VERSION ""

NS_ :

BS_:

BU_: BMS ECC EVBUS_Virtual_ECU GW OBC VCU

BO_ 870 MCU_R_0x366: 8 GW
 SG_ MCU_R_SecuStsChkFlt : 1|1@0+ (1,0) [0|1] ""  EVBUS_Virtual_ECU
 SG_ MCU_R_HVActvDchaFlt : 2|1@0+ (1,0) [0|1] ""  EVBUS_Virtual_ECU
 SG_ MCU_R_CtrlPanTChkCircFlt : 6|1@0+ (1,0) [0|1] ""  EVBUS_Virtual_ECU
 SG_ MCU_R_ComLostFlt_VCU : 7|1@0+ (1,0) [0|1] ""  EVBUS_Virtual_ECU
 SG_ MCU_R_E2EFlt : 8|1@0+ (1,0) [0|1] ""  EVBUS_Virtual_ECU
 SG_ MCU_R_I2TFlt : 9|1@0+ (1,0) [0|1] ""  EVBUS_Virtual_ECU
 SG_ MCU_R_OperModFlt : 10|1@0+ (1,0) [0|1] ""  EVBUS_Virtual_ECU
 SG_ MCU_R_CooltOverTFlt : 11|1@0+ (1,0) [0|1] ""  EVBUS_Virtual_ECU
 SG_ MCU_R_PhaCrtSampleCircFltU : 17|1@0+ (1,0) [0|1] ""  EVBUS_Virtual_ECU
 SG_ MCU_R_PhaCrtSampleCircFltV : 19|1@0+ (1,0) [0|1] ""  EVBUS_Virtual_ECU
 SG_ MCU_R_PhaCrtSampleCircFltW : 20|1@0+ (1,0) [0|1] ""  EVBUS_Virtual_ECU
 SG_ MCU_R_ThreePhaCrtChkFlt : 21|1@0+ (1,0) [0|1] ""  EVBUS_Virtual_ECU
 SG_ MCU_R_DCBusUnderVoltFlt : 22|1@0+ (1,0) [0|1] ""  EVBUS_Virtual_ECU
 SG_ MCU_R_DCBusOverVoltFlt : 23|1@0+ (1,0) [0|1] ""  EVBUS_Virtual_ECU
 SG_ MCU_R_PosnSnsrChkCircFlt : 25|1@0+ (1,0) [0|1] ""  EVBUS_Virtual_ECU
 SG_ MCU_R_DCBusVoltSampleCircFlt : 26|1@0+ (1,0) [0|1] ""  EVBUS_Virtual_ECU
 SG_ MCU_R_OverSpdFlt : 27|1@0+ (1,0) [0|1] ""  EVBUS_Virtual_ECU
 SG_ MCU_R_IGBTOverTFltU : 28|1@0+ (1,0) [0|1] ""  ECC
 SG_ MCU_R_IGBTTChkCircFltU : 29|1@0+ (1,0) [0|1] ""  ECC
 SG_ MCU_R_IGBTTChkCircFltV : 32|1@0+ (1,0) [0|1] ""  ECC
 SG_ MCU_R_IGBTTChkCircFltW : 33|1@0+ (1,0) [0|1] ""  ECC
 SG_ MCU_R_OverTFlt : 34|1@0+ (1,0) [0|1] ""  ECC
 SG_ MCU_R_TChkCircFlt : 35|1@0+ (1,0) [0|1] ""  ECC
 SG_ MCU_R_CtrlPanOverTFlt : 36|1@0+ (1,0) [0|1] ""  ECC
 SG_ MCU_R_LVPwrSplyUnderVoltFlt : 38|1@0+ (1,0) [0|1] ""  EVBUS_Virtual_ECU
 SG_ MCU_R_LVPwrSplyOverVoltFlt : 39|1@0+ (1,0) [0|1] ""  EVBUS_Virtual_ECU
 SG_ MCU_R_FbTqStsChkFlt : 40|1@0+ (1,0) [0|1] ""  EVBUS_Virtual_ECU
 SG_ MCU_R_PhaCrtSwOverCrtFltU : 42|1@0+ (1,0) [0|1] ""  EVBUS_Virtual_ECU
 SG_ MCU_R_TqCmdOverLimFlt : 43|1@0+ (1,0) [0|1] ""  ECC
 SG_ MCU_R_PwrSplyModFlt : 44|1@0+ (1,0) [0|1] ""  EVBUS_Virtual_ECU
 SG_ MCU_R_IGBTThreePhaTChkFlt : 45|1@0+ (1,0) [0|1] ""  EVBUS_Virtual_ECU
 SG_ MCU_R_RotCalFlt : 46|1@0+ (1,0) [0|1] ""  EVBUS_Virtual_ECU
 SG_ MCU_R_IntComFlt : 47|1@0+ (1,0) [0|1] ""  EVBUS_Virtual_ECU
 SG_ MCU_R_IntTqChkFlt : 48|1@0+ (1,0) [0|1] ""  EVBUS_Virtual_ECU
 SG_ MCU_R_IGBTDesatFltTop : 49|1@0+ (1,0) [0|1] ""  EVBUS_Virtual_ECU
 SG_ MCU_R_IGBTDesatFltBot : 50|1@0+ (1,0) [0|1] ""  EVBUS_Virtual_ECU
 SG_ MCU_R_PhaCrtSwOverCrtFltV : 52|1@0+ (1,0) [0|1] ""  EVBUS_Virtual_ECU
 SG_ MCU_R_PhaCrtSwOverCrtFltW : 53|1@0+ (1,0) [0|1] ""  EVBUS_Virtual_ECU
 SG_ MCU_R_IGBTOverTFltV : 54|1@0+ (1,0) [0|1] ""  EVBUS_Virtual_ECU
 SG_ MCU_R_IGBTOverTFltW : 55|1@0+ (1,0) [0|1] ""  EVBUS_Virtual_ECU

BO_ 880 BMS_HVBatt_Status_Errors_3_TBOX: 8 BMS
 SG_ BMS_PwrBattOverChrgAlrm : 0|1@0+ (1,0) [0|1] ""  GW,VCU
 SG_ BMS_PwrBattUderVoltFlt : 1|1@0+ (1,0) [0|1] ""  GW,VCU
 SG_ BMS_CellUnderVoltFailFlt : 2|1@0+ (1,0) [0|1] ""  GW,VCU
 SG_ BMS_CellUnderVoltFlt : 3|1@0+ (1,0) [0|1] ""  GW,VCU
 SG_ BMS_BattBalActv : 4|1@0+ (1,0) [0|1] ""  GW,VCU
 SG_ BMS_BattPack1OverVoltFlt : 5|1@0+ (1,0) [0|1] ""  GW,VCU
 SG_ BMS_BattPack1UnderVoltFlt : 6|1@0+ (1,0) [0|1] ""  GW,VCU
 SG_ BMS_DCChrgSoktOverTFlt : 7|1@0+ (1,0) [0|1] ""  GW,VCU
 SG_ BMS_ComLostFlt_BOBC : 8|1@0+ (1,0) [0|1] ""  GW,VCU
 SG_ BMS_ComLostFlt_CCU : 9|1@0+ (1,0) [0|1] ""  GW,VCU
 SG_ BMS_ACChrgSoktOverTFlt : 10|1@0+ (1,0) [0|1] ""  GW,VCU
 SG_ BMS_ACCrtFlt : 11|1@0+ (1,0) [0|1] ""  GW,VCU
 SG_ BMS_InsulChkFltLvl2ProtFlg : 12|1@0+ (1,0) [0|1] ""  GW,VCU
 SG_ BMS_PwrBattOverTAlrm : 13|1@0+ (1,0) [0|1] ""  GW,VCU
 SG_ BMS_PwrBattHLVIntlkFlt : 15|1@0+ (1,0) [0|1] ""  GW,VCU
 SG_ BMS_PwrBattExtShoCirc : 16|1@0+ (1,0) [0|1] ""  GW,VCU
 SG_ BMS_PwrBattIntShoCirc : 17|1@0+ (1,0) [0|1] ""  GW,VCU
 SG_ BMS_PwrBattTUnbal : 18|1@0+ (1,0) [0|1] ""  GW,VCU
 SG_ BMS_PwrBattTRiseFast : 19|1@0+ (1,0) [0|1] ""  GW,VCU
 SG_ BMS_PwrBattIntTotVoltChkFlt : 20|1@0+ (1,0) [0|1] ""  GW,VCU
 SG_ BMS_PwrBattExtTotVoltChkFlt : 21|1@0+ (1,0) [0|1] ""  GW,VCU
 SG_ BMS_PwrBattNegRlyAdh : 22|1@0+ (1,0) [0|1] ""  GW,VCU
 SG_ BMS_PwrBattPrecRlyAdh : 23|1@0+ (1,0) [0|1] ""  GW,VCU
 SG_ BMS_PwrBattPosRlyAdh : 24|1@0+ (1,0) [0|1] ""  GW,VCU
 SG_ BMS_PwrBattNegRlyBreak : 25|1@0+ (1,0) [0|1] ""  GW,VCU
 SG_ BMS_PwrBattPrecRlyBreak : 26|1@0+ (1,0) [0|1] ""  GW,VCU
 SG_ BMS_PwrBattPosRlyBreak : 27|1@0+ (1,0) [0|1] ""  GW,VCU
 SG_ BMS_PwrBattPrecRBreak : 28|1@0+ (1,0) [0|1] ""  GW,VCU
 SG_ BMS_PwrBattMSDBreak : 29|1@0+ (1,0) [0|1] ""  GW,VCU
 SG_ BMS_PwrBattExtTotVoltChkFltV2 : 30|1@0+ (1,0) [0|1] ""  GW,VCU
 SG_ BMS_BCUEEPROMReadWrFlt : 31|1@0+ (1,0) [0|1] ""  GW,VCU
 SG_ BMS_PwrBattPosRlyDrvChFlt : 32|1@0+ (1,0) [0|1] ""  GW,VCU
 SG_ BMS_PwrBattPrecRlyDrvChFlt : 33|1@0+ (1,0) [0|1] ""  GW,VCU
 SG_ BMS_PwrBattInsulChkFlt : 34|1@0+ (1,0) [0|1] ""  GW,VCU
 SG_ BMS_PwrBattNegRlyDrvChFlt : 35|1@0+ (1,0) [0|1] ""  GW,VCU
 SG_ BMS_PwrBattCellVoltUnbal : 36|1@0+ (1,0) [0|1] ""  GW,VCU
 SG_ BMS_EEPROMReadWrFlt : 37|1@0+ (1,0) [0|1] ""  GW,VCU
 SG_ BMS_PwrBattSysIntComFlt : 39|2@0+ (1,0) [0|3] ""  GW,VCU
 SG_ BMS_InsulRLo : 40|1@0+ (1,0) [0|1] ""  GW,VCU
 SG_ BMS_CopRowLooseFlt : 41|1@0+ (1,0) [0|1] ""  GW,VCU
 SG_ BMS_SubEEPROMReadWrFlt : 42|1@0+ (1,0) [0|1] ""  GW,VCU
 SG_ BMS_SubCellVoltCollctnCircFlt : 44|2@0+ (1,0) [0|3] ""  GW,VCU
 SG_ BMS_SubModleVoltCollctnCircFlt : 45|1@0+ (1,0) [0|1] ""  GW,VCU
 SG_ BMS_SubTCollctnCircFlt : 47|2@0+ (1,0) [0|3] ""  GW,VCU
 SG_ BMS_SubActvBalChFlt : 48|1@0+ (1,0) [0|1] ""  GW,VCU
 SG_ BMS_SubPasBalChFlt : 49|1@0+ (1,0) [0|1] ""  GW,VCU
 SG_ BMS_SubOperModRespFlt : 50|1@0+ (1,0) [0|1] ""  GW,VCU
 SG_ BMS_BattCellVoltUnbalAlrm : 51|1@0+ (1,0) [0|1] ""  GW,VCU
 SG_ BMS_ComLostFlt_ECC : 52|1@0+ (1,0) [0|1] ""  GW,VCU
 SG_ BMS_SubComLostFlt_VBUBMS : 53|1@0+ (1,0) [0|1] ""  GW,VCU
 SG_ BMS_PrecFailFlt : 54|1@0+ (1,0) [0|1] ""  GW,VCU
 SG_ BMS_PwrBattCellOverVolt : 55|1@0+ (1,0) [0|1] ""  GW,VCU
 SG_ BMS_TotVoltOver : 56|1@0+ (1,0) [0|1] ""  GW,VCU
 SG_ BMS_PwrBattIntTotVoltChkFltV1 : 57|1@0+ (1,0) [0|1] ""  GW,VCU
 SG_ BMS_TotCrtChkFlt : 58|1@0+ (1,0) [0|1] ""  GW,VCU
 SG_ BMS_ComLostFlt_VCU : 59|1@0+ (1,0) [0|1] ""  GW,VCU
 SG_ BMS_BattReDrvHLVIntlkFlt : 60|1@0+ (1,0) [0|1] ""  GW,VCU
 SG_ BMS_ComOverTiFlt_ECC : 61|1@0+ (1,0) [0|1] ""  GW,VCU
 SG_ BMS_LVPwrSplyFlt : 62|1@0+ (1,0) [0|1] ""  GW,VCU
 SG_ BMS_ComOverTiFlt_BOBC : 63|1@0+ (1,0) [0|1] ""  GW,VCU

BO_ 881 WTC_B_0x371: 8 ECC
 SG_ WTC_B_PCBT : 23|8@0+ (1,-48) [-48|207] ""  GW
 SG_ WTC_B_Crt : 31|16@0+ (0.001,0) [0|65.534] "A"  GW,VCU
 SG_ WTC_B_CrtSts : 41|2@0+ (1,0) [0|3] ""  GW,VCU
 SG_ WTC_B_HVIntlkFlt : 42|1@0+ (1,0) [0|1] ""  GW,VCU
 SG_ WTC_B_ComLost_ECC : 43|1@0+ (1,0) [0|1] ""  GW
 SG_ WTC_B_OverCrtFlt : 44|1@0+ (1,0) [0|1] ""  GW
 SG_ WTC_B_HVUnderVoltFlt : 45|1@0+ (1,0) [0|1] ""  GW
 SG_ WTC_B_HVOverVoltFlt : 46|1@0+ (1,0) [0|1] ""  GW
 SG_ WTC_B_ChkBattOverVoltFlt : 47|1@0+ (1,0) [0|1] ""  GW
 SG_ WTC_B_ChkBattUnderVoltFlt : 48|1@0+ (1,0) [0|1] ""  GW
 SG_ WTC_B_InlTSnsrFlt : 49|1@0+ (1,0) [0|1] ""  GW
 SG_ WTC_B_OutlTSnsrFlt : 50|1@0+ (1,0) [0|1] ""  GW
 SG_ WTC_B_InlOverTFlt : 51|1@0+ (1,0) [0|1] ""  GW
 SG_ WTC_B_OutlOverTFlt : 52|1@0+ (1,0) [0|1] ""  GW
 SG_ WTC_B_PCBOverTFlt : 53|1@0+ (1,0) [0|1] ""  GW
 SG_ WTC_B_PCBTSnsrFlt : 54|1@0+ (1,0) [0|1] ""  GW
 SG_ WTC_B_PwrOutpFlt : 55|1@0+ (1,0) [0|1] ""  GW

BO_ 882 BMS_CellTemp_CoolingHeating: 16 BMS
 SG_ BMS_372_382_CheckSum : 7|8@0+ (1,0) [0|255] ""  ECC,GW,VCU
 SG_ BMS_372_382_AliveCounter : 11|4@0+ (1,0) [0|14] ""  ECC,GW,VCU
 SG_ BMS_OTARdy_Fb : 13|2@0+ (1,0) [0|3] ""  GW
 SG_ BMS_CellMinT : 23|8@0+ (1,-48) [-48|207] "Degree Celsius"  ECC,GW,VCU
 SG_ BMS_CellDiffT : 31|8@0+ (1,0) [0|255] "Degree Celsius"  ECC,GW,VCU
 SG_ BMS_CellMaxT : 39|8@0+ (1,-48) [-48|207] "Degree Celsius"  ECC,GW,VCU
 SG_ BMS_BattAvrgT : 47|8@0+ (1,-48) [-48|207] "Degree Celsius"  ECC,GW,VCU
 SG_ BMS_PwrBattHeatgMngDmd : 49|2@0+ (1,0) [0|3] ""  ECC,GW,VCU
 SG_ BMS_ECCSysAllwDwnPwrCmd : 50|1@0+ (1,0) [0|1] ""  ECC,GW
 SG_ BMS_BattInlTDmd : 63|8@0+ (1,-48) [-48|207] ""  ECC,GW
 SG_ BMS_372_SSecOC_Fresh_Byte0 : 71|8@0+ (1,0) [0|255] ""  GW,VCU
 SG_ BMS_372_SSecOC_MAC_Byte0 : 79|8@0+ (1,0) [0|255] ""  GW,VCU
 SG_ BMS_372_SSecOC_MAC_Byte1 : 87|8@0+ (1,0) [0|255] ""  GW,VCU
 SG_ BMS_372_SSecOC_MAC_Byte2 : 95|8@0+ (1,0) [0|255] ""  GW,VCU

BO_ 883 ECC_0x373: 8 ECC
 SG_ ECC_CrtSts : 3|4@0+ (1,0) [0|15] ""  GW,VCU
 SG_ ECC_IninSts : 4|1@0+ (1,0) [0|1] ""  GW,VCU
 SG_ ECC_PwrSysHeatMngtSts : 6|2@0+ (1,0) [0|3] ""  GW,VCU
 SG_ ECC_ACSts : 7|1@0+ (1,0) [0|1] ""  GW,VCU
 SG_ ECC_AirClnSts : 8|1@0+ (1,0) [0|1] ""  GW,VCU
 SG_ ECC_WindSpdSts : 12|4@0+ (1,0) [0|15] ""  BMS,GW,VCU
 SG_ ECC_BackRowAirOutlModSts : 15|3@0+ (1,0) [0|7] ""  GW,VCU
 SG_ ECC_DrvrTSetSts : 23|8@0+ (0.5,0) [0|127.5] ""  GW,VCU
 SG_ ECC_PassTSetSts : 31|8@0+ (0.5,0) [0|127.5] ""  GW,VCU
 SG_ ECC_HeatSts : 32|1@0+ (1,0) [0|1] ""  BMS,GW,VCU
 SG_ ECC_AUTOSts : 33|1@0+ (1,0) [0|1] ""  GW,VCU
 SG_ ECC_SYNCSts : 34|1@0+ (1,0) [0|1] ""  GW,VCU
 SG_ ECC_InfoSysWrmColdDisp : 36|2@0+ (1,0) [0|3] ""  GW,VCU
 SG_ ECC_CircSts : 37|1@0+ (1,0) [0|1] ""  GW,VCU
 SG_ ECC_ParticleConcVld : 39|2@0+ (1,0) [0|3] ""  GW,VCU
 SG_ ECC_OutdT : 47|8@0+ (0.5,-48) [-48|79.5] "Degree Celsius"  BMS,GW,VCU
 SG_ ECC_OutdTVld : 49|2@0+ (1,0) [0|3] ""  BMS,GW,VCU
 SG_ ECC_MaxFrntDefrst : 50|1@0+ (1,0) [0|1] ""  GW,VCU
 SG_ ECC_HeatMngtSysFlt : 51|1@0+ (1,0) [0|1] ""  GW,VCU
 SG_ ECC_HeatMngtFctLim : 52|1@0+ (1,0) [0|1] ""  GW,VCU
 SG_ ECC_DrvrAirOutlMod : 55|3@0+ (1,0) [0|7] ""  GW,VCU
 SG_ ECC_PassAirOutlMod : 58|3@0+ (1,0) [0|7] ""  GW,VCU
 SG_ ECC_RemSts : 60|2@0+ (1,0) [0|3] ""  GW,VCU
 SG_ ECC_OTAInhbRdy : 62|2@0+ (1,0) [0|3] ""  GW,VCU

BO_ 884 WTC_H_0x374: 8 ECC
 SG_ WTC_H_PCBT : 23|8@0+ (1,-48) [-48|207] ""  GW
 SG_ WTC_H_Crt : 31|16@0+ (0.001,0) [0|65.534] "A"  GW,VCU
 SG_ WTC_H_CrtSts : 41|2@0+ (1,0) [0|3] ""  GW,VCU
 SG_ WTC_H_HVIntlkFlt : 42|1@0+ (1,0) [0|1] ""  GW,VCU
 SG_ WTC_H_ComLost_ECC : 43|1@0+ (1,0) [0|1] ""  GW
 SG_ WTC_H_OverCrtFlt : 44|1@0+ (1,0) [0|1] ""  GW
 SG_ WTC_H_HVUnderVoltFlt : 45|1@0+ (1,0) [0|1] ""  GW
 SG_ WTC_H_HVOverVoltFlt : 46|1@0+ (1,0) [0|1] ""  GW
 SG_ WTC_H_ChkBattOverVoltFlt : 47|1@0+ (1,0) [0|1] ""  GW
 SG_ WTC_H_ChkBattUnderVoltFlt : 48|1@0+ (1,0) [0|1] ""  GW
 SG_ WTC_H_InlTSnsrFlt : 49|1@0+ (1,0) [0|1] ""  GW
 SG_ WTC_H_OutlTSnsrFlt : 50|1@0+ (1,0) [0|1] ""  GW
 SG_ WTC_H_InlOverTFlt : 51|1@0+ (1,0) [0|1] ""  GW
 SG_ WTC_H_OutlOverTFlt : 52|1@0+ (1,0) [0|1] ""  GW
 SG_ WTC_H_PCBOverTFlt : 53|1@0+ (1,0) [0|1] ""  GW
 SG_ WTC_H_PCBTSnsrFlt : 54|1@0+ (1,0) [0|1] ""  GW
 SG_ WTC_H_PwrOutpFlt : 55|1@0+ (1,0) [0|1] ""  GW

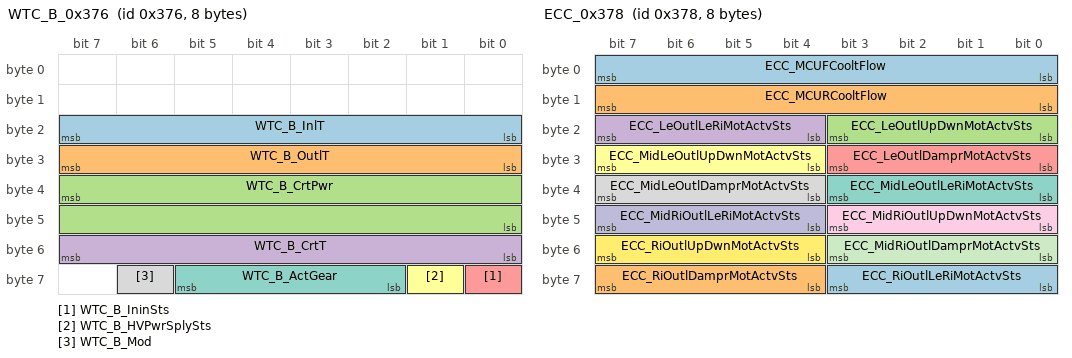
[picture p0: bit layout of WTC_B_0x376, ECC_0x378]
BO_ 886 WTC_B_0x376: 8 ECC
 SG_ WTC_B_InlT : 23|8@0+ (1,-48) [-48|207] "Degree Celsius"  GW
 SG_ WTC_B_OutlT : 31|8@0+ (1,-48) [-48|207] "Degree Celsius"  GW
 SG_ WTC_B_CrtPwr : 39|16@0+ (1,0) [0|10000] ""  GW,VCU
 SG_ WTC_B_CrtT : 55|8@0+ (1,-48) [-48|207] "Degree Celsius"  GW
 SG_ WTC_B_IninSts : 56|1@0+ (1,0) [0|1] ""  GW
 SG_ WTC_B_HVPwrSplySts : 57|1@0+ (1,0) [0|1] ""  GW
 SG_ WTC_B_ActGear : 61|4@0+ (1,0) [0|15] ""  GW
 SG_ WTC_B_Mod : 62|1@0+ (1,0) [0|1] ""  BMS,GW,VCU

BO_ 888 ECC_0x378: 8 ECC
 SG_ ECC_MCUFCooltFlow : 7|8@0+ (0.1,0) [0|25.5] "L/min"  GW
 SG_ ECC_MCURCooltFlow : 15|8@0+ (0.1,0) [0|25.5] "L/min"  GW
 SG_ ECC_LeOutlUpDwnMotActvSts : 19|4@0+ (1,0) [0|15] ""  GW
 SG_ ECC_LeOutlLeRiMotActvSts : 23|4@0+ (1,0) [0|15] ""  GW
 SG_ ECC_LeOutlDamprMotActvSts : 27|4@0+ (1,0) [0|15] ""  GW
 SG_ ECC_MidLeOutlUpDwnMotActvSts : 31|4@0+ (1,0) [0|15] ""  GW
 SG_ ECC_MidLeOutlLeRiMotActvSts : 35|4@0+ (1,0) [0|15] ""  GW
 SG_ ECC_MidLeOutlDamprMotActvSts : 39|4@0+ (1,0) [0|15] ""  GW
 SG_ ECC_MidRiOutlUpDwnMotActvSts : 43|4@0+ (1,0) [0|15] ""  GW
 SG_ ECC_MidRiOutlLeRiMotActvSts : 47|4@0+ (1,0) [0|15] ""  GW
 SG_ ECC_MidRiOutlDamprMotActvSts : 51|4@0+ (1,0) [0|15] ""  GW
 SG_ ECC_RiOutlUpDwnMotActvSts : 55|4@0+ (1,0) [0|15] ""  GW
 SG_ ECC_RiOutlLeRiMotActvSts : 59|4@0+ (1,0) [0|15] ""  GW
 SG_ ECC_RiOutlDamprMotActvSts : 63|4@0+ (1,0) [0|15] ""  GW

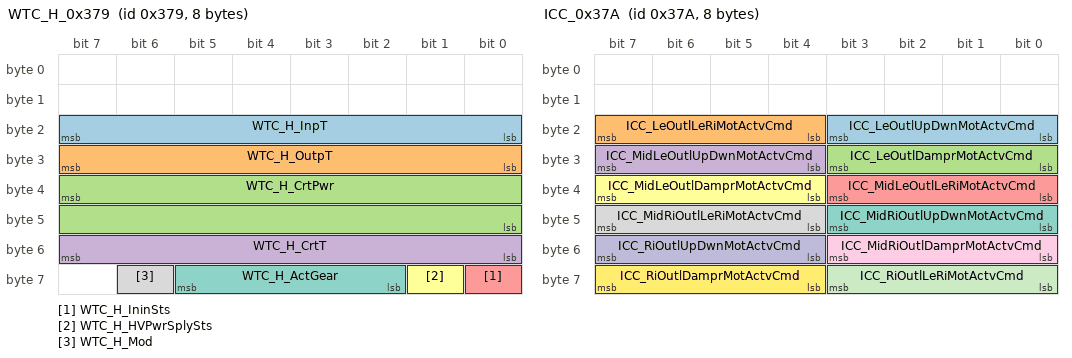
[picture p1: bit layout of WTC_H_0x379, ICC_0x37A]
BO_ 889 WTC_H_0x379: 8 ECC
 SG_ WTC_H_InpT : 23|8@0+ (1,-48) [-48|207] "Degree Celsius"  GW
 SG_ WTC_H_OutpT : 31|8@0+ (1,-48) [-48|207] "Degree Celsius"  GW
 SG_ WTC_H_CrtPwr : 39|16@0+ (1,0) [0|10000] ""  GW,VCU
 SG_ WTC_H_CrtT : 55|8@0+ (1,-48) [-48|207] "Degree Celsius"  GW
 SG_ WTC_H_IninSts : 56|1@0+ (1,0) [0|1] ""  GW
 SG_ WTC_H_HVPwrSplySts : 57|1@0+ (1,0) [0|1] ""  GW
 SG_ WTC_H_ActGear : 61|4@0+ (1,0) [0|15] ""  GW
 SG_ WTC_H_Mod : 62|1@0+ (1,0) [0|1] ""  BMS,GW,VCU

BO_ 890 ICC_0x37A: 8 GW
 SG_ ICC_LeOutlUpDwnMotActvCmd : 19|4@0+ (1,0) [0|15] ""  ECC
 SG_ ICC_LeOutlLeRiMotActvCmd : 23|4@0+ (1,0) [0|15] ""  ECC
 SG_ ICC_LeOutlDamprMotActvCmd : 27|4@0+ (1,0) [0|15] ""  ECC
 SG_ ICC_MidLeOutlUpDwnMotActvCmd : 31|4@0+ (1,0) [0|15] ""  ECC
 SG_ ICC_MidLeOutlLeRiMotActvCmd : 35|4@0+ (1,0) [0|15] ""  ECC
 SG_ ICC_MidLeOutlDamprMotActvCmd : 39|4@0+ (1,0) [0|15] ""  ECC
 SG_ ICC_MidRiOutlUpDwnMotActvCmd : 43|4@0+ (1,0) [0|15] ""  ECC
 SG_ ICC_MidRiOutlLeRiMotActvCmd : 47|4@0+ (1,0) [0|15] ""  ECC
 SG_ ICC_MidRiOutlDamprMotActvCmd : 51|4@0+ (1,0) [0|15] ""  ECC
 SG_ ICC_RiOutlUpDwnMotActvCmd : 55|4@0+ (1,0) [0|15] ""  ECC
 SG_ ICC_RiOutlLeRiMotActvCmd : 59|4@0+ (1,0) [0|15] ""  ECC
 SG_ ICC_RiOutlDamprMotActvCmd : 63|4@0+ (1,0) [0|15] ""  ECC

BO_ 891 PKC_0x37B: 16 GW
 SG_ PKC_SysAlrmVld : 16|1@0+ (1,0) [0|1] ""  EVBUS_Virtual_ECU
 SG_ PKC_RemCtrlCmdFb : 18|2@0+ (1,0) [0|3] ""  EVBUS_Virtual_ECU
 SG_ PKC_RemLockCmd_Key : 22|4@0+ (1,0) [0|15] ""  ECC,VCU
 SG_ PKC_KeyStsMod : 23|1@0+ (1,0) [0|1] ""  EVBUS_Virtual_ECU
 SG_ PKC_KeyID : 31|8@0+ (1,0) [0|255] ""  EVBUS_Virtual_ECU
 SG_ PKC_KeyInCarRmn : 35|1@0+ (1,0) [0|1] ""  EVBUS_Virtual_ECU
 SG_ PKC_RemLockCmd : 39|4@0+ (1,0) [0|15] ""  VCU
 SG_ PKC_BatterySts : 45|2@0+ (1,0) [0|3] ""  EVBUS_Virtual_ECU
 SG_ PKC_KeyOutdCarPromt : 46|1@0+ (1,0) [0|1] ""  EVBUS_Virtual_ECU
 SG_ PKC_DoorOpenRmd : 49|2@0+ (1,0) [0|3] ""  EVBUS_Virtual_ECU
 SG_ PKC_StrtFailTyp : 53|4@0+ (1,0) [0|15] ""  EVBUS_Virtual_ECU
 SG_ PKC_LockKeyInCarInd : 55|2@0+ (1,0) [0|3] ""  EVBUS_Virtual_ECU
 SG_ PKC_KeySts : 63|8@0+ (1,0) [0|255] ""  EVBUS_Virtual_ECU
 SG_ PKC_37B_SSecOC_Fresh_Byte0 : 71|8@0+ (1,0) [0|255] ""  VCU
 SG_ PKC_37B_SSecOC_MAC_Byte0 : 79|8@0+ (1,0) [0|255] ""  VCU
 SG_ PKC_37B_SSecOC_MAC_Byte1 : 87|8@0+ (1,0) [0|255] ""  VCU
 SG_ PKC_37B_SSecOC_MAC_Byte2 : 95|8@0+ (1,0) [0|255] ""  VCU

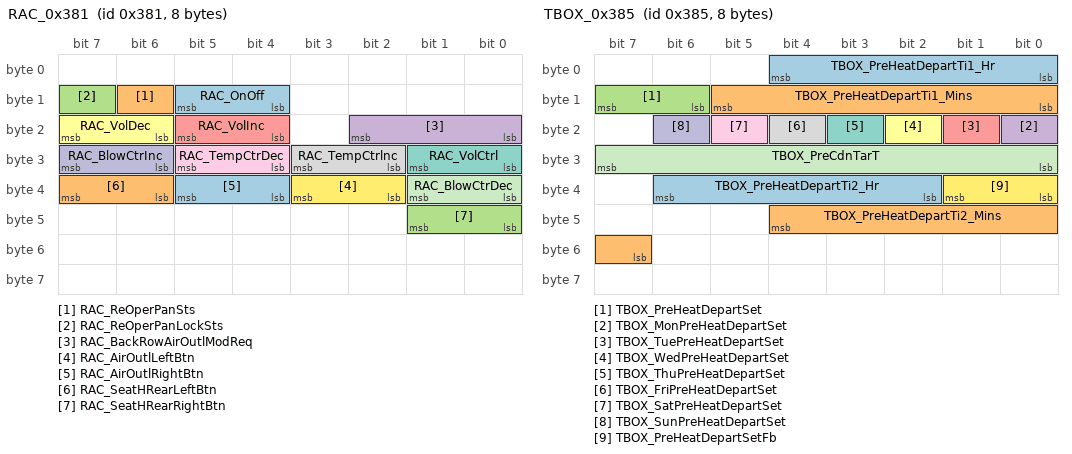
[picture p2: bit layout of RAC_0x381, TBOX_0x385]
BO_ 897 RAC_0x381: 8 GW
 SG_ RAC_OnOff : 13|2@0+ (1,0) [0|3] ""  EVBUS_Virtual_ECU
 SG_ RAC_ReOperPanSts : 14|1@0+ (1,0) [0|1] ""  ECC
 SG_ RAC_ReOperPanLockSts : 15|1@0+ (1,0) [0|1] ""  ECC
 SG_ RAC_BackRowAirOutlModReq : 18|3@0+ (1,0) [0|7] ""  ECC
 SG_ RAC_VolInc : 21|2@0+ (1,0) [0|3] ""  EVBUS_Virtual_ECU
 SG_ RAC_VolDec : 23|2@0+ (1,0) [0|3] ""  EVBUS_Virtual_ECU
 SG_ RAC_VolCtrl : 25|2@0+ (1,0) [0|3] ""  EVBUS_Virtual_ECU
 SG_ RAC_TempCtrlnc : 27|2@0+ (1,0) [0|3] ""  EVBUS_Virtual_ECU
 SG_ RAC_TempCtrDec : 29|2@0+ (1,0) [0|3] ""  EVBUS_Virtual_ECU
 SG_ RAC_BlowCtrInc : 31|2@0+ (1,0) [0|3] ""  EVBUS_Virtual_ECU
 SG_ RAC_BlowCtrDec : 33|2@0+ (1,0) [0|3] ""  EVBUS_Virtual_ECU
 SG_ RAC_AirOutlLeftBtn : 35|2@0+ (1,0) [0|3] ""  EVBUS_Virtual_ECU
 SG_ RAC_AirOutlRightBtn : 37|2@0+ (1,0) [0|3] ""  EVBUS_Virtual_ECU
 SG_ RAC_SeatHRearLeftBtn : 39|2@0+ (1,0) [0|3] ""  EVBUS_Virtual_ECU
 SG_ RAC_SeatHRearRightBtn : 41|2@0+ (1,0) [0|3] ""  EVBUS_Virtual_ECU

BO_ 901 TBOX_0x385: 8 GW
 SG_ TBOX_PreHeatDepartTi1_Hr : 4|5@0+ (1,0) [0|23] ""  EVBUS_Virtual_ECU
 SG_ TBOX_PreHeatDepartTi1_Mins : 13|6@0+ (1,0) [0|59] ""  EVBUS_Virtual_ECU
 SG_ TBOX_PreHeatDepartSet : 15|2@0+ (1,0) [0|3] ""  EVBUS_Virtual_ECU
 SG_ TBOX_MonPreHeatDepartSet : 16|1@0+ (1,0) [0|1] ""  EVBUS_Virtual_ECU
 SG_ TBOX_TuePreHeatDepartSet : 17|1@0+ (1,0) [0|1] ""  EVBUS_Virtual_ECU
 SG_ TBOX_WedPreHeatDepartSet : 18|1@0+ (1,0) [0|1] ""  EVBUS_Virtual_ECU
 SG_ TBOX_ThuPreHeatDepartSet : 19|1@0+ (1,0) [0|1] ""  EVBUS_Virtual_ECU
 SG_ TBOX_FriPreHeatDepartSet : 20|1@0+ (1,0) [0|1] ""  EVBUS_Virtual_ECU
 SG_ TBOX_SatPreHeatDepartSet : 21|1@0+ (1,0) [0|1] ""  EVBUS_Virtual_ECU
 SG_ TBOX_SunPreHeatDepartSet : 22|1@0+ (1,0) [0|1] ""  EVBUS_Virtual_ECU
 SG_ TBOX_PreCdnTarT : 31|8@0+ (0.5,0) [-48|255] "Degree Celsius"  VCU
 SG_ TBOX_PreHeatDepartSetFb : 33|2@0+ (1,0) [0|3] ""  EVBUS_Virtual_ECU
 SG_ TBOX_PreHeatDepartTi2_Hr : 38|5@0+ (1,0) [0|23] ""  EVBUS_Virtual_ECU
 SG_ TBOX_PreHeatDepartTi2_Mins : 44|6@0+ (1,0) [0|59] ""  EVBUS_Virtual_ECU

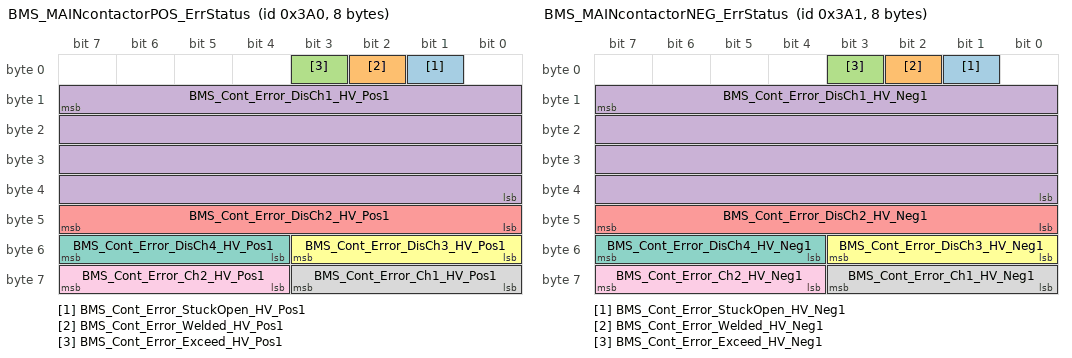
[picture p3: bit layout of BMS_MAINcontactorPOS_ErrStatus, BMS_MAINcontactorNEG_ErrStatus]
BO_ 928 BMS_MAINcontactorPOS_ErrStatus: 8 BMS
 SG_ BMS_Cont_Error_StuckOpen_HV_Pos1 : 1|1@0+ (1,0) [0|1] ""  GW,VCU
 SG_ BMS_Cont_Error_Welded_HV_Pos1 : 2|1@0+ (1,0) [0|1] ""  GW,VCU
 SG_ BMS_Cont_Error_Exceed_HV_Pos1 : 3|1@0+ (1,0) [0|1] ""  GW,VCU
 SG_ BMS_Cont_Error_DisCh1_HV_Pos1 : 15|32@0+ (1,0) [0|4294967295] ""  GW,VCU
 SG_ BMS_Cont_Error_DisCh2_HV_Pos1 : 47|8@0+ (1,0) [0|255] ""  GW,VCU
 SG_ BMS_Cont_Error_DisCh3_HV_Pos1 : 51|4@0+ (1,0) [0|15] ""  GW,VCU
 SG_ BMS_Cont_Error_DisCh4_HV_Pos1 : 55|4@0+ (1,0) [0|15] ""  GW,VCU
 SG_ BMS_Cont_Error_Ch1_HV_Pos1 : 59|4@0+ (1,0) [0|15] ""  GW,VCU
 SG_ BMS_Cont_Error_Ch2_HV_Pos1 : 63|4@0+ (1,0) [0|15] ""  GW,VCU

BO_ 929 BMS_MAINcontactorNEG_ErrStatus: 8 BMS
 SG_ BMS_Cont_Error_StuckOpen_HV_Neg1 : 1|1@0+ (1,0) [0|1] ""  GW,VCU
 SG_ BMS_Cont_Error_Welded_HV_Neg1 : 2|1@0+ (1,0) [0|1] ""  GW,VCU
 SG_ BMS_Cont_Error_Exceed_HV_Neg1 : 3|1@0+ (1,0) [0|1] ""  GW,VCU
 SG_ BMS_Cont_Error_DisCh1_HV_Neg1 : 15|32@0+ (1,0) [0|4294967295] ""  GW,VCU
 SG_ BMS_Cont_Error_DisCh2_HV_Neg1 : 47|8@0+ (1,0) [0|255] ""  GW,VCU
 SG_ BMS_Cont_Error_DisCh3_HV_Neg1 : 51|4@0+ (1,0) [0|15] ""  GW,VCU
 SG_ BMS_Cont_Error_DisCh4_HV_Neg1 : 55|4@0+ (1,0) [0|15] ""  GW,VCU
 SG_ BMS_Cont_Error_Ch1_HV_Neg1 : 59|4@0+ (1,0) [0|15] ""  GW,VCU
 SG_ BMS_Cont_Error_Ch2_HV_Neg1 : 63|4@0+ (1,0) [0|15] ""  GW,VCU

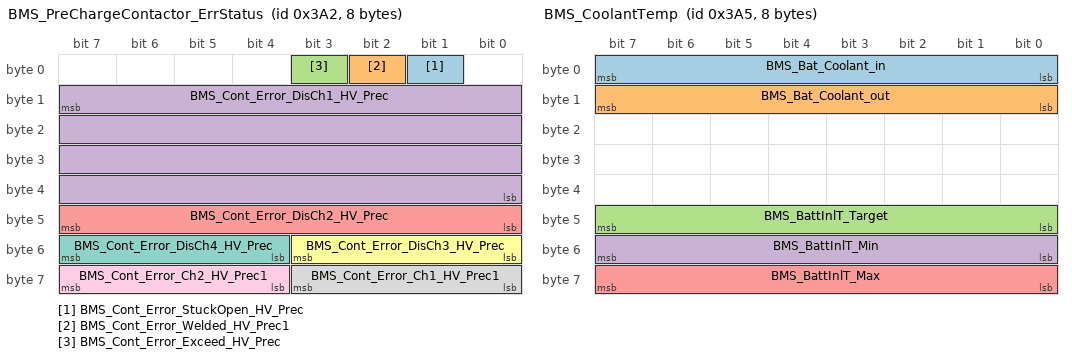
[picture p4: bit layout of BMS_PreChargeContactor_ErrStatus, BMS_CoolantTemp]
BO_ 930 BMS_PreChargeContactor_ErrStatus: 8 BMS
 SG_ BMS_Cont_Error_StuckOpen_HV_Prec : 1|1@0+ (1,0) [0|1] ""  GW,VCU
 SG_ BMS_Cont_Error_Welded_HV_Prec1 : 2|1@0+ (1,0) [0|1] ""  GW,VCU
 SG_ BMS_Cont_Error_Exceed_HV_Prec : 3|1@0+ (1,0) [0|1] ""  GW,VCU
 SG_ BMS_Cont_Error_DisCh1_HV_Prec : 15|32@0+ (1,0) [0|4294967295] ""  GW,VCU
 SG_ BMS_Cont_Error_DisCh2_HV_Prec : 47|8@0+ (1,0) [0|255] ""  GW,VCU
 SG_ BMS_Cont_Error_DisCh3_HV_Prec : 51|4@0+ (1,0) [0|15] ""  GW,VCU
 SG_ BMS_Cont_Error_DisCh4_HV_Prec : 55|4@0+ (1,0) [0|15] ""  GW,VCU
 SG_ BMS_Cont_Error_Ch1_HV_Prec1 : 59|4@0+ (1,0) [0|15] ""  GW,VCU
 SG_ BMS_Cont_Error_Ch2_HV_Prec1 : 63|4@0+ (1,0) [0|15] ""  GW,VCU

BO_ 933 BMS_CoolantTemp: 8 BMS
 SG_ BMS_Bat_Coolant_in : 7|8@0+ (0.5,-40) [-40|87.5] "Degree Celsius"  ECC,GW,VCU
 SG_ BMS_Bat_Coolant_out : 15|8@0+ (0.5,-40) [-40|87.5] "Degree Celsius"  ECC,GW,VCU
 SG_ BMS_BattInlT_Target : 47|8@0+ (1,-48) [-48|207] "Degree Celsius"  ECC,GW,VCU
 SG_ BMS_BattInlT_Min : 55|8@0+ (1,-48) [-48|207] "Degree Celsius"  ECC,GW,VCU
 SG_ BMS_BattInlT_Max : 63|8@0+ (1,-48) [-48|207] "Degree Celsius"  ECC,GW,VCU

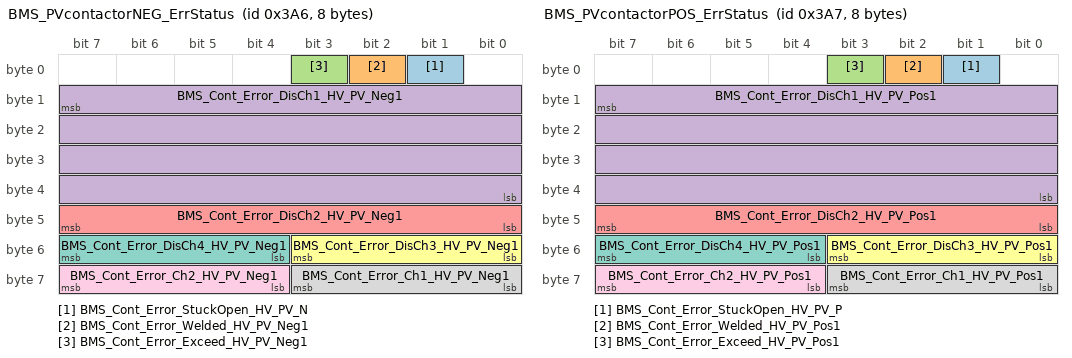
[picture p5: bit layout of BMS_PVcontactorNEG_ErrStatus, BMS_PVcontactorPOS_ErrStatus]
BO_ 934 BMS_PVcontactorNEG_ErrStatus: 8 BMS
 SG_ BMS_Cont_Error_StuckOpen_HV_PV_N : 1|1@0+ (1,0) [0|1] ""  GW,VCU
 SG_ BMS_Cont_Error_Welded_HV_PV_Neg1 : 2|1@0+ (1,0) [0|1] ""  GW,VCU
 SG_ BMS_Cont_Error_Exceed_HV_PV_Neg1 : 3|1@0+ (1,0) [0|1] ""  GW,VCU
 SG_ BMS_Cont_Error_DisCh1_HV_PV_Neg1 : 15|32@0+ (1,0) [0|4294967295] ""  GW,VCU
 SG_ BMS_Cont_Error_DisCh2_HV_PV_Neg1 : 47|8@0+ (1,0) [0|255] ""  GW,VCU
 SG_ BMS_Cont_Error_DisCh3_HV_PV_Neg1 : 51|4@0+ (1,0) [0|15] ""  GW,VCU
 SG_ BMS_Cont_Error_DisCh4_HV_PV_Neg1 : 55|4@0+ (1,0) [0|15] ""  GW,VCU
 SG_ BMS_Cont_Error_Ch1_HV_PV_Neg1 : 59|4@0+ (1,0) [0|15] ""  GW,VCU
 SG_ BMS_Cont_Error_Ch2_HV_PV_Neg1 : 63|4@0+ (1,0) [0|15] ""  GW,VCU

BO_ 935 BMS_PVcontactorPOS_ErrStatus: 8 BMS
 SG_ BMS_Cont_Error_StuckOpen_HV_PV_P : 1|1@0+ (1,0) [0|1] ""  GW,VCU
 SG_ BMS_Cont_Error_Welded_HV_PV_Pos1 : 2|1@0+ (1,0) [0|1] ""  GW,VCU
 SG_ BMS_Cont_Error_Exceed_HV_PV_Pos1 : 3|1@0+ (1,0) [0|1] ""  GW,VCU
 SG_ BMS_Cont_Error_DisCh1_HV_PV_Pos1 : 15|32@0+ (1,0) [0|4294967295] ""  GW,VCU
 SG_ BMS_Cont_Error_DisCh2_HV_PV_Pos1 : 47|8@0+ (1,0) [0|255] ""  GW,VCU
 SG_ BMS_Cont_Error_DisCh3_HV_PV_Pos1 : 51|4@0+ (1,0) [0|15] ""  GW,VCU
 SG_ BMS_Cont_Error_DisCh4_HV_PV_Pos1 : 55|4@0+ (1,0) [0|15] ""  GW,VCU
 SG_ BMS_Cont_Error_Ch1_HV_PV_Pos1 : 59|4@0+ (1,0) [0|15] ""  GW,VCU
 SG_ BMS_Cont_Error_Ch2_HV_PV_Pos1 : 63|4@0+ (1,0) [0|15] ""  GW,VCU

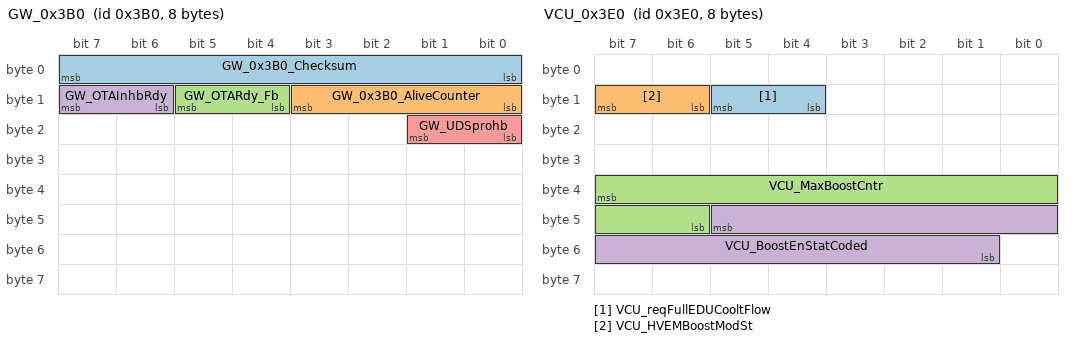
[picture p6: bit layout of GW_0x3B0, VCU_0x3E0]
BO_ 944 GW_0x3B0: 8 GW
 SG_ GW_0x3B0_Checksum : 7|8@0+ (1,0) [0|255] ""  VCU
 SG_ GW_0x3B0_AliveCounter : 11|4@0+ (1,0) [0|14] ""  VCU
 SG_ GW_OTARdy_Fb : 13|2@0+ (1,0) [0|3] ""  EVBUS_Virtual_ECU
 SG_ GW_OTAInhbRdy : 15|2@0+ (1,0) [0|3] ""  VCU
 SG_ GW_UDSprohb : 17|2@0+ (1,0) [0|3] ""  EVBUS_Virtual_ECU

BO_ 965 AMP_0x3C5: 8 GW
 SG_ AMP_OTAInhbRdy : 15|2@0+ (1,0) [0|3] ""  VCU

BO_ 992 VCU_0x3E0: 8 VCU
 SG_ VCU_reqFullEDUCooltFlow : 13|2@0+ (1,0) [0|3] ""  ECC,GW
 SG_ VCU_HVEMBoostModSt : 15|2@0+ (1,0) [0|3] ""  GW
 SG_ VCU_MaxBoostCntr : 39|10@0+ (1,0) [0|1000] ""  GW
 SG_ VCU_BoostEnStatCoded : 45|13@0+ (1,0) [0|5040] ""  GW

BO_ 1025 VCU_NM_0x401: 8 VCU
 SG_ VCU_SrcNodeID : 7|8@0+ (1,0) [0|127] ""  ECC,GW
 SG_ VCU_CtrlBitVector_Bit0_RMR : 8|1@0+ (1,0) [0|1] ""  ECC,GW
 SG_ VCU_CtrlBitVector_Bit1_Res : 9|1@0+ (1,0) [0|1] ""  ECC,GW
 SG_ VCU_CtrlBitVector_Bit2_Res : 10|1@0+ (1,0) [0|1] ""  ECC,GW
 SG_ VCU_CtrlBitVector_Bit3_NMCoord : 11|1@0+ (1,0) [0|1] ""  ECC,GW
 SG_ VCU_CtrlBitVector_Bit4_ActWake : 12|1@0+ (1,0) [0|1] ""  ECC,GW
 SG_ VCU_CtrlBitVector_Bit5_Res : 13|1@0+ (1,0) [0|1] ""  ECC,GW
 SG_ VCU_CtrlBitVector_Bit6_PNI : 14|1@0+ (1,0) [0|1] ""  ECC,GW
 SG_ VCU_CtrlBitVector_Bit7_Res : 15|1@0+ (1,0) [0|1] ""  ECC,GW
 SG_ VCU_UsrData0 : 23|8@0+ (1,0) [0|255] ""  ECC,GW
 SG_ VCU_UsrData1_Bit0_IGN_WAKEUP : 24|1@0+ (1,0) [0|1] ""  ECC,GW
 SG_ VCU_UsrData1_Bit1_RESET_WAKEUP : 25|1@0+ (1,0) [0|1] ""  ECC,GW
 SG_ VCU_UsrData1_Bit2_NETWORK_WAKEUP : 26|1@0+ (1,0) [0|1] ""  ECC,GW
 SG_ VCU_UsrData1_Bit3_ECUSPEC_WAKEUP : 27|1@0+ (1,0) [0|1] ""  ECC,GW
 SG_ VCU_UsrData1_Bit4_NETWORK_AWAKE : 28|1@0+ (1,0) [0|1] ""  ECC,GW
 SG_ VCU_UsrData1_Bit5_IGNITION_AWAKE : 29|1@0+ (1,0) [0|1] ""  ECC,GW
 SG_ VCU_UsrData1_Bit6_DIAGN_AWAKE : 30|1@0+ (1,0) [0|1] ""  ECC,GW
 SG_ VCU_UsrData1_Bit7_ECUSPEC_AWAKE : 31|1@0+ (1,0) [0|1] ""  ECC,GW
 SG_ VCU_UsrData2 : 39|8@0+ (1,0) [0|255] ""  ECC,GW
 SG_ VCU_UsrData3 : 47|8@0+ (1,0) [0|255] ""  ECC,GW
 SG_ VCU_UsrData4_PN_Info1 : 55|8@0+ (1,0) [0|255] ""  ECC,GW
 SG_ VCU_UsrData5_PN_Info2 : 63|8@0+ (1,0) [0|255] ""  ECC,GW

BO_ 1043 ECC_NM_0x413: 8 ECC
 SG_ ECC_SrcNodeID : 7|8@0+ (1,0) [0|127] ""  GW,VCU
 SG_ ECC_CtrlBitVector_Bit0_RMR : 8|1@0+ (1,0) [0|1] ""  GW,VCU
 SG_ ECC_CtrlBitVector_Bit1_Res : 9|1@0+ (1,0) [0|1] ""  GW,VCU
 SG_ ECC_CtrlBitVector_Bit2_Res : 10|1@0+ (1,0) [0|1] ""  GW,VCU
 SG_ ECC_CtrlBitVector_Bit3_NMCoord : 11|1@0+ (1,0) [0|1] ""  GW,VCU
 SG_ ECC_CtrlBitVector_Bit4_ActWake : 12|1@0+ (1,0) [0|1] ""  GW,VCU
 SG_ ECC_CtrlBitVector_Bit5_Res : 13|1@0+ (1,0) [0|1] ""  GW,VCU
 SG_ ECC_CtrlBitVector_Bit6_PNI : 14|1@0+ (1,0) [0|1] ""  GW,VCU
 SG_ ECC_CtrlBitVector_Bit7_Res : 15|1@0+ (1,0) [0|1] ""  GW,VCU
 SG_ ECC_UsrData0 : 23|8@0+ (1,0) [0|255] ""  GW,VCU
 SG_ ECC_UsrData1_Bit0_IGN_WAKEUP : 24|1@0+ (1,0) [0|1] ""  GW,VCU
 SG_ ECC_UsrData1_Bit1_RESET_WAKEUP : 25|1@0+ (1,0) [0|1] ""  GW,VCU
 SG_ ECC_UsrData1_Bit2_NETWORK_WAKEUP : 26|1@0+ (1,0) [0|1] ""  GW,VCU
 SG_ ECC_UsrData1_Bit3_ECUSPEC_WAKEUP : 27|1@0+ (1,0) [0|1] ""  GW,VCU
 SG_ ECC_UsrData1_Bit4_NETWORK_AWAKE : 28|1@0+ (1,0) [0|1] ""  GW,VCU
 SG_ ECC_UsrData1_Bit5_IGNITION_AWAKE : 29|1@0+ (1,0) [0|1] ""  GW,VCU
 SG_ ECC_UsrData1_Bit6_DIAGN_AWAKE : 30|1@0+ (1,0) [0|1] ""  GW,VCU
 SG_ ECC_UsrData1_Bit7_ECUSPEC_AWAKE : 31|1@0+ (1,0) [0|1] ""  GW,VCU
 SG_ ECC_UsrData2 : 39|8@0+ (1,0) [0|255] ""  GW,VCU
 SG_ ECC_UsrData3 : 47|8@0+ (1,0) [0|255] ""  GW,VCU
 SG_ ECC_UsrData4_PN_Info1 : 55|8@0+ (1,0) [0|255] ""  GW,VCU
 SG_ ECC_UsrData5_PN_Info2 : 63|8@0+ (1,0) [0|255] ""  GW,VCU

CM_ SG_ 870 MCU_R_SecuStsChkFlt "Rear MCU security state detection fault_P18B741_E00MCURSecuritystateckeckfault.";
CM_ SG_ 870 MCU_R_HVActvDchaFlt "Rear MCU active discharge fault_P18B704_E00MCURActiveDischargeFault.";
CM_ SG_ 870 MCU_R_CtrlPanTChkCircFlt "Rear MCU control board temperature detection loop faulty_P18B91C_E00";
CM_ SG_ 870 MCU_R_ComLostFlt_VCU "Rear MCU and VCU communication loss faet_U110E87_E00";
CM_ SG_ 870 MCU_R_E2EFlt "Rear MCU E2E failed_U111087_E00";
CM_ SG_ 870 MCU_R_I2TFlt "Rear MCU AC/DC connector I2T failed_P18BA01_E00";
CM_ SG_ 870 MCU_R_OperModFlt "Abnormal operation mode of rear motor_P18BA62_E00";
CM_ SG_ 870 MCU_R_CooltOverTFlt "Rear motor MCU coolant over-temperature fault_P18BB98_E00";
CM_ SG_ 870 MCU_R_PhaCrtSampleCircFltU "Rear MCU phase current sampling loop fault (U phase)_P18B012_E03";
CM_ SG_ 870 MCU_R_PhaCrtSampleCircFltV "Rear MCU phase current sampling loop fault (V phase)_P18B112_E03";
CM_ SG_ 870 MCU_R_PhaCrtSampleCircFltW "Rear MCU phase current sampling loop fault (W phase)_P18B212_E03";
CM_ SG_ 870 MCU_R_ThreePhaCrtChkFlt "Three-phase current verification fault of rear drive motor_P18B464_E03";
CM_ SG_ 870 MCU_R_DCBusUnderVoltFlt "Undervoltage fault of DC bus of rear MCU_P18B616_E03";
CM_ SG_ 870 MCU_R_DCBusOverVoltFlt "Overvoltage of DC bus of rear MCU_P18B217_E03";
CM_ SG_ 870 MCU_R_PosnSnsrChkCircFlt "Rear MCU position signal detection loop faulty_P18B400_E03";
CM_ SG_ 870 MCU_R_DCBusVoltSampleCircFlt "Rear MCU DC bus voltage sampling loop faulty_P18B61C_E03";
CM_ SG_ 870 MCU_R_OverSpdFlt "Rear drive motor over-speed faet_P18B200_E03";
CM_ SG_ 870 MCU_R_IGBTOverTFltU "Rear MCU IGBT over-temperature fault (U-phase)_P18B098_E00";
CM_ SG_ 870 MCU_R_IGBTTChkCircFltU "Rear MCU IGBT temperature detection loop fault (U phase)_P18B01C_E00";
CM_ SG_ 870 MCU_R_IGBTTChkCircFltV "Rear MCU IGBT temperature detection loop fault (phase V)_P18B11C_E00";
CM_ SG_ 870 MCU_R_IGBTTChkCircFltW "Rear MCU IGBT temperature detection loop fault (W phase)_P18B21C_E00";
CM_ SG_ 870 MCU_R_OverTFlt "Rear drive motor over-temperature fault_P18B498_E00";
CM_ SG_ 870 MCU_R_TChkCircFlt "Rear drive motor temperature detection loop faulty_P18B51C_E00";
CM_ SG_ 870 MCU_R_CtrlPanOverTFlt "Rear MCU control board over-temperature fault_P18B398_E00";
CM_ SG_ 870 MCU_R_LVPwrSplyUnderVoltFlt "Rear MCU low voltage power undervoltage faet_P18B716_E03";
CM_ SG_ 870 MCU_R_LVPwrSplyOverVoltFlt "Overvoltage failure of low voltage power supply of rear MCU_P18B617_E03";
CM_ SG_ 870 MCU_R_FbTqStsChkFlt "Rear MCU feedback torque and torque command check error fault_P18B664_E03";
CM_ SG_ 870 MCU_R_PhaCrtSwOverCrtFltU "Rear MCU phase current hardware overcurrent fault (U phase)_P18B316_E03";
CM_ SG_ 870 MCU_R_TqCmdOverLimFlt "Rear MCU torque command overrun fa_U18B686_E03";
CM_ SG_ 870 MCU_R_PwrSplyModFlt "Rear MCU power supply module faulty_P18B71C_E03";
CM_ SG_ 870 MCU_R_IGBTThreePhaTChkFlt "Rear MCU IGBT three-phase temperature check fault_P18B841_E00";
CM_ SG_ 870 MCU_R_RotCalFlt "Rear drive motor rotation variable calibration fault_P18B804_E00";
CM_ SG_ 870 MCU_R_IntComFlt "Internal communication fault of rear MCU_U110F87_E00";
CM_ SG_ 870 MCU_R_IntTqChkFlt "Rear MCU internal torque verification fault_P18BB96_E00";
CM_ SG_ 870 MCU_R_IGBTDesatFltTop "Rear MCU IGBT drive circuit fault (U-phase down bridge)_P18B116_E00MCURIGBTvoltagefault(U BOTTOM).";
CM_ SG_ 870 MCU_R_IGBTDesatFltBot "Rear MCU IGBT drive circuit fault (V phase lower bridge)_P18B816MCURIGBTvoltagelow(V BOTTOM).";
CM_ SG_ 870 MCU_R_PhaCrtSwOverCrtFltV "Rear MCU phase current hardware overcurrent fault (V phase)_P18B416_E00";
CM_ SG_ 870 MCU_R_PhaCrtSwOverCrtFltW "Rear MCU phase current hardware overcurrent fault (W phase)_P18B516_E00";
CM_ SG_ 870 MCU_R_IGBTOverTFltV "Rear MCU IGBT over-temperature fault (phase V)_P18B198_E00";
CM_ SG_ 870 MCU_R_IGBTOverTFltW "Rear MCU IGBT over-temperature fault (W phase)_P18B298_E00";
CM_ SG_ 880 BMS_PwrBattOverChrgAlrm "Traction battery overcharge alarming";
CM_ SG_ 880 BMS_PwrBattUderVoltFlt "Power battery undervoltage fault";
CM_ SG_ 880 BMS_CellUnderVoltFailFlt "Single undervoltage fault (failure)";
CM_ SG_ 880 BMS_CellUnderVoltFlt "Single undervoltage fault";
CM_ SG_ 880 BMS_BattBalActv "Battery equalization activation";
CM_ SG_ 880 BMS_BattPack1OverVoltFlt "Overvoltage fault of battery pack 1";
CM_ SG_ 880 BMS_BattPack1UnderVoltFlt "Undervoltage fault of battery pack 1";
CM_ SG_ 880 BMS_DCChrgSoktOverTFlt "Overtemperature fault of DC charging socket";
CM_ SG_ 880 BMS_ComLostFlt_BOBC "Fail loss of BMS and BOBC communication";
CM_ SG_ 880 BMS_ComLostFlt_CCU "Lost communication between BMS and CCU";
CM_ SG_ 880 BMS_ACChrgSoktOverTFlt "AC charging socket over temperature faet";
CM_ SG_ 880 BMS_ACCrtFlt "Abnormal charging current";
CM_ SG_ 880 BMS_InsulChkFltLvl2ProtFlg "Insulation detection circuit fault secondary protection flag bit";
CM_ SG_ 880 BMS_PwrBattOverTAlrm "Overtemperature warning of traction battery";
CM_ SG_ 880 BMS_PwrBattHLVIntlkFlt "High and low voltage interlock failure of traction battery";
CM_ SG_ 880 BMS_PwrBattExtShoCirc "External short circuit of traction battery";
CM_ SG_ 880 BMS_PwrBattIntShoCirc "Internal short circuit of traction battery";
CM_ SG_ 880 BMS_PwrBattTUnbal "Traction battery temperature imbalance";
CM_ SG_ 880 BMS_PwrBattTRiseFast "Temperature rise of traction battery too fast";
CM_ SG_ 880 BMS_PwrBattIntTotVoltChkFlt "Traction battery internal total voltage detection fault (V1)";
CM_ SG_ 880 BMS_PwrBattExtTotVoltChkFlt "Traction battery external total voltage detection fault (V2)";
CM_ SG_ 880 BMS_PwrBattNegRlyAdh "Traction battery negative terminal relay blocking";
CM_ SG_ 880 BMS_PwrBattPrecRlyAdh "Traction battery pre-charging relay blocking";
CM_ SG_ 880 BMS_PwrBattPosRlyAdh "Traction battery positive terminal relay blocking";
CM_ SG_ 880 BMS_PwrBattNegRlyBreak "Open circuit of relay at negative terminal of traction battery";
CM_ SG_ 880 BMS_PwrBattPrecRlyBreak "Traction battery precharging relay open circuit";
CM_ SG_ 880 BMS_PwrBattPosRlyBreak "Open circuit of positive terminal relay of traction battery";
CM_ SG_ 880 BMS_PwrBattPrecRBreak "Traction battery precharge blocked road";
CM_ SG_ 880 BMS_PwrBattMSDBreak "Traction battery MSD/main fuse open circuit";
CM_ SG_ 880 BMS_PwrBattExtTotVoltChkFltV2 "Traction battery external total voltage detection circuit fault (V2)";
CM_ SG_ 880 BMS_BCUEEPROMReadWrFlt "BCU-EEPROM read-write failure";
CM_ SG_ 880 BMS_PwrBattPosRlyDrvChFlt "Traction battery positive terminal relay drive channel fa";
CM_ SG_ 880 BMS_PwrBattPrecRlyDrvChFlt "Traction battery pre-charge relay drive channel fa";
CM_ SG_ 880 BMS_PwrBattInsulChkFlt "Traction battery insulation detection circuit fault";
CM_ SG_ 880 BMS_PwrBattNegRlyDrvChFlt "Fault of drive channel of relay at negative terminal of traction battery";
CM_ SG_ 880 BMS_PwrBattCellVoltUnbal "Unbalanced voltage of traction battery cells";
CM_ SG_ 880 BMS_EEPROMReadWrFlt "BMS-EEPROM RE";
CM_ SG_ 880 BMS_PwrBattSysIntComFlt "Internal communication fault in power battery system";
CM_ SG_ 880 BMS_InsulRLo "Low insulation resistance";
CM_ SG_ 880 BMS_CopRowLooseFlt "Copper straining";
CM_ SG_ 880 BMS_SubEEPROMReadWrFlt "Subboard EEPROM read/write malfunction";
CM_ SG_ 880 BMS_SubCellVoltCollctnCircFlt "Subboard single voltage acquisition circuit faulty";
CM_ SG_ 880 BMS_SubModleVoltCollctnCircFlt "Voltage acquisition circuit failure of sub-board module";
CM_ SG_ 880 BMS_SubTCollctnCircFlt "Daughter board temperature acquisition circuit faulty";
CM_ SG_ 880 BMS_SubActvBalChFlt "Subboard Active Balance Channel Malfunction";
CM_ SG_ 880 BMS_SubPasBalChFlt "Subboard passive equalization channel faulty";
CM_ SG_ 880 BMS_SubOperModRespFlt "Subboard operating mode response abnormal";
CM_ SG_ 880 BMS_BattCellVoltUnbalAlrm "Warning of unbalanced voltage of battery cell";
CM_ SG_ 880 BMS_ComLostFlt_ECC "Lost communication between BMS and ECC";
CM_ SG_ 880 BMS_SubComLostFlt_VBUBMS "Missing communication failure between sub-board and VBU/BMS";
CM_ SG_ 880 BMS_PrecFailFlt "Precharge Failure";
CM_ SG_ 880 BMS_PwrBattCellOverVolt "Overvoltage of traction battery cell";
CM_ SG_ 880 BMS_TotVoltOver "Total Overvoltage";
CM_ SG_ 880 BMS_PwrBattIntTotVoltChkFltV1 "Traction battery internal total voltage detection circuit fault (V1)";
CM_ SG_ 880 BMS_TotCrtChkFlt "Total current detection circuit";
CM_ SG_ 880 BMS_ComLostFlt_VCU "Lost communication between BMS and VCU faet";
CM_ SG_ 880 BMS_BattReDrvHLVIntlkFlt "High and low voltage interlock of rear drive of battery pack faect";
CM_ SG_ 880 BMS_ComOverTiFlt_ECC "Communication timeout fault between BMS and ECC";
CM_ SG_ 880 BMS_LVPwrSplyFlt "BMS low voltage power supply abnormal failure";
CM_ SG_ 880 BMS_ComOverTiFlt_BOBC "Communication timeout fault between BMS and BOBC";
CM_ SG_ 881 WTC_B_PCBT "WTC_BPCB Temperature";
CM_ SG_ 881 WTC_B_Crt "WTC_B Current operating current";
CM_ SG_ 881 WTC_B_CrtSts "WTC_B current operating state";
CM_ SG_ 881 WTC_B_HVIntlkFlt "WTC_B high voltage interlock fault";
CM_ SG_ 881 WTC_B_ComLost_ECC "WTC_B and ECC communication loss fault";
CM_ SG_ 881 WTC_B_OverCrtFlt "WTC_B Overcurrent fault";
CM_ SG_ 881 WTC_B_HVUnderVoltFlt "WTC_B high voltage undervoltage fault";
CM_ SG_ 881 WTC_B_HVOverVoltFlt "WTC_B high voltage overvoltage fault";
CM_ SG_ 881 WTC_B_ChkBattOverVoltFlt "WTC_B check battery high voltage fault";
CM_ SG_ 881 WTC_B_ChkBattUnderVoltFlt "WTC_B check battery low voltage fault";
CM_ SG_ 881 WTC_B_InlTSnsrFlt "WTC_B Inlet temperature sensor fault";
CM_ SG_ 881 WTC_B_OutlTSnsrFlt "WTC_B Outlet temperature sensor fault";
CM_ SG_ 881 WTC_B_InlOverTFlt "WTC_B Water inlet temperature overtemperature fault";
CM_ SG_ 881 WTC_B_OutlOverTFlt "WTC_B Outlet temperature overtemperature fault";
CM_ SG_ 881 WTC_B_PCBOverTFlt "WTC_B circuit board (PCB) over-temperature fault";
CM_ SG_ 881 WTC_B_PCBTSnsrFlt "WTC_B circuit board (PCB) temperature sensor fault";
CM_ SG_ 881 WTC_B_PwrOutpFlt "WTC_B power output fault";
CM_ SG_ 882 BMS_372_382_CheckSum "BMS_372_Message checksum (E2E data ID: 0x1C); ";
CM_ SG_ 882 BMS_372_382_AliveCounter "BMS_372 _Message counterBMS_372_AliveCounter";
CM_ SG_ 882 BMS_OTARdy_Fb "BMS OTA ready status feedback";
CM_ SG_ 882 BMS_CellMinT "Minimum temperature of single cell";
CM_ SG_ 882 BMS_CellDiffT "Single cell temperature range";
CM_ SG_ 882 BMS_CellMaxT "Maximum temperature of single cell";
CM_ SG_ 882 BMS_BattAvrgT "Average temperature of battery pack";
CM_ SG_ 882 BMS_PwrBattHeatgMngDmd "Power battery thermal management requirements";
CM_ SG_ 882 BMS_ECCSysAllwDwnPwrCmd "Allowable power reduction instruction of A/C system";
CM_ SG_ 882 BMS_BattInlTDmd "Water inlet temperature requirements of battery pack";
CM_ SG_ 882 BMS_372_SSecOC_Fresh_Byte0 "Short SecOC Fresh signal byte 0 on CAN";
CM_ SG_ 882 BMS_372_SSecOC_MAC_Byte0 "Short SecOC MAC signal byte 0 on CAN";
CM_ SG_ 882 BMS_372_SSecOC_MAC_Byte1 "Short SecOC MAC signal byte 1 on CAN";
CM_ SG_ 882 BMS_372_SSecOC_MAC_Byte2 "Short SecOC MAC signal byte 2 on CAN";
CM_ SG_ 883 ECC_CrtSts "ECC current state";
CM_ SG_ 883 ECC_IninSts "ECC initialization state";
CM_ SG_ 883 ECC_PwrSysHeatMngtSts "Power system thermal management state";
CM_ SG_ 883 ECC_ACSts "A/C state";
CM_ SG_ 883 ECC_AirClnSts "Air purification state";
CM_ SG_ 883 ECC_WindSpdSts "Wind speed state";
CM_ SG_ 883 ECC_BackRowAirOutlModSts "Rear exhaust mode state";
CM_ SG_ 883 ECC_DrvrTSetSts "Main driving temperature setting state";
CM_ SG_ 883 ECC_PassTSetSts "Temperature setting state of front passenger";
CM_ SG_ 883 ECC_HeatSts "HEAT state";
CM_ SG_ 883 ECC_AUTOSts "A/C AUTO state";
CM_ SG_ 883 ECC_SYNCSts "SYNC state";
CM_ SG_ 883 ECC_InfoSysWrmColdDisp "Display of heating and cooling degree of entertainment system";
CM_ SG_ 883 ECC_CircSts "Cycle state";
CM_ SG_ 883 ECC_ParticleConcVld "Effective position of particle concentration";
CM_ SG_ 883 ECC_OutdT "Ambient temperature outside the vehicle";
CM_ SG_ 883 ECC_OutdTVld "Effective position of ambient temperature outside vehicle";
CM_ SG_ 883 ECC_MaxFrntDefrst "Max Front defrosting";
CM_ SG_ 883 ECC_HeatMngtSysFlt "Fault of thermal management system";
CM_ SG_ 883 ECC_HeatMngtFctLim "Requirement for Thermal Management Function of Occupant Compartment";
CM_ SG_ 883 ECC_DrvrAirOutlMod "Driver Air Outlet Mode";
CM_ SG_ 883 ECC_PassAirOutlMod "Front passenger air-out mode";
CM_ SG_ 883 ECC_RemSts "Operating status of remote A/C";
CM_ SG_ 883 ECC_OTAInhbRdy "OTA pre-condition and Inhibiting of all OTA relevant ECUs";
CM_ SG_ 884 WTC_H_PCBT "WTC_HPCB Temperature";
CM_ SG_ 884 WTC_H_Crt "WTC_H Current operating current";
CM_ SG_ 884 WTC_H_CrtSts "WTC_H current operating state";
CM_ SG_ 884 WTC_H_HVIntlkFlt "WTC_H high-voltage interlock fault_P164B94_E00";
CM_ SG_ 884 WTC_H_ComLost_ECC "WTC_H and ECC_U198187_E00";
CM_ SG_ 884 WTC_H_OverCrtFlt "WTC_H Overcurrent fa_P164019_E00";
CM_ SG_ 884 WTC_H_HVUnderVoltFlt "WTC_H high voltage undervoltage fault_P165716_E00";
CM_ SG_ 884 WTC_H_HVOverVoltFlt "WTC_H High voltage overvoltage fault_P165717_E00";
CM_ SG_ 884 WTC_H_ChkBattOverVoltFlt "WTC_H Check Battery Overvoltage fa_U190017_E00";
CM_ SG_ 884 WTC_H_ChkBattUnderVoltFlt "WTC_H Check Battery Undervoltage_U190016_E00";
CM_ SG_ 884 WTC_H_InlTSnsrFlt "WTC_H Water inlet temperature sensor faulty_P16491C_E00";
CM_ SG_ 884 WTC_H_OutlTSnsrFlt "WTC_H Water outlet temperature sensor faulty_P164A1C_E00";
CM_ SG_ 884 WTC_H_InlOverTFlt "WTC_H Water inlet temperature overtemperature fault_P164998_E00";
CM_ SG_ 884 WTC_H_OutlOverTFlt "WTC_H Water outlet temperature overtemperature fault_P164A98_E00";
CM_ SG_ 884 WTC_H_PCBOverTFlt "WTC_H Board (PCB) over-temperature fault_P164898_E00";
CM_ SG_ 884 WTC_H_PCBTSnsrFlt "WTC_H circuit board (PCB) temperature sensor faulty_P16481C_E00";
CM_ SG_ 884 WTC_H_PwrOutpFlt "WTC_H power output fa_P164C00_E00";
CM_ SG_ 886 WTC_B_InlT "WTC_B inlet temperature";
CM_ SG_ 886 WTC_B_OutlT "WTC_B outlet temperature";
CM_ SG_ 886 WTC_B_CrtPwr "WTC_B current power";
CM_ SG_ 886 WTC_B_CrtT "WTC_B Current operating temperature";
CM_ SG_ 886 WTC_B_IninSts "WTC_B initialization state";
CM_ SG_ 886 WTC_B_HVPwrSplySts "WTC_B high voltage power supply state";
CM_ SG_ 886 WTC_B_ActGear "WTC_B Actual gear";
CM_ SG_ 886 WTC_B_Mod "WTC_B current operating mode";
CM_ SG_ 888 ECC_MCUFCooltFlow "Front drive motor coolant flow";
CM_ SG_ 888 ECC_MCURCooltFlow "Rear drive motor coolant flow";
CM_ SG_ 888 ECC_LeOutlUpDwnMotActvSts "Operating state of upper/lower motor of left air outlet";
CM_ SG_ 888 ECC_LeOutlLeRiMotActvSts "Operating state of left/right motor of left air outlet";
CM_ SG_ 888 ECC_LeOutlDamprMotActvSts "Operating state of left air vent damper motor";
CM_ SG_ 888 ECC_MidLeOutlUpDwnMotActvSts "Operating state of upper and lower motors at middle left air outlet";
CM_ SG_ 888 ECC_MidLeOutlLeRiMotActvSts "Operating state of left/right motor at middle left air outlet";
CM_ SG_ 888 ECC_MidLeOutlDamprMotActvSts "Operating state of middle left air outlet damper motor";
CM_ SG_ 888 ECC_MidRiOutlUpDwnMotActvSts "Operating state of upper and lower motors of middle right air outlet";
CM_ SG_ 888 ECC_MidRiOutlLeRiMotActvSts "Operating state of left/right motor at middle right air outlet";
CM_ SG_ 888 ECC_MidRiOutlDamprMotActvSts "Operating state of middle right air vent damper motor";
CM_ SG_ 888 ECC_RiOutlUpDwnMotActvSts "Operating state of upper and lower motors of right air outlet";
CM_ SG_ 888 ECC_RiOutlLeRiMotActvSts "Operating state of left/right motor of right air outlet";
CM_ SG_ 888 ECC_RiOutlDamprMotActvSts "Operating state of right air vent damper motor";
CM_ SG_ 889 WTC_H_InpT "WTC_H inlet temperature";
CM_ SG_ 889 WTC_H_OutpT "WTC_H outlet temperature";
CM_ SG_ 889 WTC_H_CrtPwr "WTC_H current power";
CM_ SG_ 889 WTC_H_CrtT "WTC_H Current operating temperature";
CM_ SG_ 889 WTC_H_IninSts "WTC_H initialization state";
CM_ SG_ 889 WTC_H_HVPwrSplySts "WTC_H high voltage power supply state";
CM_ SG_ 889 WTC_H_ActGear "WTC_H Actual gear";
CM_ SG_ 889 WTC_H_Mod "WTC_H current operating mode";
CM_ SG_ 890 ICC_LeOutlUpDwnMotActvCmd "Left air outlet upper and lower motor operating instruction";
CM_ SG_ 890 ICC_LeOutlLeRiMotActvCmd "Left/right motor operating command of left air vent";
CM_ SG_ 890 ICC_LeOutlDamprMotActvCmd "Left air vent damper motor operating instruction";
CM_ SG_ 890 ICC_MidLeOutlUpDwnMotActvCmd "Middle left air outlet upper and lower motor operating instruction";
CM_ SG_ 890 ICC_MidLeOutlLeRiMotActvCmd "Middle left air outlet left and right motor action command";
CM_ SG_ 890 ICC_MidLeOutlDamprMotActvCmd "Middle left air vent damper motor operating instruction";
CM_ SG_ 890 ICC_MidRiOutlUpDwnMotActvCmd "Operation command of upper and lower motors of middle right air outlet";
CM_ SG_ 890 ICC_MidRiOutlLeRiMotActvCmd "Middle right air outlet left and right motor action command";
CM_ SG_ 890 ICC_MidRiOutlDamprMotActvCmd "Middle right air vent damper motor operating command";
CM_ SG_ 890 ICC_RiOutlUpDwnMotActvCmd "Right air outlet upper and lower motor operating instructions";
CM_ SG_ 890 ICC_RiOutlLeRiMotActvCmd "Right air vent left and right motor action command";
CM_ SG_ 890 ICC_RiOutlDamprMotActvCmd "Right air vent damper motor operating instruction";
CM_ SG_ 891 PKC_SysAlrmVld "Effective value of system warning";
CM_ SG_ 891 PKC_RemLockCmd_Key "Remote locking command";
CM_ SG_ 891 PKC_KeyStsMod "Key state mode";
CM_ SG_ 891 PKC_KeyID "Authenticated with KeyID number xx";
CM_ SG_ 891 PKC_KeyInCarRmn "Reminder of key falling in vehicle";
CM_ SG_ 891 PKC_RemLockCmd "Remote locking command";
CM_ SG_ 891 PKC_BatterySts "Key low battery prompt";
CM_ SG_ 891 PKC_KeyOutdCarPromt "Key not in vehicle reminder";
CM_ SG_ 891 PKC_DoorOpenRmd "Signal indicates that a locking request has been received when any door (except tailgate) is open. ";
CM_ SG_ 891 PKC_StrtFailTyp "PEPS startup failure type";
CM_ SG_ 891 PKC_LockKeyInCarInd "Signal indicates that a locking request from outside the car was received while another key was left inside the car.";
CM_ SG_ 891 PKC_KeySts "Key state";
CM_ SG_ 891 PKC_37B_SSecOC_Fresh_Byte0 "Short SecOC Fresh signal byte 0 on CAN";
CM_ SG_ 891 PKC_37B_SSecOC_MAC_Byte0 "Short SecOC MAC signal byte 0 on CAN";
CM_ SG_ 891 PKC_37B_SSecOC_MAC_Byte1 "Short SecOC MAC signal byte 1 on CAN";
CM_ SG_ 891 PKC_37B_SSecOC_MAC_Byte2 "Short SecOC MAC signal byte 2 on CAN";
CM_ SG_ 897 RAC_OnOff "On Off button";
CM_ SG_ 897 RAC_BackRowAirOutlModReq "Rear exhaust mode request";
CM_ SG_ 897 RAC_VolInc "Volume up";
CM_ SG_ 897 RAC_VolDec "Volume reduction";
CM_ SG_ 897 RAC_VolCtrl "Silence control";
CM_ SG_ 897 RAC_TempCtrlnc "Temperature Control increase";
CM_ SG_ 897 RAC_TempCtrDec "Temperature Control decrease";
CM_ SG_ 897 RAC_BlowCtrInc "Blower control increase";
CM_ SG_ 897 RAC_BlowCtrDec "Blower control decrease";
CM_ SG_ 897 RAC_AirOutlLeftBtn "Air Outlet control left button";
CM_ SG_ 897 RAC_AirOutlRightBtn "Air Outlet control right button";
CM_ SG_ 897 RAC_SeatHRearLeftBtn "Seat Heating Button Rear left";
CM_ SG_ 897 RAC_SeatHRearRightBtn "Seat Heating Button Rear right";
CM_ SG_ 901 TBOX_PreHeatDepartTi1_Hr "Time for preheating_Hour";
CM_ SG_ 901 TBOX_PreHeatDepartTi1_Mins "Time for preheating_Minutes";
CM_ SG_ 901 TBOX_PreHeatDepartSet "Preheating depart set";
CM_ SG_ 901 TBOX_MonPreHeatDepartSet "Preheating depart set_Monday";
CM_ SG_ 901 TBOX_TuePreHeatDepartSet "Preheating depart set_Tuesday";
CM_ SG_ 901 TBOX_WedPreHeatDepartSet "Preheating depart set_Wednesday";
CM_ SG_ 901 TBOX_ThuPreHeatDepartSet "Preheating depart set_Thursday";
CM_ SG_ 901 TBOX_FriPreHeatDepartSet "Preheating depart set_Friday";
CM_ SG_ 901 TBOX_SatPreHeatDepartSet "Preheating depart set_Saturday";
CM_ SG_ 901 TBOX_SunPreHeatDepartSet "Preheating depart set_Sunday";
CM_ SG_ 901 TBOX_PreCdnTarT "the pre-conditioning time of a specific tagret temperature";
CM_ SG_ 901 TBOX_PreHeatDepartSetFb "feedback signal for PreHeating time schedule";
CM_ SG_ 901 TBOX_PreHeatDepartTi2_Hr "Time for preheating_Hour";
CM_ SG_ 901 TBOX_PreHeatDepartTi2_Mins "Time for preheating_Minutes";
CM_ SG_ 928 BMS_Cont_Error_StuckOpen_HV_Pos1 "Relay is Open (F)";
CM_ SG_ 928 BMS_Cont_Error_Welded_HV_Pos1 "Relay is Welded (F)";
CM_ SG_ 928 BMS_Cont_Error_Exceed_HV_Pos1 "One of the relay counters is exceeded (F)";
CM_ SG_ 928 BMS_Cont_Error_DisCh1_HV_Pos1 "Number of times contactor opened under high current load";
CM_ SG_ 928 BMS_Cont_Error_DisCh2_HV_Pos1 "Number of times contactor opened under really high current load";
CM_ SG_ 928 BMS_Cont_Error_DisCh3_HV_Pos1 "Number of times contactor opened under really high current load";
CM_ SG_ 928 BMS_Cont_Error_DisCh4_HV_Pos1 "Number of times contactor opened under really high current load";
CM_ SG_ 928 BMS_Cont_Error_Ch1_HV_Pos1 "Number of times contactor opened under really high current load";
CM_ SG_ 928 BMS_Cont_Error_Ch2_HV_Pos1 "Number of times contactor opened under really high current load";
CM_ SG_ 929 BMS_Cont_Error_StuckOpen_HV_Neg1 "Relay is Open (F)";
CM_ SG_ 929 BMS_Cont_Error_Welded_HV_Neg1 "Relay is Welded (F)";
CM_ SG_ 929 BMS_Cont_Error_Exceed_HV_Neg1 "One of the relay counters is exceeded (F)";
CM_ SG_ 929 BMS_Cont_Error_DisCh1_HV_Neg1 "Number of times contactor opened under high current load";
CM_ SG_ 929 BMS_Cont_Error_DisCh2_HV_Neg1 "Number of times contactor opened under really high current load";
CM_ SG_ 929 BMS_Cont_Error_DisCh3_HV_Neg1 "Number of times contactor opened under really high current load";
CM_ SG_ 929 BMS_Cont_Error_DisCh4_HV_Neg1 "Number of times contactor opened under really high current load";
CM_ SG_ 929 BMS_Cont_Error_Ch1_HV_Neg1 "Number of times contactor opened under really high current load";
CM_ SG_ 929 BMS_Cont_Error_Ch2_HV_Neg1 "Number of times contactor opened under really high current load";
CM_ SG_ 930 BMS_Cont_Error_StuckOpen_HV_Prec "Relay is Open (F)";
CM_ SG_ 930 BMS_Cont_Error_Welded_HV_Prec1 "Relay is Welded (F)";
CM_ SG_ 930 BMS_Cont_Error_Exceed_HV_Prec "One of the relay counters is exceeded (F)";
CM_ SG_ 930 BMS_Cont_Error_DisCh1_HV_Prec "Number of times contactor opened under high current load";
CM_ SG_ 930 BMS_Cont_Error_DisCh2_HV_Prec "Number of times contactor opened under really high current load";
CM_ SG_ 930 BMS_Cont_Error_DisCh3_HV_Prec "Number of times contactor opened under really high current load";
CM_ SG_ 930 BMS_Cont_Error_DisCh4_HV_Prec "Number of times contactor opened under really high current load";
CM_ SG_ 930 BMS_Cont_Error_Ch1_HV_Prec1 "Number of times contactor opened under really high current load";
CM_ SG_ 930 BMS_Cont_Error_Ch2_HV_Prec1 "Number of times contactor opened under really high current load";
CM_ SG_ 933 BMS_Bat_Coolant_in "Actual coolant REESS inlet temperature [Deg Cel]";
CM_ SG_ 933 BMS_Bat_Coolant_out "Actual coolant REESS outlet temperature [Deg Cel]";
CM_ SG_ 933 BMS_BattInlT_Target "Target Coolant inlet Temperature of battery";
CM_ SG_ 933 BMS_BattInlT_Min "Target Coolant inlet Minimum Temperature of battery";
CM_ SG_ 933 BMS_BattInlT_Max "Target Coolant inlet Maximum Temperature of battery";
CM_ SG_ 934 BMS_Cont_Error_StuckOpen_HV_PV_N "Relay is Open (F)";
CM_ SG_ 934 BMS_Cont_Error_Welded_HV_PV_Neg1 "Relay is Welded (F)";
CM_ SG_ 934 BMS_Cont_Error_Exceed_HV_PV_Neg1 "One of the relay counters is exceeded (F)";
CM_ SG_ 934 BMS_Cont_Error_DisCh1_HV_PV_Neg1 "Number of times contactor opened under high current load";
CM_ SG_ 934 BMS_Cont_Error_DisCh2_HV_PV_Neg1 "Number of times contactor opened under really high current load";
CM_ SG_ 934 BMS_Cont_Error_DisCh3_HV_PV_Neg1 "Number of times contactor opened under really high current load";
CM_ SG_ 934 BMS_Cont_Error_DisCh4_HV_PV_Neg1 "Number of times contactor opened under really high current load";
CM_ SG_ 934 BMS_Cont_Error_Ch1_HV_PV_Neg1 "Number of times contactor opened under really high current load";
CM_ SG_ 934 BMS_Cont_Error_Ch2_HV_PV_Neg1 "Number of times contactor opened under really high current load";
CM_ SG_ 935 BMS_Cont_Error_StuckOpen_HV_PV_P "Relay is Open (F)";
CM_ SG_ 935 BMS_Cont_Error_Welded_HV_PV_Pos1 "Relay is Welded (F)";
CM_ SG_ 935 BMS_Cont_Error_Exceed_HV_PV_Pos1 "One of the relay counters is exceeded (F)";
CM_ SG_ 935 BMS_Cont_Error_DisCh1_HV_PV_Pos1 "Number of times contactor opened under high current load";
CM_ SG_ 935 BMS_Cont_Error_DisCh2_HV_PV_Pos1 "Number of times contactor opened under really high current load";
CM_ SG_ 935 BMS_Cont_Error_DisCh3_HV_PV_Pos1 "Number of times contactor opened under really high current load";
CM_ SG_ 935 BMS_Cont_Error_DisCh4_HV_PV_Pos1 "Number of times contactor opened under really high current load";
CM_ SG_ 935 BMS_Cont_Error_Ch1_HV_PV_Pos1 "Number of times contactor opened under really high current load";
CM_ SG_ 935 BMS_Cont_Error_Ch2_HV_PV_Pos1 "Number of times contactor opened under really high current load";
CM_ SG_ 944 GW_0x3B0_Checksum "GW_0x3B0 Message checksum (E2E data ID: 0x40)";
CM_ SG_ 944 GW_0x3B0_AliveCounter "GW_0x3B0 AliveCounter";
CM_ SG_ 944 GW_OTARdy_Fb "GW OTA ready status feedback";
CM_ SG_ 944 GW_OTAInhbRdy "GW OTA inhibit ready status";
CM_ SG_ 944 GW_UDSprohb "GW prohibits UDS messages";
CM_ SG_ 965 AMP_OTAInhbRdy "TA pre-condition and Inhibiting of all OTA relevant ECUs";
CM_ SG_ 992 VCU_reqFullEDUCooltFlow "Full EDU/MCU coolant flow request signal";
CM_ SG_ 992 VCU_HVEMBoostModSt "HV EM Boost Mode Status";
CM_ SG_ 992 VCU_MaxBoostCntr "Max Boost counter";
CM_ SG_ 992 VCU_BoostEnStatCoded "Boost Enable Status Coded";
CM_ SG_ 1025 VCU_SrcNodeID "Network Management Signal";
CM_ SG_ 1025 VCU_CtrlBitVector_Bit0_RMR "Network Management Signal: Repeat Message Request";
CM_ SG_ 1025 VCU_CtrlBitVector_Bit1_Res "Network Management Signal: Reserved (Legacy NM Coordinator ID) LowByte";
CM_ SG_ 1025 VCU_CtrlBitVector_Bit2_Res "Network Management Signal: Reserved (Legacy NM Coordinator ID) HighByte";
CM_ SG_ 1025 VCU_CtrlBitVector_Bit3_NMCoord "Network Management Signal: NM Coordinator Sleep Bit";
CM_ SG_ 1025 VCU_CtrlBitVector_Bit4_ActWake "Network Management Signal: Active Wakeup Bit";
CM_ SG_ 1025 VCU_CtrlBitVector_Bit5_Res "Network Management Signal: Reserved";
CM_ SG_ 1025 VCU_CtrlBitVector_Bit6_PNI "Network Management Signal: Partial Network Information Bit (PNI)";
CM_ SG_ 1025 VCU_CtrlBitVector_Bit7_Res "Network Management Signal: Reserved";
CM_ SG_ 1025 VCU_UsrData0 "The first user data byte determines the functionality of user data.This value is used as a constant that determines how the remaining three user data bytes are interpret the content of the remaining three user data bytes.";
CM_ SG_ 1025 VCU_UsrData1_Bit0_IGN_WAKEUP "Network Management Signal: ECU was power off or Bus sleep mode and started by Ignition turn on";
CM_ SG_ 1025 VCU_UsrData1_Bit1_RESET_WAKEUP "Network Management Signal: If ECU was already awake, in Prepare Bus Sleep or Ready Sleep mode and re-started by an internal or an external reset.";
CM_ SG_ 1025 VCU_UsrData1_Bit2_NETWORK_WAKEUP "Network Management Signal: ECU was in Power off, Bus Sleep, Prepare Bus Sleep or Ready Sleep Mode and then re-started by a network communication.";
CM_ SG_ 1025 VCU_UsrData1_Bit3_ECUSPEC_WAKEUP "Network Management Signal: ECU was in power off, Bus Sleep, Prepare Bus Sleep or Ready Sleep mode or awake and re- started by ECU-specific reason (e.g. pressed Button, timer, etc.)";
CM_ SG_ 1025 VCU_UsrData1_Bit4_NETWORK_AWAKE "Network Management Signal: ECU need network communication and keeps the network awake";
CM_ SG_ 1025 VCU_UsrData1_Bit5_IGNITION_AWAKE "Network Management Signal: ECU can’t release communication because Ignition is turn on";
CM_ SG_ 1025 VCU_UsrData1_Bit6_DIAGN_AWAKE "Network Management Signal: ECU need communication for diagnostic purpose and keeps network awake.";
CM_ SG_ 1025 VCU_UsrData1_Bit7_ECUSPEC_AWAKE "Network Management Signal: ECU keeps the network awake for ECU-define reasons for which communication is needed";
CM_ SG_ 1025 VCU_UsrData2 "Network Management Signal";
CM_ SG_ 1025 VCU_UsrData3 "Network Management Signal";
CM_ SG_ 1025 VCU_UsrData4_PN_Info1 "Network Management Signal";
CM_ SG_ 1025 VCU_UsrData5_PN_Info2 "Network Management Signal";
CM_ SG_ 1043 ECC_SrcNodeID "Network Management Signal";
CM_ SG_ 1043 ECC_CtrlBitVector_Bit0_RMR "Network Management Signal: Repeat Message Request";
CM_ SG_ 1043 ECC_CtrlBitVector_Bit1_Res "Network Management Signal: Reserved (Legacy NM Coordinator ID) LowByte";
CM_ SG_ 1043 ECC_CtrlBitVector_Bit2_Res "Network Management Signal: Reserved (Legacy NM Coordinator ID) HighByte";
CM_ SG_ 1043 ECC_CtrlBitVector_Bit3_NMCoord "Network Management Signal: NM Coordinator Sleep Bit";
CM_ SG_ 1043 ECC_CtrlBitVector_Bit4_ActWake "Network Management Signal: Active Wakeup Bit";
CM_ SG_ 1043 ECC_CtrlBitVector_Bit5_Res "Network Management Signal: Reserved";
CM_ SG_ 1043 ECC_CtrlBitVector_Bit6_PNI "Network Management Signal: Partial Network Information Bit (PNI)";
CM_ SG_ 1043 ECC_CtrlBitVector_Bit7_Res "Network Management Signal: Reserved";
CM_ SG_ 1043 ECC_UsrData0 "The first user data byte determines the functionality of user data.This value is used as a constant that determines how the remaining three user data bytes are interpret the content of the remaining three user data bytes.";
CM_ SG_ 1043 ECC_UsrData1_Bit0_IGN_WAKEUP "Network Management Signal: ECU was power off or Bus sleep mode and started by Ignition turn on";
CM_ SG_ 1043 ECC_UsrData1_Bit1_RESET_WAKEUP "Network Management Signal: If ECU was already awake, in Prepare Bus Sleep or Ready Sleep mode and re-started by an internal or an external reset.";
CM_ SG_ 1043 ECC_UsrData1_Bit2_NETWORK_WAKEUP "Network Management Signal: ECU was in Power off, Bus Sleep, Prepare Bus Sleep or Ready Sleep Mode and then re-started by a network communication.";
CM_ SG_ 1043 ECC_UsrData1_Bit3_ECUSPEC_WAKEUP "Network Management Signal: ECU was in power off, Bus Sleep, Prepare Bus Sleep or Ready Sleep mode or awake and re- started by ECU-specific reason (e.g. pressed Button, timer, etc.)";
CM_ SG_ 1043 ECC_UsrData1_Bit4_NETWORK_AWAKE "Network Management Signal: ECU need network communication and keeps the network awake";
CM_ SG_ 1043 ECC_UsrData1_Bit5_IGNITION_AWAKE "Network Management Signal: ECU can?t release communication because Ignition is turn on";
CM_ SG_ 1043 ECC_UsrData1_Bit6_DIAGN_AWAKE "Network Management Signal: ECU need communication for diagnostic purpose and keeps network awake.";
CM_ SG_ 1043 ECC_UsrData1_Bit7_ECUSPEC_AWAKE "Network Management Signal: ECU keeps the network awake for ECU-define reasons for which communication is needed";
CM_ SG_ 1043 ECC_UsrData2 "Network Management Signal";
CM_ SG_ 1043 ECC_UsrData3 "Network Management Signal";
CM_ SG_ 1043 ECC_UsrData4_PN_Info1 "Network Management Signal";
CM_ SG_ 1043 ECC_UsrData5_PN_Info2 "Network Management Signal";
BA_DEF_ BO_  "NmAsrMessage" ENUM  "No","Yes";
BA_DEF_ SG_  "GenSigCycleTime" INT 0 0;
BA_DEF_ BO_  "NmMessage" ENUM  "No","Yes";
BA_DEF_ BO_  "SC_Message" ENUM  "No","Yes","Yes, split message";
BA_DEF_ BO_  "DiagState" ENUM  "No","Yes";
BA_DEF_ BO_  "SC_LinkPos" INT 0 65535;
BA_DEF_ BO_  "DiagRequest" ENUM  "No","Yes";
BA_DEF_ BO_  "DiagFdOnly" ENUM  "No","Yes";
BA_DEF_ BO_  "DiagResponse" ENUM  "No","Yes";
BA_DEF_ BO_  "SCP_AuthInfoTxLength" INT 0 512;
BA_DEF_ BO_  "GenMsgSendType" ENUM  "Cyclic","NotUsed","NotUsed","NotUsed","NotUsed","NotUsed","NotUsed","IfActive","NoMsgSendType";
BA_DEF_ BO_  "SCP_DataId" INT 0 65535;
BA_DEF_ BO_  "GenMsgCycleTime" INT 0 0;
BA_DEF_ BO_  "SCP_FreshnessValueId" INT 0 65535;
BA_DEF_ BO_  "SCP_FreshnessValueLength" INT 0 512;
BA_DEF_ SG_  "GenSigStartValue" INT 0 0;
BA_DEF_ BO_  "SCL_CryptographicMessageID" INT 0 65535;
BA_DEF_ SG_  "GenSigInactiveValue" INT 0 0;
BA_DEF_ SG_  "GenSigSendType" ENUM  "Cyclic","OnWrite","OnWriteWithRepetition","OnChange","OnChangeWithRepetition","IfActive","IfActiveWithRepetition","NoSigSendType";
BA_DEF_ BO_  "SCP_FreshnessValueTxLength" INT 0 512;
BA_DEF_ BO_  "GenMsgCycleTimeFast" INT 0 0;
BA_DEF_ BO_  "GenMsgNrOfRepetition" INT 0 0;
BA_DEF_ BO_  "DiagConnection" INT 0 65535;
BA_DEF_ BO_  "GenMsgDelayTime" INT 0 0;
BA_DEF_ BO_  "CANFD_BRS" ENUM  "0","1";
BA_DEF_ BO_  "VFrameFormat" ENUM  "StandardCAN","ExtendedCAN","reserved","reserved","reserved","reserved","reserved","reserved","reserved","reserved","reserved","reserved","reserved","reserved","StandardCAN_FD","ExtendedCAN_FD";
BA_DEF_ BO_  "GenMsgILSupport" ENUM  "No","Yes";
BA_DEF_ BO_  "GenMsgStartDelayTime" INT 0 65535;
BA_DEF_ BO_  "E2EP01DataLength" INT 0 65535;
BA_DEF_ BO_  "E2EP01DataId" INT 0 65535;
BA_DEF_ SG_  "sigSecLevel" STRING ;
BA_DEF_ SG_  "sigConfig" STRING ;
BA_DEF_ SG_  "sigExplanation" STRING ;
BA_DEF_ SG_  "SystemSignalLongSymbol" STRING ;
BA_DEF_REL_ BU_SG_REL_  "SC_Verification" ENUM  "No","Yes";
BA_DEF_DEF_  "NmAsrMessage" "No";
BA_DEF_DEF_  "GenSigCycleTime" 0;
BA_DEF_DEF_  "NmMessage" "No";
BA_DEF_DEF_  "SC_Message" "No";
BA_DEF_DEF_  "DiagState" "No";
BA_DEF_DEF_  "SC_LinkPos" 0;
BA_DEF_DEF_  "DiagRequest" "No";
BA_DEF_DEF_  "DiagFdOnly" "No";
BA_DEF_DEF_  "DiagResponse" "No";
BA_DEF_DEF_  "SCP_AuthInfoTxLength" 0;
BA_DEF_DEF_  "GenMsgSendType" "Cyclic";
BA_DEF_DEF_  "SCP_DataId" 0;
BA_DEF_DEF_  "GenMsgCycleTime" 0;
BA_DEF_DEF_  "SCP_FreshnessValueId" 0;
BA_DEF_DEF_  "SCP_FreshnessValueLength" 0;
BA_DEF_DEF_  "GenSigStartValue" 0;
BA_DEF_DEF_  "SCL_CryptographicMessageID" 0;
BA_DEF_DEF_  "GenSigInactiveValue" 0;
BA_DEF_DEF_  "GenSigSendType" "Cyclic";
BA_DEF_DEF_  "SCP_FreshnessValueTxLength" 0;
BA_DEF_DEF_  "GenMsgCycleTimeFast" 0;
BA_DEF_DEF_  "GenMsgNrOfRepetition" 0;
BA_DEF_DEF_  "DiagConnection" 0;
BA_DEF_DEF_  "GenMsgDelayTime" 0;
BA_DEF_DEF_  "CANFD_BRS" "1";
BA_DEF_DEF_  "VFrameFormat" "StandardCAN";
BA_DEF_DEF_  "GenMsgILSupport" "Yes";
BA_DEF_DEF_  "GenMsgStartDelayTime" 0;
BA_DEF_DEF_  "E2EP01DataLength" 0;
BA_DEF_DEF_  "E2EP01DataId" 0;
BA_DEF_DEF_  "sigSecLevel" "";
BA_DEF_DEF_  "sigConfig" "";
BA_DEF_DEF_  "sigExplanation" "";
BA_DEF_DEF_REL_ "SC_Verification" "No";
BA_DEF_DEF_  "SystemSignalLongSymbol" "";
BA_ "GenMsgCycleTime" BO_ 870 10;
BA_ "VFrameFormat" BO_ 870 14;
BA_ "GenMsgCycleTime" BO_ 880 100;
BA_ "VFrameFormat" BO_ 880 14;
BA_ "E2EP01DataId" BO_ 881 58;
BA_ "E2EP01DataLength" BO_ 881 64;
BA_ "GenMsgCycleTime" BO_ 881 100;
BA_ "VFrameFormat" BO_ 881 14;
BA_ "E2EP01DataId" BO_ 882 28;
BA_ "E2EP01DataLength" BO_ 882 64;
BA_ "GenMsgCycleTime" BO_ 882 100;
BA_ "SCL_CryptographicMessageID" BO_ 882 882;
BA_ "SCP_AuthInfoTxLength" BO_ 882 24;
BA_ "SCP_DataId" BO_ 882 882;
BA_ "SCP_FreshnessValueId" BO_ 882 882;
BA_ "SCP_FreshnessValueLength" BO_ 882 64;
BA_ "SCP_FreshnessValueTxLength" BO_ 882 8;
BA_ "SC_LinkPos" BO_ 882 64;
BA_ "SC_Message" BO_ 882 1;
BA_ "VFrameFormat" BO_ 882 14;
BA_ "GenMsgCycleTime" BO_ 883 100;
BA_ "VFrameFormat" BO_ 883 14;
BA_ "E2EP01DataId" BO_ 884 59;
BA_ "E2EP01DataLength" BO_ 884 64;
BA_ "GenMsgCycleTime" BO_ 884 100;
BA_ "VFrameFormat" BO_ 884 14;
BA_ "GenMsgCycleTime" BO_ 886 100;
BA_ "VFrameFormat" BO_ 886 14;
BA_ "GenMsgCycleTime" BO_ 888 100;
BA_ "VFrameFormat" BO_ 888 14;
BA_ "GenMsgCycleTime" BO_ 889 100;
BA_ "VFrameFormat" BO_ 889 14;
BA_ "GenMsgCycleTime" BO_ 890 100;
BA_ "VFrameFormat" BO_ 890 14;
BA_ "GenMsgCycleTime" BO_ 891 100;
BA_ "GenMsgDelayTime" BO_ 891 20;
BA_ "SCP_FreshnessValueLength" BO_ 891 64;
BA_ "GenMsgNrOfRepetition" BO_ 891 3;
BA_ "GenMsgCycleTimeFast" BO_ 891 20;
BA_ "VFrameFormat" BO_ 891 14;
BA_ "GenMsgCycleTime" BO_ 897 100;
BA_ "VFrameFormat" BO_ 897 14;
BA_ "GenMsgCycleTime" BO_ 901 100;
BA_ "GenMsgCycleTimeFast" BO_ 901 10;
BA_ "GenMsgDelayTime" BO_ 901 10;
BA_ "GenMsgNrOfRepetition" BO_ 901 5;
BA_ "VFrameFormat" BO_ 901 14;
BA_ "GenMsgCycleTime" BO_ 928 500;
BA_ "VFrameFormat" BO_ 928 14;
BA_ "GenMsgCycleTime" BO_ 929 500;
BA_ "VFrameFormat" BO_ 929 14;
BA_ "GenMsgCycleTime" BO_ 930 500;
BA_ "VFrameFormat" BO_ 930 14;
BA_ "GenMsgCycleTime" BO_ 933 500;
BA_ "VFrameFormat" BO_ 933 14;
BA_ "GenMsgCycleTime" BO_ 934 500;
BA_ "VFrameFormat" BO_ 934 14;
BA_ "GenMsgCycleTime" BO_ 935 500;
BA_ "VFrameFormat" BO_ 935 14;
BA_ "E2EP01DataId" BO_ 944 64;
BA_ "E2EP01DataLength" BO_ 944 64;
BA_ "GenMsgCycleTime" BO_ 944 100;
BA_ "VFrameFormat" BO_ 944 14;
BA_ "GenMsgCycleTime" BO_ 965 100;
BA_ "VFrameFormat" BO_ 965 14;
BA_ "GenMsgCycleTime" BO_ 992 1000;
BA_ "VFrameFormat" BO_ 992 14;
BA_ "GenMsgILSupport" BO_ 1025 0;
BA_ "GenMsgSendType" BO_ 1025 8;
BA_ "NmAsrMessage" BO_ 1025 1;
BA_ "NmMessage" BO_ 1025 1;
BA_ "VFrameFormat" BO_ 1025 14;
BA_ "GenMsgILSupport" BO_ 1043 0;
BA_ "GenMsgSendType" BO_ 1043 8;
BA_ "NmAsrMessage" BO_ 1043 1;
BA_ "NmMessage" BO_ 1043 1;
BA_ "VFrameFormat" BO_ 1043 14;
BA_ "sigConfig" SG_ 870 MCU_R_SecuStsChkFlt "null";
BA_ "sigExplanation" SG_ 870 MCU_R_SecuStsChkFlt "null";
BA_ "sigSecLevel" SG_ 870 MCU_R_SecuStsChkFlt "null";
BA_ "sigConfig" SG_ 870 MCU_R_HVActvDchaFlt "null";
BA_ "sigExplanation" SG_ 870 MCU_R_HVActvDchaFlt "null";
BA_ "sigSecLevel" SG_ 870 MCU_R_HVActvDchaFlt "null";
BA_ "sigConfig" SG_ 870 MCU_R_CtrlPanTChkCircFlt "null";
BA_ "sigExplanation" SG_ 870 MCU_R_CtrlPanTChkCircFlt "null";
BA_ "sigSecLevel" SG_ 870 MCU_R_CtrlPanTChkCircFlt "null";
BA_ "sigConfig" SG_ 870 MCU_R_ComLostFlt_VCU "null";
BA_ "sigExplanation" SG_ 870 MCU_R_ComLostFlt_VCU "null";
BA_ "sigSecLevel" SG_ 870 MCU_R_ComLostFlt_VCU "null";
BA_ "sigConfig" SG_ 870 MCU_R_E2EFlt "null";
BA_ "sigExplanation" SG_ 870 MCU_R_E2EFlt "null";
BA_ "sigSecLevel" SG_ 870 MCU_R_E2EFlt "null";
BA_ "sigConfig" SG_ 870 MCU_R_I2TFlt "null";
BA_ "sigExplanation" SG_ 870 MCU_R_I2TFlt "null";
BA_ "sigSecLevel" SG_ 870 MCU_R_I2TFlt "null";
BA_ "sigConfig" SG_ 870 MCU_R_OperModFlt "null";
BA_ "sigExplanation" SG_ 870 MCU_R_OperModFlt "null";
BA_ "sigSecLevel" SG_ 870 MCU_R_OperModFlt "null";
BA_ "sigConfig" SG_ 870 MCU_R_CooltOverTFlt "null";
BA_ "sigExplanation" SG_ 870 MCU_R_CooltOverTFlt "null";
BA_ "sigSecLevel" SG_ 870 MCU_R_CooltOverTFlt "null";
BA_ "sigConfig" SG_ 870 MCU_R_PhaCrtSampleCircFltU "null";
BA_ "sigExplanation" SG_ 870 MCU_R_PhaCrtSampleCircFltU "null";
BA_ "sigSecLevel" SG_ 870 MCU_R_PhaCrtSampleCircFltU "null";
BA_ "sigConfig" SG_ 870 MCU_R_PhaCrtSampleCircFltV "null";
BA_ "sigExplanation" SG_ 870 MCU_R_PhaCrtSampleCircFltV "null";
BA_ "sigSecLevel" SG_ 870 MCU_R_PhaCrtSampleCircFltV "null";
BA_ "sigConfig" SG_ 870 MCU_R_PhaCrtSampleCircFltW "null";
BA_ "sigExplanation" SG_ 870 MCU_R_PhaCrtSampleCircFltW "null";
BA_ "sigSecLevel" SG_ 870 MCU_R_PhaCrtSampleCircFltW "null";
BA_ "sigConfig" SG_ 870 MCU_R_ThreePhaCrtChkFlt "null";
BA_ "sigExplanation" SG_ 870 MCU_R_ThreePhaCrtChkFlt "null";
BA_ "sigSecLevel" SG_ 870 MCU_R_ThreePhaCrtChkFlt "null";
BA_ "sigConfig" SG_ 870 MCU_R_DCBusUnderVoltFlt "null";
BA_ "sigExplanation" SG_ 870 MCU_R_DCBusUnderVoltFlt "null";
BA_ "sigSecLevel" SG_ 870 MCU_R_DCBusUnderVoltFlt "null";
BA_ "sigConfig" SG_ 870 MCU_R_DCBusOverVoltFlt "null";
BA_ "sigExplanation" SG_ 870 MCU_R_DCBusOverVoltFlt "null";
BA_ "sigSecLevel" SG_ 870 MCU_R_DCBusOverVoltFlt "null";
BA_ "sigConfig" SG_ 870 MCU_R_PosnSnsrChkCircFlt "null";
BA_ "sigExplanation" SG_ 870 MCU_R_PosnSnsrChkCircFlt "null";
BA_ "sigSecLevel" SG_ 870 MCU_R_PosnSnsrChkCircFlt "null";
BA_ "sigConfig" SG_ 870 MCU_R_DCBusVoltSampleCircFlt "null";
BA_ "sigExplanation" SG_ 870 MCU_R_DCBusVoltSampleCircFlt "null";
BA_ "sigSecLevel" SG_ 870 MCU_R_DCBusVoltSampleCircFlt "null";
BA_ "sigConfig" SG_ 870 MCU_R_OverSpdFlt "null";
BA_ "sigExplanation" SG_ 870 MCU_R_OverSpdFlt "null";
BA_ "sigSecLevel" SG_ 870 MCU_R_OverSpdFlt "null";
BA_ "sigConfig" SG_ 870 MCU_R_IGBTOverTFltU "null";
BA_ "sigExplanation" SG_ 870 MCU_R_IGBTOverTFltU "null";
BA_ "sigSecLevel" SG_ 870 MCU_R_IGBTOverTFltU "null";
BA_ "sigConfig" SG_ 870 MCU_R_IGBTTChkCircFltU "null";
BA_ "sigExplanation" SG_ 870 MCU_R_IGBTTChkCircFltU "null";
BA_ "sigSecLevel" SG_ 870 MCU_R_IGBTTChkCircFltU "null";
BA_ "sigConfig" SG_ 870 MCU_R_IGBTTChkCircFltV "null";
BA_ "sigExplanation" SG_ 870 MCU_R_IGBTTChkCircFltV "null";
BA_ "sigSecLevel" SG_ 870 MCU_R_IGBTTChkCircFltV "null";
BA_ "sigConfig" SG_ 870 MCU_R_IGBTTChkCircFltW "null";
BA_ "sigExplanation" SG_ 870 MCU_R_IGBTTChkCircFltW "null";
BA_ "sigSecLevel" SG_ 870 MCU_R_IGBTTChkCircFltW "null";
BA_ "sigConfig" SG_ 870 MCU_R_OverTFlt "null";
BA_ "sigExplanation" SG_ 870 MCU_R_OverTFlt "null";
BA_ "sigSecLevel" SG_ 870 MCU_R_OverTFlt "null";
BA_ "sigConfig" SG_ 870 MCU_R_TChkCircFlt "null";
BA_ "sigExplanation" SG_ 870 MCU_R_TChkCircFlt "null";
BA_ "sigSecLevel" SG_ 870 MCU_R_TChkCircFlt "null";
BA_ "sigConfig" SG_ 870 MCU_R_CtrlPanOverTFlt "null";
BA_ "sigExplanation" SG_ 870 MCU_R_CtrlPanOverTFlt "null";
BA_ "sigSecLevel" SG_ 870 MCU_R_CtrlPanOverTFlt "null";
BA_ "sigConfig" SG_ 870 MCU_R_LVPwrSplyUnderVoltFlt "null";
BA_ "sigExplanation" SG_ 870 MCU_R_LVPwrSplyUnderVoltFlt "null";
BA_ "sigSecLevel" SG_ 870 MCU_R_LVPwrSplyUnderVoltFlt "null";
BA_ "sigConfig" SG_ 870 MCU_R_LVPwrSplyOverVoltFlt "null";
BA_ "sigExplanation" SG_ 870 MCU_R_LVPwrSplyOverVoltFlt "null";
BA_ "sigSecLevel" SG_ 870 MCU_R_LVPwrSplyOverVoltFlt "null";
BA_ "sigConfig" SG_ 870 MCU_R_FbTqStsChkFlt "null";
BA_ "sigExplanation" SG_ 870 MCU_R_FbTqStsChkFlt "null";
BA_ "sigSecLevel" SG_ 870 MCU_R_FbTqStsChkFlt "null";
BA_ "sigConfig" SG_ 870 MCU_R_PhaCrtSwOverCrtFltU "null";
BA_ "sigExplanation" SG_ 870 MCU_R_PhaCrtSwOverCrtFltU "null";
BA_ "sigSecLevel" SG_ 870 MCU_R_PhaCrtSwOverCrtFltU "null";
BA_ "sigConfig" SG_ 870 MCU_R_TqCmdOverLimFlt "null";
BA_ "sigExplanation" SG_ 870 MCU_R_TqCmdOverLimFlt "null";
BA_ "sigSecLevel" SG_ 870 MCU_R_TqCmdOverLimFlt "null";
BA_ "sigConfig" SG_ 870 MCU_R_PwrSplyModFlt "null";
BA_ "sigExplanation" SG_ 870 MCU_R_PwrSplyModFlt "null";
BA_ "sigSecLevel" SG_ 870 MCU_R_PwrSplyModFlt "null";
BA_ "sigConfig" SG_ 870 MCU_R_IGBTThreePhaTChkFlt "null";
BA_ "sigExplanation" SG_ 870 MCU_R_IGBTThreePhaTChkFlt "null";
BA_ "sigSecLevel" SG_ 870 MCU_R_IGBTThreePhaTChkFlt "null";
BA_ "sigConfig" SG_ 870 MCU_R_RotCalFlt "null";
BA_ "sigExplanation" SG_ 870 MCU_R_RotCalFlt "null";
BA_ "sigSecLevel" SG_ 870 MCU_R_RotCalFlt "null";
BA_ "sigConfig" SG_ 870 MCU_R_IntComFlt "null";
BA_ "sigExplanation" SG_ 870 MCU_R_IntComFlt "null";
BA_ "sigSecLevel" SG_ 870 MCU_R_IntComFlt "null";
BA_ "sigConfig" SG_ 870 MCU_R_IntTqChkFlt "null";
BA_ "sigExplanation" SG_ 870 MCU_R_IntTqChkFlt "null";
BA_ "sigSecLevel" SG_ 870 MCU_R_IntTqChkFlt "null";
BA_ "sigConfig" SG_ 870 MCU_R_IGBTDesatFltTop "null";
BA_ "sigExplanation" SG_ 870 MCU_R_IGBTDesatFltTop "null";
BA_ "sigSecLevel" SG_ 870 MCU_R_IGBTDesatFltTop "null";
BA_ "sigConfig" SG_ 870 MCU_R_IGBTDesatFltBot "null";
BA_ "sigExplanation" SG_ 870 MCU_R_IGBTDesatFltBot "null";
BA_ "sigSecLevel" SG_ 870 MCU_R_IGBTDesatFltBot "null";
BA_ "sigConfig" SG_ 870 MCU_R_PhaCrtSwOverCrtFltV "null";
BA_ "sigExplanation" SG_ 870 MCU_R_PhaCrtSwOverCrtFltV "null";
BA_ "sigSecLevel" SG_ 870 MCU_R_PhaCrtSwOverCrtFltV "null";
BA_ "sigConfig" SG_ 870 MCU_R_PhaCrtSwOverCrtFltW "null";
BA_ "sigExplanation" SG_ 870 MCU_R_PhaCrtSwOverCrtFltW "null";
BA_ "sigSecLevel" SG_ 870 MCU_R_PhaCrtSwOverCrtFltW "null";
BA_ "sigConfig" SG_ 870 MCU_R_IGBTOverTFltV "null";
BA_ "sigExplanation" SG_ 870 MCU_R_IGBTOverTFltV "null";
BA_ "sigSecLevel" SG_ 870 MCU_R_IGBTOverTFltV "null";
BA_ "sigConfig" SG_ 870 MCU_R_IGBTOverTFltW "null";
BA_ "sigExplanation" SG_ 870 MCU_R_IGBTOverTFltW "null";
BA_ "sigSecLevel" SG_ 870 MCU_R_IGBTOverTFltW "null";
BA_ "sigConfig" SG_ 880 BMS_PwrBattOverChrgAlrm "null";
BA_ "sigExplanation" SG_ 880 BMS_PwrBattOverChrgAlrm "null";
BA_ "sigSecLevel" SG_ 880 BMS_PwrBattOverChrgAlrm "null";
BA_ "sigConfig" SG_ 880 BMS_PwrBattUderVoltFlt "null";
BA_ "sigExplanation" SG_ 880 BMS_PwrBattUderVoltFlt "null";
BA_ "sigSecLevel" SG_ 880 BMS_PwrBattUderVoltFlt "null";
BA_ "sigConfig" SG_ 880 BMS_CellUnderVoltFailFlt "null";
BA_ "sigExplanation" SG_ 880 BMS_CellUnderVoltFailFlt "null";
BA_ "sigSecLevel" SG_ 880 BMS_CellUnderVoltFailFlt "null";
BA_ "sigConfig" SG_ 880 BMS_CellUnderVoltFlt "null";
BA_ "sigExplanation" SG_ 880 BMS_CellUnderVoltFlt "null";
BA_ "sigSecLevel" SG_ 880 BMS_CellUnderVoltFlt "null";
BA_ "sigConfig" SG_ 880 BMS_BattBalActv "null";
BA_ "sigExplanation" SG_ 880 BMS_BattBalActv "null";
BA_ "sigSecLevel" SG_ 880 BMS_BattBalActv "null";
BA_ "sigConfig" SG_ 880 BMS_BattPack1OverVoltFlt "null";
BA_ "sigExplanation" SG_ 880 BMS_BattPack1OverVoltFlt "null";
BA_ "sigSecLevel" SG_ 880 BMS_BattPack1OverVoltFlt "null";
BA_ "sigConfig" SG_ 880 BMS_BattPack1UnderVoltFlt "null";
BA_ "sigExplanation" SG_ 880 BMS_BattPack1UnderVoltFlt "null";
BA_ "sigSecLevel" SG_ 880 BMS_BattPack1UnderVoltFlt "null";
BA_ "sigConfig" SG_ 880 BMS_DCChrgSoktOverTFlt "null";
BA_ "sigExplanation" SG_ 880 BMS_DCChrgSoktOverTFlt "null";
BA_ "sigSecLevel" SG_ 880 BMS_DCChrgSoktOverTFlt "null";
BA_ "sigConfig" SG_ 880 BMS_ComLostFlt_BOBC "null";
BA_ "sigExplanation" SG_ 880 BMS_ComLostFlt_BOBC "null";
BA_ "sigSecLevel" SG_ 880 BMS_ComLostFlt_BOBC "null";
BA_ "sigConfig" SG_ 880 BMS_ComLostFlt_CCU "null";
BA_ "sigExplanation" SG_ 880 BMS_ComLostFlt_CCU "null";
BA_ "sigSecLevel" SG_ 880 BMS_ComLostFlt_CCU "null";
BA_ "sigConfig" SG_ 880 BMS_ACChrgSoktOverTFlt "null";
BA_ "sigExplanation" SG_ 880 BMS_ACChrgSoktOverTFlt "null";
BA_ "sigSecLevel" SG_ 880 BMS_ACChrgSoktOverTFlt "null";
BA_ "sigConfig" SG_ 880 BMS_ACCrtFlt "null";
BA_ "sigExplanation" SG_ 880 BMS_ACCrtFlt "null";
BA_ "sigSecLevel" SG_ 880 BMS_ACCrtFlt "null";
BA_ "sigConfig" SG_ 880 BMS_InsulChkFltLvl2ProtFlg "null";
BA_ "sigExplanation" SG_ 880 BMS_InsulChkFltLvl2ProtFlg "null";
BA_ "sigSecLevel" SG_ 880 BMS_InsulChkFltLvl2ProtFlg "null";
BA_ "sigConfig" SG_ 880 BMS_PwrBattOverTAlrm "null";
BA_ "sigExplanation" SG_ 880 BMS_PwrBattOverTAlrm "null";
BA_ "sigSecLevel" SG_ 880 BMS_PwrBattOverTAlrm "null";
BA_ "sigConfig" SG_ 880 BMS_PwrBattHLVIntlkFlt "null";
BA_ "sigExplanation" SG_ 880 BMS_PwrBattHLVIntlkFlt "null";
BA_ "sigSecLevel" SG_ 880 BMS_PwrBattHLVIntlkFlt "null";
BA_ "sigConfig" SG_ 880 BMS_PwrBattExtShoCirc "null";
BA_ "sigExplanation" SG_ 880 BMS_PwrBattExtShoCirc "null";
BA_ "sigSecLevel" SG_ 880 BMS_PwrBattExtShoCirc "null";
BA_ "sigConfig" SG_ 880 BMS_PwrBattIntShoCirc "null";
BA_ "sigExplanation" SG_ 880 BMS_PwrBattIntShoCirc "null";
BA_ "sigSecLevel" SG_ 880 BMS_PwrBattIntShoCirc "null";
BA_ "sigConfig" SG_ 880 BMS_PwrBattTUnbal "null";
BA_ "sigExplanation" SG_ 880 BMS_PwrBattTUnbal "null";
BA_ "sigSecLevel" SG_ 880 BMS_PwrBattTUnbal "null";
BA_ "sigConfig" SG_ 880 BMS_PwrBattTRiseFast "null";
BA_ "sigExplanation" SG_ 880 BMS_PwrBattTRiseFast "null";
BA_ "sigSecLevel" SG_ 880 BMS_PwrBattTRiseFast "null";
BA_ "sigConfig" SG_ 880 BMS_PwrBattIntTotVoltChkFlt "null";
BA_ "sigExplanation" SG_ 880 BMS_PwrBattIntTotVoltChkFlt "null";
BA_ "sigSecLevel" SG_ 880 BMS_PwrBattIntTotVoltChkFlt "null";
BA_ "sigConfig" SG_ 880 BMS_PwrBattExtTotVoltChkFlt "null";
BA_ "sigExplanation" SG_ 880 BMS_PwrBattExtTotVoltChkFlt "null";
BA_ "sigSecLevel" SG_ 880 BMS_PwrBattExtTotVoltChkFlt "null";
BA_ "sigConfig" SG_ 880 BMS_PwrBattNegRlyAdh "null";
BA_ "sigExplanation" SG_ 880 BMS_PwrBattNegRlyAdh "null";
BA_ "sigSecLevel" SG_ 880 BMS_PwrBattNegRlyAdh "null";
BA_ "sigConfig" SG_ 880 BMS_PwrBattPrecRlyAdh "null";
BA_ "sigExplanation" SG_ 880 BMS_PwrBattPrecRlyAdh "null";
BA_ "sigSecLevel" SG_ 880 BMS_PwrBattPrecRlyAdh "null";
BA_ "sigConfig" SG_ 880 BMS_PwrBattPosRlyAdh "null";
BA_ "sigExplanation" SG_ 880 BMS_PwrBattPosRlyAdh "null";
BA_ "sigSecLevel" SG_ 880 BMS_PwrBattPosRlyAdh "null";
BA_ "sigConfig" SG_ 880 BMS_PwrBattNegRlyBreak "null";
BA_ "sigExplanation" SG_ 880 BMS_PwrBattNegRlyBreak "null";
BA_ "sigSecLevel" SG_ 880 BMS_PwrBattNegRlyBreak "null";
BA_ "sigConfig" SG_ 880 BMS_PwrBattPrecRlyBreak "null";
BA_ "sigExplanation" SG_ 880 BMS_PwrBattPrecRlyBreak "null";
BA_ "sigSecLevel" SG_ 880 BMS_PwrBattPrecRlyBreak "null";
BA_ "sigConfig" SG_ 880 BMS_PwrBattPosRlyBreak "null";
BA_ "sigExplanation" SG_ 880 BMS_PwrBattPosRlyBreak "null";
BA_ "sigSecLevel" SG_ 880 BMS_PwrBattPosRlyBreak "null";
BA_ "sigConfig" SG_ 880 BMS_PwrBattPrecRBreak "null";
BA_ "sigExplanation" SG_ 880 BMS_PwrBattPrecRBreak "null";
BA_ "sigSecLevel" SG_ 880 BMS_PwrBattPrecRBreak "null";
BA_ "sigConfig" SG_ 880 BMS_PwrBattMSDBreak "null";
BA_ "sigExplanation" SG_ 880 BMS_PwrBattMSDBreak "null";
BA_ "sigSecLevel" SG_ 880 BMS_PwrBattMSDBreak "null";
BA_ "sigConfig" SG_ 880 BMS_PwrBattExtTotVoltChkFltV2 "null";
BA_ "sigExplanation" SG_ 880 BMS_PwrBattExtTotVoltChkFltV2 "null";
BA_ "sigSecLevel" SG_ 880 BMS_PwrBattExtTotVoltChkFltV2 "null";
BA_ "sigConfig" SG_ 880 BMS_BCUEEPROMReadWrFlt "null";
BA_ "sigExplanation" SG_ 880 BMS_BCUEEPROMReadWrFlt "null";
BA_ "sigSecLevel" SG_ 880 BMS_BCUEEPROMReadWrFlt "null";
BA_ "sigConfig" SG_ 880 BMS_PwrBattPosRlyDrvChFlt "null";
BA_ "sigExplanation" SG_ 880 BMS_PwrBattPosRlyDrvChFlt "null";
BA_ "sigSecLevel" SG_ 880 BMS_PwrBattPosRlyDrvChFlt "null";
BA_ "sigConfig" SG_ 880 BMS_PwrBattPrecRlyDrvChFlt "null";
BA_ "sigExplanation" SG_ 880 BMS_PwrBattPrecRlyDrvChFlt "null";
BA_ "sigSecLevel" SG_ 880 BMS_PwrBattPrecRlyDrvChFlt "null";
BA_ "sigConfig" SG_ 880 BMS_PwrBattInsulChkFlt "null";
BA_ "sigExplanation" SG_ 880 BMS_PwrBattInsulChkFlt "null";
BA_ "sigSecLevel" SG_ 880 BMS_PwrBattInsulChkFlt "null";
BA_ "sigConfig" SG_ 880 BMS_PwrBattNegRlyDrvChFlt "null";
BA_ "sigExplanation" SG_ 880 BMS_PwrBattNegRlyDrvChFlt "null";
BA_ "sigSecLevel" SG_ 880 BMS_PwrBattNegRlyDrvChFlt "null";
BA_ "sigConfig" SG_ 880 BMS_PwrBattCellVoltUnbal "null";
BA_ "sigExplanation" SG_ 880 BMS_PwrBattCellVoltUnbal "null";
BA_ "sigSecLevel" SG_ 880 BMS_PwrBattCellVoltUnbal "null";
BA_ "sigConfig" SG_ 880 BMS_EEPROMReadWrFlt "null";
BA_ "sigExplanation" SG_ 880 BMS_EEPROMReadWrFlt "null";
BA_ "sigSecLevel" SG_ 880 BMS_EEPROMReadWrFlt "null";
BA_ "sigConfig" SG_ 880 BMS_PwrBattSysIntComFlt "null";
BA_ "sigExplanation" SG_ 880 BMS_PwrBattSysIntComFlt "null";
BA_ "sigSecLevel" SG_ 880 BMS_PwrBattSysIntComFlt "null";
BA_ "sigConfig" SG_ 880 BMS_InsulRLo "null";
BA_ "sigExplanation" SG_ 880 BMS_InsulRLo "null";
BA_ "sigSecLevel" SG_ 880 BMS_InsulRLo "null";
BA_ "sigConfig" SG_ 880 BMS_CopRowLooseFlt "null";
BA_ "sigExplanation" SG_ 880 BMS_CopRowLooseFlt "null";
BA_ "sigSecLevel" SG_ 880 BMS_CopRowLooseFlt "null";
BA_ "sigConfig" SG_ 880 BMS_SubEEPROMReadWrFlt "null";
BA_ "sigExplanation" SG_ 880 BMS_SubEEPROMReadWrFlt "null";
BA_ "sigSecLevel" SG_ 880 BMS_SubEEPROMReadWrFlt "null";
BA_ "sigConfig" SG_ 880 BMS_SubCellVoltCollctnCircFlt "null";
BA_ "sigExplanation" SG_ 880 BMS_SubCellVoltCollctnCircFlt "null";
BA_ "sigSecLevel" SG_ 880 BMS_SubCellVoltCollctnCircFlt "null";
BA_ "sigConfig" SG_ 880 BMS_SubModleVoltCollctnCircFlt "null";
BA_ "sigExplanation" SG_ 880 BMS_SubModleVoltCollctnCircFlt "null";
BA_ "sigSecLevel" SG_ 880 BMS_SubModleVoltCollctnCircFlt "null";
BA_ "sigConfig" SG_ 880 BMS_SubTCollctnCircFlt "null";
BA_ "sigExplanation" SG_ 880 BMS_SubTCollctnCircFlt "null";
BA_ "sigSecLevel" SG_ 880 BMS_SubTCollctnCircFlt "null";
BA_ "sigConfig" SG_ 880 BMS_SubActvBalChFlt "null";
BA_ "sigExplanation" SG_ 880 BMS_SubActvBalChFlt "null";
BA_ "sigSecLevel" SG_ 880 BMS_SubActvBalChFlt "null";
BA_ "sigConfig" SG_ 880 BMS_SubPasBalChFlt "null";
BA_ "sigExplanation" SG_ 880 BMS_SubPasBalChFlt "null";
BA_ "sigSecLevel" SG_ 880 BMS_SubPasBalChFlt "null";
BA_ "sigConfig" SG_ 880 BMS_SubOperModRespFlt "null";
BA_ "sigExplanation" SG_ 880 BMS_SubOperModRespFlt "null";
BA_ "sigSecLevel" SG_ 880 BMS_SubOperModRespFlt "null";
BA_ "sigConfig" SG_ 880 BMS_BattCellVoltUnbalAlrm "null";
BA_ "sigExplanation" SG_ 880 BMS_BattCellVoltUnbalAlrm "null";
BA_ "sigSecLevel" SG_ 880 BMS_BattCellVoltUnbalAlrm "null";
BA_ "sigConfig" SG_ 880 BMS_ComLostFlt_ECC "null";
BA_ "sigExplanation" SG_ 880 BMS_ComLostFlt_ECC "null";
BA_ "sigSecLevel" SG_ 880 BMS_ComLostFlt_ECC "null";
BA_ "sigConfig" SG_ 880 BMS_SubComLostFlt_VBUBMS "null";
BA_ "sigExplanation" SG_ 880 BMS_SubComLostFlt_VBUBMS "null";
BA_ "sigSecLevel" SG_ 880 BMS_SubComLostFlt_VBUBMS "null";
BA_ "sigConfig" SG_ 880 BMS_PrecFailFlt "null";
BA_ "sigExplanation" SG_ 880 BMS_PrecFailFlt "null";
BA_ "sigSecLevel" SG_ 880 BMS_PrecFailFlt "null";
BA_ "sigConfig" SG_ 880 BMS_PwrBattCellOverVolt "null";
BA_ "sigExplanation" SG_ 880 BMS_PwrBattCellOverVolt "null";
BA_ "sigSecLevel" SG_ 880 BMS_PwrBattCellOverVolt "null";
BA_ "sigConfig" SG_ 880 BMS_TotVoltOver "null";
BA_ "sigExplanation" SG_ 880 BMS_TotVoltOver "null";
BA_ "sigSecLevel" SG_ 880 BMS_TotVoltOver "null";
BA_ "sigConfig" SG_ 880 BMS_PwrBattIntTotVoltChkFltV1 "null";
BA_ "sigExplanation" SG_ 880 BMS_PwrBattIntTotVoltChkFltV1 "null";
BA_ "sigSecLevel" SG_ 880 BMS_PwrBattIntTotVoltChkFltV1 "null";
BA_ "sigConfig" SG_ 880 BMS_TotCrtChkFlt "null";
BA_ "sigExplanation" SG_ 880 BMS_TotCrtChkFlt "null";
BA_ "sigSecLevel" SG_ 880 BMS_TotCrtChkFlt "null";
BA_ "sigConfig" SG_ 880 BMS_ComLostFlt_VCU "null";
BA_ "sigExplanation" SG_ 880 BMS_ComLostFlt_VCU "null";
BA_ "sigSecLevel" SG_ 880 BMS_ComLostFlt_VCU "null";
BA_ "sigConfig" SG_ 880 BMS_BattReDrvHLVIntlkFlt "null";
BA_ "sigExplanation" SG_ 880 BMS_BattReDrvHLVIntlkFlt "null";
BA_ "sigSecLevel" SG_ 880 BMS_BattReDrvHLVIntlkFlt "null";
BA_ "sigConfig" SG_ 880 BMS_ComOverTiFlt_ECC "null";
BA_ "sigExplanation" SG_ 880 BMS_ComOverTiFlt_ECC "null";
BA_ "sigSecLevel" SG_ 880 BMS_ComOverTiFlt_ECC "null";
BA_ "sigConfig" SG_ 880 BMS_LVPwrSplyFlt "null";
BA_ "sigExplanation" SG_ 880 BMS_LVPwrSplyFlt "null";
BA_ "sigSecLevel" SG_ 880 BMS_LVPwrSplyFlt "null";
BA_ "sigConfig" SG_ 880 BMS_ComOverTiFlt_BOBC "null";
BA_ "sigExplanation" SG_ 880 BMS_ComOverTiFlt_BOBC "null";
BA_ "sigSecLevel" SG_ 880 BMS_ComOverTiFlt_BOBC "null";
BA_ "GenSigStartValue" SG_ 881 WTC_B_PCBT 48;
BA_ "sigConfig" SG_ 881 WTC_B_PCBT "null";
BA_ "sigExplanation" SG_ 881 WTC_B_PCBT "null";
BA_ "sigSecLevel" SG_ 881 WTC_B_PCBT "null";
BA_ "sigConfig" SG_ 881 WTC_B_Crt "null";
BA_ "sigExplanation" SG_ 881 WTC_B_Crt "null";
BA_ "sigSecLevel" SG_ 881 WTC_B_Crt "null";
BA_ "sigConfig" SG_ 881 WTC_B_CrtSts "null";
BA_ "sigExplanation" SG_ 881 WTC_B_CrtSts "null";
BA_ "sigSecLevel" SG_ 881 WTC_B_CrtSts "null";
BA_ "sigConfig" SG_ 881 WTC_B_HVIntlkFlt "null";
BA_ "sigExplanation" SG_ 881 WTC_B_HVIntlkFlt "null";
BA_ "sigSecLevel" SG_ 881 WTC_B_HVIntlkFlt "null";
BA_ "sigConfig" SG_ 881 WTC_B_ComLost_ECC "null";
BA_ "sigExplanation" SG_ 881 WTC_B_ComLost_ECC "null";
BA_ "sigSecLevel" SG_ 881 WTC_B_ComLost_ECC "null";
BA_ "sigConfig" SG_ 881 WTC_B_OverCrtFlt "null";
BA_ "sigExplanation" SG_ 881 WTC_B_OverCrtFlt "null";
BA_ "sigSecLevel" SG_ 881 WTC_B_OverCrtFlt "null";
BA_ "sigConfig" SG_ 881 WTC_B_HVUnderVoltFlt "null";
BA_ "sigExplanation" SG_ 881 WTC_B_HVUnderVoltFlt "null";
BA_ "sigSecLevel" SG_ 881 WTC_B_HVUnderVoltFlt "null";
BA_ "sigConfig" SG_ 881 WTC_B_HVOverVoltFlt "null";
BA_ "sigExplanation" SG_ 881 WTC_B_HVOverVoltFlt "null";
BA_ "sigSecLevel" SG_ 881 WTC_B_HVOverVoltFlt "null";
BA_ "sigConfig" SG_ 881 WTC_B_ChkBattOverVoltFlt "null";
BA_ "sigExplanation" SG_ 881 WTC_B_ChkBattOverVoltFlt "null";
BA_ "sigSecLevel" SG_ 881 WTC_B_ChkBattOverVoltFlt "null";
BA_ "sigConfig" SG_ 881 WTC_B_ChkBattUnderVoltFlt "null";
BA_ "sigExplanation" SG_ 881 WTC_B_ChkBattUnderVoltFlt "null";
BA_ "sigSecLevel" SG_ 881 WTC_B_ChkBattUnderVoltFlt "null";
BA_ "sigConfig" SG_ 881 WTC_B_InlTSnsrFlt "null";
BA_ "sigExplanation" SG_ 881 WTC_B_InlTSnsrFlt "null";
BA_ "sigSecLevel" SG_ 881 WTC_B_InlTSnsrFlt "null";
BA_ "sigConfig" SG_ 881 WTC_B_OutlTSnsrFlt "null";
BA_ "sigExplanation" SG_ 881 WTC_B_OutlTSnsrFlt "null";
BA_ "sigSecLevel" SG_ 881 WTC_B_OutlTSnsrFlt "null";
BA_ "sigConfig" SG_ 881 WTC_B_InlOverTFlt "null";
BA_ "sigExplanation" SG_ 881 WTC_B_InlOverTFlt "null";
BA_ "sigSecLevel" SG_ 881 WTC_B_InlOverTFlt "null";
BA_ "sigConfig" SG_ 881 WTC_B_OutlOverTFlt "null";
BA_ "sigExplanation" SG_ 881 WTC_B_OutlOverTFlt "null";
BA_ "sigSecLevel" SG_ 881 WTC_B_OutlOverTFlt "null";
BA_ "sigConfig" SG_ 881 WTC_B_PCBOverTFlt "null";
BA_ "sigExplanation" SG_ 881 WTC_B_PCBOverTFlt "null";
BA_ "sigSecLevel" SG_ 881 WTC_B_PCBOverTFlt "null";
BA_ "sigConfig" SG_ 881 WTC_B_PCBTSnsrFlt "null";
BA_ "sigExplanation" SG_ 881 WTC_B_PCBTSnsrFlt "null";
BA_ "sigSecLevel" SG_ 881 WTC_B_PCBTSnsrFlt "null";
BA_ "sigConfig" SG_ 881 WTC_B_PwrOutpFlt "null";
BA_ "sigExplanation" SG_ 881 WTC_B_PwrOutpFlt "null";
BA_ "sigSecLevel" SG_ 881 WTC_B_PwrOutpFlt "null";
BA_ "sigConfig" SG_ 882 BMS_372_382_CheckSum "null";
BA_ "sigExplanation" SG_ 882 BMS_372_382_CheckSum "null";
BA_ "sigSecLevel" SG_ 882 BMS_372_382_CheckSum "null";
BA_ "sigConfig" SG_ 882 BMS_372_382_AliveCounter "null";
BA_ "sigExplanation" SG_ 882 BMS_372_382_AliveCounter "null";
BA_ "sigSecLevel" SG_ 882 BMS_372_382_AliveCounter "null";
BA_ "GenSigStartValue" SG_ 882 BMS_CellMinT 48;
BA_ "sigConfig" SG_ 882 BMS_CellMinT "null";
BA_ "sigExplanation" SG_ 882 BMS_CellMinT "null";
BA_ "sigSecLevel" SG_ 882 BMS_CellMinT "null";
BA_ "sigConfig" SG_ 882 BMS_CellDiffT "null";
BA_ "sigExplanation" SG_ 882 BMS_CellDiffT "null";
BA_ "sigSecLevel" SG_ 882 BMS_CellDiffT "null";
BA_ "GenSigStartValue" SG_ 882 BMS_CellMaxT 48;
BA_ "sigConfig" SG_ 882 BMS_CellMaxT "null";
BA_ "sigExplanation" SG_ 882 BMS_CellMaxT "null";
BA_ "sigSecLevel" SG_ 882 BMS_CellMaxT "A(B)";
BA_ "GenSigStartValue" SG_ 882 BMS_BattAvrgT 48;
BA_ "sigConfig" SG_ 882 BMS_BattAvrgT "null";
BA_ "sigExplanation" SG_ 882 BMS_BattAvrgT "null";
BA_ "sigSecLevel" SG_ 882 BMS_BattAvrgT "null";
BA_ "sigConfig" SG_ 882 BMS_PwrBattHeatgMngDmd "null";
BA_ "sigExplanation" SG_ 882 BMS_PwrBattHeatgMngDmd "null";
BA_ "sigSecLevel" SG_ 882 BMS_PwrBattHeatgMngDmd "null";
BA_ "sigConfig" SG_ 882 BMS_ECCSysAllwDwnPwrCmd "null";
BA_ "sigExplanation" SG_ 882 BMS_ECCSysAllwDwnPwrCmd "null";
BA_ "sigSecLevel" SG_ 882 BMS_ECCSysAllwDwnPwrCmd "null";
BA_ "GenSigStartValue" SG_ 882 BMS_BattInlTDmd 48;
BA_ "sigConfig" SG_ 882 BMS_BattInlTDmd "null";
BA_ "sigExplanation" SG_ 882 BMS_BattInlTDmd "null";
BA_ "sigSecLevel" SG_ 882 BMS_BattInlTDmd "null";
BA_ "sigConfig" SG_ 882 BMS_372_SSecOC_Fresh_Byte0 "null";
BA_ "sigExplanation" SG_ 882 BMS_372_SSecOC_Fresh_Byte0 "null";
BA_ "sigSecLevel" SG_ 882 BMS_372_SSecOC_Fresh_Byte0 "null";
BA_ "sigConfig" SG_ 882 BMS_372_SSecOC_MAC_Byte0 "null";
BA_ "sigExplanation" SG_ 882 BMS_372_SSecOC_MAC_Byte0 "null";
BA_ "sigSecLevel" SG_ 882 BMS_372_SSecOC_MAC_Byte0 "null";
BA_ "sigConfig" SG_ 882 BMS_372_SSecOC_MAC_Byte1 "null";
BA_ "sigExplanation" SG_ 882 BMS_372_SSecOC_MAC_Byte1 "null";
BA_ "sigSecLevel" SG_ 882 BMS_372_SSecOC_MAC_Byte1 "null";
BA_ "sigConfig" SG_ 882 BMS_372_SSecOC_MAC_Byte2 "null";
BA_ "sigExplanation" SG_ 882 BMS_372_SSecOC_MAC_Byte2 "null";
BA_ "sigSecLevel" SG_ 882 BMS_372_SSecOC_MAC_Byte2 "null";
BA_ "sigConfig" SG_ 883 ECC_CrtSts "null";
BA_ "sigExplanation" SG_ 883 ECC_CrtSts "null";
BA_ "sigSecLevel" SG_ 883 ECC_CrtSts "null";
BA_ "sigConfig" SG_ 883 ECC_IninSts "null";
BA_ "sigExplanation" SG_ 883 ECC_IninSts "null";
BA_ "sigSecLevel" SG_ 883 ECC_IninSts "null";
BA_ "sigConfig" SG_ 883 ECC_PwrSysHeatMngtSts "null";
BA_ "sigExplanation" SG_ 883 ECC_PwrSysHeatMngtSts "null";
BA_ "sigSecLevel" SG_ 883 ECC_PwrSysHeatMngtSts "null";
BA_ "sigConfig" SG_ 883 ECC_ACSts "null";
BA_ "sigExplanation" SG_ 883 ECC_ACSts "null";
BA_ "sigSecLevel" SG_ 883 ECC_ACSts "null";
BA_ "sigConfig" SG_ 883 ECC_AirClnSts "null";
BA_ "sigExplanation" SG_ 883 ECC_AirClnSts "null";
BA_ "sigSecLevel" SG_ 883 ECC_AirClnSts "null";
BA_ "sigConfig" SG_ 883 ECC_WindSpdSts "null";
BA_ "sigExplanation" SG_ 883 ECC_WindSpdSts "null";
BA_ "sigSecLevel" SG_ 883 ECC_WindSpdSts "null";
BA_ "sigConfig" SG_ 883 ECC_BackRowAirOutlModSts "null";
BA_ "sigExplanation" SG_ 883 ECC_BackRowAirOutlModSts "null";
BA_ "sigSecLevel" SG_ 883 ECC_BackRowAirOutlModSts "null";
BA_ "sigConfig" SG_ 883 ECC_DrvrTSetSts "null";
BA_ "sigExplanation" SG_ 883 ECC_DrvrTSetSts "null";
BA_ "sigSecLevel" SG_ 883 ECC_DrvrTSetSts "null";
BA_ "sigConfig" SG_ 883 ECC_PassTSetSts "null";
BA_ "sigExplanation" SG_ 883 ECC_PassTSetSts "null";
BA_ "sigSecLevel" SG_ 883 ECC_PassTSetSts "null";
BA_ "sigConfig" SG_ 883 ECC_HeatSts "null";
BA_ "sigExplanation" SG_ 883 ECC_HeatSts "null";
BA_ "sigSecLevel" SG_ 883 ECC_HeatSts "null";
BA_ "sigConfig" SG_ 883 ECC_AUTOSts "null";
BA_ "sigExplanation" SG_ 883 ECC_AUTOSts "null";
BA_ "sigSecLevel" SG_ 883 ECC_AUTOSts "null";
BA_ "sigConfig" SG_ 883 ECC_SYNCSts "null";
BA_ "sigExplanation" SG_ 883 ECC_SYNCSts "null";
BA_ "sigSecLevel" SG_ 883 ECC_SYNCSts "null";
BA_ "sigConfig" SG_ 883 ECC_InfoSysWrmColdDisp "null";
BA_ "sigExplanation" SG_ 883 ECC_InfoSysWrmColdDisp "null";
BA_ "sigSecLevel" SG_ 883 ECC_InfoSysWrmColdDisp "null";
BA_ "sigConfig" SG_ 883 ECC_CircSts "null";
BA_ "sigExplanation" SG_ 883 ECC_CircSts "null";
BA_ "sigSecLevel" SG_ 883 ECC_CircSts "null";
BA_ "sigConfig" SG_ 883 ECC_ParticleConcVld "null";
BA_ "sigExplanation" SG_ 883 ECC_ParticleConcVld "null";
BA_ "sigSecLevel" SG_ 883 ECC_ParticleConcVld "null";
BA_ "GenSigStartValue" SG_ 883 ECC_OutdT 48;
BA_ "sigConfig" SG_ 883 ECC_OutdT "null";
BA_ "sigExplanation" SG_ 883 ECC_OutdT "null";
BA_ "sigSecLevel" SG_ 883 ECC_OutdT "null";
BA_ "sigConfig" SG_ 883 ECC_OutdTVld "null";
BA_ "sigExplanation" SG_ 883 ECC_OutdTVld "null";
BA_ "sigSecLevel" SG_ 883 ECC_OutdTVld "null";
BA_ "sigConfig" SG_ 883 ECC_MaxFrntDefrst "null";
BA_ "sigExplanation" SG_ 883 ECC_MaxFrntDefrst "null";
BA_ "sigSecLevel" SG_ 883 ECC_MaxFrntDefrst "null";
BA_ "sigConfig" SG_ 883 ECC_HeatMngtSysFlt "null";
BA_ "sigExplanation" SG_ 883 ECC_HeatMngtSysFlt "null";
BA_ "sigSecLevel" SG_ 883 ECC_HeatMngtSysFlt "null";
BA_ "sigConfig" SG_ 883 ECC_HeatMngtFctLim "null";
BA_ "sigExplanation" SG_ 883 ECC_HeatMngtFctLim "null";
BA_ "sigSecLevel" SG_ 883 ECC_HeatMngtFctLim "null";
BA_ "sigConfig" SG_ 883 ECC_DrvrAirOutlMod "null";
BA_ "sigExplanation" SG_ 883 ECC_DrvrAirOutlMod "null";
BA_ "sigSecLevel" SG_ 883 ECC_DrvrAirOutlMod "null";
BA_ "sigConfig" SG_ 883 ECC_PassAirOutlMod "null";
BA_ "sigExplanation" SG_ 883 ECC_PassAirOutlMod "null";
BA_ "sigSecLevel" SG_ 883 ECC_PassAirOutlMod "null";
BA_ "sigConfig" SG_ 883 ECC_RemSts "null";
BA_ "sigExplanation" SG_ 883 ECC_RemSts "null";
BA_ "sigSecLevel" SG_ 883 ECC_RemSts "null";
BA_ "GenSigStartValue" SG_ 884 WTC_H_PCBT 48;
BA_ "sigConfig" SG_ 884 WTC_H_PCBT "null";
BA_ "sigExplanation" SG_ 884 WTC_H_PCBT "null";
BA_ "sigSecLevel" SG_ 884 WTC_H_PCBT "null";
BA_ "sigConfig" SG_ 884 WTC_H_Crt "null";
BA_ "sigExplanation" SG_ 884 WTC_H_Crt "null";
BA_ "sigSecLevel" SG_ 884 WTC_H_Crt "null";
BA_ "sigConfig" SG_ 884 WTC_H_CrtSts "null";
BA_ "sigExplanation" SG_ 884 WTC_H_CrtSts "null";
BA_ "sigSecLevel" SG_ 884 WTC_H_CrtSts "null";
BA_ "sigConfig" SG_ 884 WTC_H_HVIntlkFlt "null";
BA_ "sigExplanation" SG_ 884 WTC_H_HVIntlkFlt "null";
BA_ "sigSecLevel" SG_ 884 WTC_H_HVIntlkFlt "null";
BA_ "sigConfig" SG_ 884 WTC_H_ComLost_ECC "null";
BA_ "sigExplanation" SG_ 884 WTC_H_ComLost_ECC "null";
BA_ "sigSecLevel" SG_ 884 WTC_H_ComLost_ECC "null";
BA_ "sigConfig" SG_ 884 WTC_H_OverCrtFlt "null";
BA_ "sigExplanation" SG_ 884 WTC_H_OverCrtFlt "null";
BA_ "sigSecLevel" SG_ 884 WTC_H_OverCrtFlt "null";
BA_ "sigConfig" SG_ 884 WTC_H_HVUnderVoltFlt "null";
BA_ "sigExplanation" SG_ 884 WTC_H_HVUnderVoltFlt "null";
BA_ "sigSecLevel" SG_ 884 WTC_H_HVUnderVoltFlt "null";
BA_ "sigConfig" SG_ 884 WTC_H_HVOverVoltFlt "null";
BA_ "sigExplanation" SG_ 884 WTC_H_HVOverVoltFlt "null";
BA_ "sigSecLevel" SG_ 884 WTC_H_HVOverVoltFlt "null";
BA_ "sigConfig" SG_ 884 WTC_H_ChkBattOverVoltFlt "null";
BA_ "sigExplanation" SG_ 884 WTC_H_ChkBattOverVoltFlt "null";
BA_ "sigSecLevel" SG_ 884 WTC_H_ChkBattOverVoltFlt "null";
BA_ "sigConfig" SG_ 884 WTC_H_ChkBattUnderVoltFlt "null";
BA_ "sigExplanation" SG_ 884 WTC_H_ChkBattUnderVoltFlt "null";
BA_ "sigSecLevel" SG_ 884 WTC_H_ChkBattUnderVoltFlt "null";
BA_ "sigConfig" SG_ 884 WTC_H_InlTSnsrFlt "null";
BA_ "sigExplanation" SG_ 884 WTC_H_InlTSnsrFlt "null";
BA_ "sigSecLevel" SG_ 884 WTC_H_InlTSnsrFlt "null";
BA_ "sigConfig" SG_ 884 WTC_H_OutlTSnsrFlt "null";
BA_ "sigExplanation" SG_ 884 WTC_H_OutlTSnsrFlt "null";
BA_ "sigSecLevel" SG_ 884 WTC_H_OutlTSnsrFlt "null";
BA_ "sigConfig" SG_ 884 WTC_H_InlOverTFlt "null";
BA_ "sigExplanation" SG_ 884 WTC_H_InlOverTFlt "null";
BA_ "sigSecLevel" SG_ 884 WTC_H_InlOverTFlt "null";
BA_ "sigConfig" SG_ 884 WTC_H_OutlOverTFlt "null";
BA_ "sigExplanation" SG_ 884 WTC_H_OutlOverTFlt "null";
BA_ "sigSecLevel" SG_ 884 WTC_H_OutlOverTFlt "null";
BA_ "sigConfig" SG_ 884 WTC_H_PCBOverTFlt "null";
BA_ "sigExplanation" SG_ 884 WTC_H_PCBOverTFlt "null";
BA_ "sigSecLevel" SG_ 884 WTC_H_PCBOverTFlt "null";
BA_ "sigConfig" SG_ 884 WTC_H_PCBTSnsrFlt "null";
BA_ "sigExplanation" SG_ 884 WTC_H_PCBTSnsrFlt "null";
BA_ "sigSecLevel" SG_ 884 WTC_H_PCBTSnsrFlt "null";
BA_ "sigConfig" SG_ 884 WTC_H_PwrOutpFlt "null";
BA_ "sigExplanation" SG_ 884 WTC_H_PwrOutpFlt "null";
BA_ "sigSecLevel" SG_ 884 WTC_H_PwrOutpFlt "null";
BA_ "sigConfig" SG_ 886 WTC_B_InlT "null";
BA_ "sigExplanation" SG_ 886 WTC_B_InlT "null";
BA_ "sigSecLevel" SG_ 886 WTC_B_InlT "null";
BA_ "sigConfig" SG_ 886 WTC_B_OutlT "null";
BA_ "sigExplanation" SG_ 886 WTC_B_OutlT "null";
BA_ "sigSecLevel" SG_ 886 WTC_B_OutlT "null";
BA_ "sigConfig" SG_ 886 WTC_B_CrtPwr "null";
BA_ "sigExplanation" SG_ 886 WTC_B_CrtPwr "null";
BA_ "sigSecLevel" SG_ 886 WTC_B_CrtPwr "null";
BA_ "sigConfig" SG_ 886 WTC_B_CrtT "null";
BA_ "sigExplanation" SG_ 886 WTC_B_CrtT "null";
BA_ "sigSecLevel" SG_ 886 WTC_B_CrtT "null";
BA_ "sigConfig" SG_ 886 WTC_B_IninSts "null";
BA_ "sigExplanation" SG_ 886 WTC_B_IninSts "null";
BA_ "sigSecLevel" SG_ 886 WTC_B_IninSts "null";
BA_ "sigConfig" SG_ 886 WTC_B_HVPwrSplySts "null";
BA_ "sigExplanation" SG_ 886 WTC_B_HVPwrSplySts "null";
BA_ "sigSecLevel" SG_ 886 WTC_B_HVPwrSplySts "null";
BA_ "sigConfig" SG_ 886 WTC_B_ActGear "null";
BA_ "sigExplanation" SG_ 886 WTC_B_ActGear "null";
BA_ "sigSecLevel" SG_ 886 WTC_B_ActGear "null";
BA_ "sigConfig" SG_ 886 WTC_B_Mod "null";
BA_ "sigExplanation" SG_ 886 WTC_B_Mod "null";
BA_ "sigSecLevel" SG_ 886 WTC_B_Mod "null";
BA_ "sigConfig" SG_ 888 ECC_MCUFCooltFlow "null";
BA_ "sigExplanation" SG_ 888 ECC_MCUFCooltFlow "null";
BA_ "sigSecLevel" SG_ 888 ECC_MCUFCooltFlow "null";
BA_ "sigConfig" SG_ 888 ECC_MCURCooltFlow "null";
BA_ "sigExplanation" SG_ 888 ECC_MCURCooltFlow "null";
BA_ "sigSecLevel" SG_ 888 ECC_MCURCooltFlow "null";
BA_ "sigConfig" SG_ 888 ECC_LeOutlUpDwnMotActvSts "null";
BA_ "sigExplanation" SG_ 888 ECC_LeOutlUpDwnMotActvSts "null";
BA_ "sigSecLevel" SG_ 888 ECC_LeOutlUpDwnMotActvSts "null";
BA_ "sigConfig" SG_ 888 ECC_LeOutlLeRiMotActvSts "null";
BA_ "sigExplanation" SG_ 888 ECC_LeOutlLeRiMotActvSts "null";
BA_ "sigSecLevel" SG_ 888 ECC_LeOutlLeRiMotActvSts "null";
BA_ "sigConfig" SG_ 888 ECC_LeOutlDamprMotActvSts "null";
BA_ "sigExplanation" SG_ 888 ECC_LeOutlDamprMotActvSts "null";
BA_ "sigSecLevel" SG_ 888 ECC_LeOutlDamprMotActvSts "null";
BA_ "sigConfig" SG_ 888 ECC_MidLeOutlUpDwnMotActvSts "null";
BA_ "sigExplanation" SG_ 888 ECC_MidLeOutlUpDwnMotActvSts "null";
BA_ "sigSecLevel" SG_ 888 ECC_MidLeOutlUpDwnMotActvSts "null";
BA_ "sigConfig" SG_ 888 ECC_MidLeOutlLeRiMotActvSts "null";
BA_ "sigExplanation" SG_ 888 ECC_MidLeOutlLeRiMotActvSts "null";
BA_ "sigSecLevel" SG_ 888 ECC_MidLeOutlLeRiMotActvSts "null";
BA_ "sigConfig" SG_ 888 ECC_MidLeOutlDamprMotActvSts "null";
BA_ "sigExplanation" SG_ 888 ECC_MidLeOutlDamprMotActvSts "null";
BA_ "sigSecLevel" SG_ 888 ECC_MidLeOutlDamprMotActvSts "null";
BA_ "sigConfig" SG_ 888 ECC_MidRiOutlUpDwnMotActvSts "null";
BA_ "sigExplanation" SG_ 888 ECC_MidRiOutlUpDwnMotActvSts "null";
BA_ "sigSecLevel" SG_ 888 ECC_MidRiOutlUpDwnMotActvSts "null";
BA_ "sigConfig" SG_ 888 ECC_MidRiOutlLeRiMotActvSts "null";
BA_ "sigExplanation" SG_ 888 ECC_MidRiOutlLeRiMotActvSts "null";
BA_ "sigSecLevel" SG_ 888 ECC_MidRiOutlLeRiMotActvSts "null";
BA_ "sigConfig" SG_ 888 ECC_MidRiOutlDamprMotActvSts "null";
BA_ "sigExplanation" SG_ 888 ECC_MidRiOutlDamprMotActvSts "null";
BA_ "sigSecLevel" SG_ 888 ECC_MidRiOutlDamprMotActvSts "null";
BA_ "sigConfig" SG_ 888 ECC_RiOutlUpDwnMotActvSts "null";
BA_ "sigExplanation" SG_ 888 ECC_RiOutlUpDwnMotActvSts "null";
BA_ "sigSecLevel" SG_ 888 ECC_RiOutlUpDwnMotActvSts "null";
BA_ "sigConfig" SG_ 888 ECC_RiOutlLeRiMotActvSts "null";
BA_ "sigExplanation" SG_ 888 ECC_RiOutlLeRiMotActvSts "null";
BA_ "sigSecLevel" SG_ 888 ECC_RiOutlLeRiMotActvSts "null";
BA_ "sigConfig" SG_ 888 ECC_RiOutlDamprMotActvSts "null";
BA_ "sigExplanation" SG_ 888 ECC_RiOutlDamprMotActvSts "null";
BA_ "sigSecLevel" SG_ 888 ECC_RiOutlDamprMotActvSts "null";
BA_ "GenSigStartValue" SG_ 889 WTC_H_InpT 48;
BA_ "sigConfig" SG_ 889 WTC_H_InpT "null";
BA_ "sigExplanation" SG_ 889 WTC_H_InpT "null";
BA_ "sigSecLevel" SG_ 889 WTC_H_InpT "null";
BA_ "GenSigStartValue" SG_ 889 WTC_H_OutpT 48;
BA_ "sigConfig" SG_ 889 WTC_H_OutpT "null";
BA_ "sigExplanation" SG_ 889 WTC_H_OutpT "null";
BA_ "sigSecLevel" SG_ 889 WTC_H_OutpT "null";
BA_ "sigConfig" SG_ 889 WTC_H_CrtPwr "null";
BA_ "sigExplanation" SG_ 889 WTC_H_CrtPwr "null";
BA_ "sigSecLevel" SG_ 889 WTC_H_CrtPwr "null";
BA_ "GenSigStartValue" SG_ 889 WTC_H_CrtT 48;
BA_ "sigConfig" SG_ 889 WTC_H_CrtT "null";
BA_ "sigExplanation" SG_ 889 WTC_H_CrtT "null";
BA_ "sigSecLevel" SG_ 889 WTC_H_CrtT "null";
BA_ "sigConfig" SG_ 889 WTC_H_IninSts "null";
BA_ "sigExplanation" SG_ 889 WTC_H_IninSts "null";
BA_ "sigSecLevel" SG_ 889 WTC_H_IninSts "null";
BA_ "sigConfig" SG_ 889 WTC_H_HVPwrSplySts "null";
BA_ "sigExplanation" SG_ 889 WTC_H_HVPwrSplySts "null";
BA_ "sigSecLevel" SG_ 889 WTC_H_HVPwrSplySts "null";
BA_ "sigConfig" SG_ 889 WTC_H_ActGear "null";
BA_ "sigExplanation" SG_ 889 WTC_H_ActGear "null";
BA_ "sigSecLevel" SG_ 889 WTC_H_ActGear "null";
BA_ "sigConfig" SG_ 889 WTC_H_Mod "null";
BA_ "sigExplanation" SG_ 889 WTC_H_Mod "null";
BA_ "sigSecLevel" SG_ 889 WTC_H_Mod "null";
BA_ "sigConfig" SG_ 890 ICC_LeOutlUpDwnMotActvCmd "null";
BA_ "sigExplanation" SG_ 890 ICC_LeOutlUpDwnMotActvCmd "null";
BA_ "sigSecLevel" SG_ 890 ICC_LeOutlUpDwnMotActvCmd "null";
BA_ "sigConfig" SG_ 890 ICC_LeOutlLeRiMotActvCmd "null";
BA_ "sigExplanation" SG_ 890 ICC_LeOutlLeRiMotActvCmd "null";
BA_ "sigSecLevel" SG_ 890 ICC_LeOutlLeRiMotActvCmd "null";
BA_ "sigConfig" SG_ 890 ICC_LeOutlDamprMotActvCmd "null";
BA_ "sigExplanation" SG_ 890 ICC_LeOutlDamprMotActvCmd "null";
BA_ "sigSecLevel" SG_ 890 ICC_LeOutlDamprMotActvCmd "null";
BA_ "sigConfig" SG_ 890 ICC_MidLeOutlUpDwnMotActvCmd "null";
BA_ "sigExplanation" SG_ 890 ICC_MidLeOutlUpDwnMotActvCmd "null";
BA_ "sigSecLevel" SG_ 890 ICC_MidLeOutlUpDwnMotActvCmd "null";
BA_ "sigConfig" SG_ 890 ICC_MidLeOutlLeRiMotActvCmd "null";
BA_ "sigExplanation" SG_ 890 ICC_MidLeOutlLeRiMotActvCmd "null";
BA_ "sigSecLevel" SG_ 890 ICC_MidLeOutlLeRiMotActvCmd "null";
BA_ "sigConfig" SG_ 890 ICC_MidLeOutlDamprMotActvCmd "null";
BA_ "sigExplanation" SG_ 890 ICC_MidLeOutlDamprMotActvCmd "null";
BA_ "sigSecLevel" SG_ 890 ICC_MidLeOutlDamprMotActvCmd "null";
BA_ "sigConfig" SG_ 890 ICC_MidRiOutlUpDwnMotActvCmd "null";
BA_ "sigExplanation" SG_ 890 ICC_MidRiOutlUpDwnMotActvCmd "null";
BA_ "sigSecLevel" SG_ 890 ICC_MidRiOutlUpDwnMotActvCmd "null";
BA_ "sigConfig" SG_ 890 ICC_MidRiOutlLeRiMotActvCmd "null";
BA_ "sigExplanation" SG_ 890 ICC_MidRiOutlLeRiMotActvCmd "null";
BA_ "sigSecLevel" SG_ 890 ICC_MidRiOutlLeRiMotActvCmd "null";
BA_ "sigConfig" SG_ 890 ICC_MidRiOutlDamprMotActvCmd "null";
BA_ "sigExplanation" SG_ 890 ICC_MidRiOutlDamprMotActvCmd "null";
BA_ "sigSecLevel" SG_ 890 ICC_MidRiOutlDamprMotActvCmd "null";
BA_ "sigConfig" SG_ 890 ICC_RiOutlUpDwnMotActvCmd "null";
BA_ "sigExplanation" SG_ 890 ICC_RiOutlUpDwnMotActvCmd "null";
BA_ "sigSecLevel" SG_ 890 ICC_RiOutlUpDwnMotActvCmd "null";
BA_ "sigConfig" SG_ 890 ICC_RiOutlLeRiMotActvCmd "null";
BA_ "sigExplanation" SG_ 890 ICC_RiOutlLeRiMotActvCmd "null";
BA_ "sigSecLevel" SG_ 890 ICC_RiOutlLeRiMotActvCmd "null";
BA_ "sigConfig" SG_ 890 ICC_RiOutlDamprMotActvCmd "null";
BA_ "sigExplanation" SG_ 890 ICC_RiOutlDamprMotActvCmd "null";
BA_ "sigSecLevel" SG_ 890 ICC_RiOutlDamprMotActvCmd "null";
BA_ "sigConfig" SG_ 891 PKC_SysAlrmVld "null";
BA_ "sigExplanation" SG_ 891 PKC_SysAlrmVld "null";
BA_ "sigSecLevel" SG_ 891 PKC_SysAlrmVld "null";
BA_ "GenSigSendType" SG_ 891 PKC_RemLockCmd_Key 4;
BA_ "sigConfig" SG_ 891 PKC_RemLockCmd_Key "null";
BA_ "sigExplanation" SG_ 891 PKC_RemLockCmd_Key "null";
BA_ "sigSecLevel" SG_ 891 PKC_RemLockCmd_Key "null";
BA_ "sigConfig" SG_ 891 PKC_KeyStsMod "null";
BA_ "sigExplanation" SG_ 891 PKC_KeyStsMod "null";
BA_ "sigSecLevel" SG_ 891 PKC_KeyStsMod "null";
BA_ "GenSigSendType" SG_ 891 PKC_KeyID 4;
BA_ "sigConfig" SG_ 891 PKC_KeyID "null";
BA_ "sigExplanation" SG_ 891 PKC_KeyID "null";
BA_ "sigSecLevel" SG_ 891 PKC_KeyID "null";
BA_ "sigConfig" SG_ 891 PKC_KeyInCarRmn "null";
BA_ "sigExplanation" SG_ 891 PKC_KeyInCarRmn "null";
BA_ "sigSecLevel" SG_ 891 PKC_KeyInCarRmn "null";
BA_ "GenSigSendType" SG_ 891 PKC_RemLockCmd 2;
BA_ "sigConfig" SG_ 891 PKC_RemLockCmd "null";
BA_ "sigExplanation" SG_ 891 PKC_RemLockCmd "null";
BA_ "sigSecLevel" SG_ 891 PKC_RemLockCmd "null";
BA_ "sigConfig" SG_ 891 PKC_BatterySts "null";
BA_ "sigExplanation" SG_ 891 PKC_BatterySts "null";
BA_ "sigSecLevel" SG_ 891 PKC_BatterySts "null";
BA_ "sigConfig" SG_ 891 PKC_KeyOutdCarPromt "null";
BA_ "sigExplanation" SG_ 891 PKC_KeyOutdCarPromt "null";
BA_ "sigSecLevel" SG_ 891 PKC_KeyOutdCarPromt "null";
BA_ "GenSigSendType" SG_ 891 PKC_DoorOpenRmd 4;
BA_ "GenSigSendType" SG_ 891 PKC_StrtFailTyp 4;
BA_ "sigConfig" SG_ 891 PKC_StrtFailTyp "null";
BA_ "sigExplanation" SG_ 891 PKC_StrtFailTyp "null";
BA_ "sigSecLevel" SG_ 891 PKC_StrtFailTyp "null";
BA_ "GenSigSendType" SG_ 891 PKC_LockKeyInCarInd 4;
BA_ "sigConfig" SG_ 891 PKC_KeySts "null";
BA_ "sigExplanation" SG_ 891 PKC_KeySts "null";
BA_ "sigSecLevel" SG_ 891 PKC_KeySts "null";
BA_ "sigConfig" SG_ 891 PKC_37B_SSecOC_Fresh_Byte0 "null";
BA_ "sigExplanation" SG_ 891 PKC_37B_SSecOC_Fresh_Byte0 "null";
BA_ "sigSecLevel" SG_ 891 PKC_37B_SSecOC_Fresh_Byte0 "null";
BA_ "sigConfig" SG_ 891 PKC_37B_SSecOC_MAC_Byte0 "null";
BA_ "sigExplanation" SG_ 891 PKC_37B_SSecOC_MAC_Byte0 "null";
BA_ "sigSecLevel" SG_ 891 PKC_37B_SSecOC_MAC_Byte0 "null";
BA_ "sigConfig" SG_ 891 PKC_37B_SSecOC_MAC_Byte1 "null";
BA_ "sigExplanation" SG_ 891 PKC_37B_SSecOC_MAC_Byte1 "null";
BA_ "sigSecLevel" SG_ 891 PKC_37B_SSecOC_MAC_Byte1 "null";
BA_ "sigConfig" SG_ 891 PKC_37B_SSecOC_MAC_Byte2 "null";
BA_ "sigExplanation" SG_ 891 PKC_37B_SSecOC_MAC_Byte2 "null";
BA_ "sigSecLevel" SG_ 891 PKC_37B_SSecOC_MAC_Byte2 "null";
BA_ "sigConfig" SG_ 897 RAC_OnOff "null";
BA_ "sigExplanation" SG_ 897 RAC_OnOff "null";
BA_ "sigSecLevel" SG_ 897 RAC_OnOff "null";
BA_ "sigConfig" SG_ 897 RAC_ReOperPanSts "null";
BA_ "sigExplanation" SG_ 897 RAC_ReOperPanSts "null";
BA_ "sigSecLevel" SG_ 897 RAC_ReOperPanSts "null";
BA_ "sigConfig" SG_ 897 RAC_ReOperPanLockSts "null";
BA_ "sigExplanation" SG_ 897 RAC_ReOperPanLockSts "null";
BA_ "sigSecLevel" SG_ 897 RAC_ReOperPanLockSts "null";
BA_ "sigConfig" SG_ 897 RAC_BackRowAirOutlModReq "null";
BA_ "sigExplanation" SG_ 897 RAC_BackRowAirOutlModReq "null";
BA_ "sigSecLevel" SG_ 897 RAC_BackRowAirOutlModReq "null";
BA_ "sigConfig" SG_ 897 RAC_VolInc "null";
BA_ "sigExplanation" SG_ 897 RAC_VolInc "null";
BA_ "sigSecLevel" SG_ 897 RAC_VolInc "null";
BA_ "sigConfig" SG_ 897 RAC_VolDec "null";
BA_ "sigExplanation" SG_ 897 RAC_VolDec "null";
BA_ "sigSecLevel" SG_ 897 RAC_VolDec "null";
BA_ "sigConfig" SG_ 897 RAC_VolCtrl "null";
BA_ "sigExplanation" SG_ 897 RAC_VolCtrl "null";
BA_ "sigSecLevel" SG_ 897 RAC_VolCtrl "null";
BA_ "sigConfig" SG_ 897 RAC_TempCtrlnc "null";
BA_ "sigExplanation" SG_ 897 RAC_TempCtrlnc "null";
BA_ "sigSecLevel" SG_ 897 RAC_TempCtrlnc "null";
BA_ "sigConfig" SG_ 897 RAC_TempCtrDec "null";
BA_ "sigExplanation" SG_ 897 RAC_TempCtrDec "null";
BA_ "sigSecLevel" SG_ 897 RAC_TempCtrDec "null";
BA_ "sigConfig" SG_ 897 RAC_BlowCtrInc "null";
BA_ "sigExplanation" SG_ 897 RAC_BlowCtrInc "null";
BA_ "sigSecLevel" SG_ 897 RAC_BlowCtrInc "null";
BA_ "sigConfig" SG_ 897 RAC_BlowCtrDec "null";
BA_ "sigExplanation" SG_ 897 RAC_BlowCtrDec "null";
BA_ "sigSecLevel" SG_ 897 RAC_BlowCtrDec "null";
BA_ "sigConfig" SG_ 897 RAC_AirOutlLeftBtn "null";
BA_ "sigExplanation" SG_ 897 RAC_AirOutlLeftBtn "null";
BA_ "sigSecLevel" SG_ 897 RAC_AirOutlLeftBtn "null";
BA_ "sigConfig" SG_ 897 RAC_AirOutlRightBtn "null";
BA_ "sigExplanation" SG_ 897 RAC_AirOutlRightBtn "null";
BA_ "sigSecLevel" SG_ 897 RAC_AirOutlRightBtn "null";
BA_ "sigConfig" SG_ 897 RAC_SeatHRearLeftBtn "null";
BA_ "sigExplanation" SG_ 897 RAC_SeatHRearLeftBtn "null";
BA_ "sigSecLevel" SG_ 897 RAC_SeatHRearLeftBtn "null";
BA_ "sigConfig" SG_ 897 RAC_SeatHRearRightBtn "null";
BA_ "sigExplanation" SG_ 897 RAC_SeatHRearRightBtn "null";
BA_ "sigSecLevel" SG_ 897 RAC_SeatHRearRightBtn "null";
BA_ "sigConfig" SG_ 901 TBOX_PreHeatDepartTi1_Hr "null";
BA_ "sigExplanation" SG_ 901 TBOX_PreHeatDepartTi1_Hr "null";
BA_ "sigSecLevel" SG_ 901 TBOX_PreHeatDepartTi1_Hr "null";
BA_ "sigConfig" SG_ 901 TBOX_PreHeatDepartTi1_Mins "null";
BA_ "sigExplanation" SG_ 901 TBOX_PreHeatDepartTi1_Mins "null";
BA_ "sigSecLevel" SG_ 901 TBOX_PreHeatDepartTi1_Mins "null";
BA_ "sigConfig" SG_ 901 TBOX_PreHeatDepartSet "null";
BA_ "sigExplanation" SG_ 901 TBOX_PreHeatDepartSet "null";
BA_ "sigSecLevel" SG_ 901 TBOX_PreHeatDepartSet "null";
BA_ "sigConfig" SG_ 901 TBOX_MonPreHeatDepartSet "null";
BA_ "sigExplanation" SG_ 901 TBOX_MonPreHeatDepartSet "null";
BA_ "sigSecLevel" SG_ 901 TBOX_MonPreHeatDepartSet "null";
BA_ "sigConfig" SG_ 901 TBOX_TuePreHeatDepartSet "null";
BA_ "sigExplanation" SG_ 901 TBOX_TuePreHeatDepartSet "null";
BA_ "sigSecLevel" SG_ 901 TBOX_TuePreHeatDepartSet "null";
BA_ "sigConfig" SG_ 901 TBOX_WedPreHeatDepartSet "null";
BA_ "sigExplanation" SG_ 901 TBOX_WedPreHeatDepartSet "null";
BA_ "sigSecLevel" SG_ 901 TBOX_WedPreHeatDepartSet "null";
BA_ "sigConfig" SG_ 901 TBOX_ThuPreHeatDepartSet "null";
BA_ "sigExplanation" SG_ 901 TBOX_ThuPreHeatDepartSet "null";
BA_ "sigSecLevel" SG_ 901 TBOX_ThuPreHeatDepartSet "null";
BA_ "sigConfig" SG_ 901 TBOX_FriPreHeatDepartSet "null";
BA_ "sigExplanation" SG_ 901 TBOX_FriPreHeatDepartSet "null";
BA_ "sigSecLevel" SG_ 901 TBOX_FriPreHeatDepartSet "null";
BA_ "sigConfig" SG_ 901 TBOX_SatPreHeatDepartSet "null";
BA_ "sigExplanation" SG_ 901 TBOX_SatPreHeatDepartSet "null";
BA_ "sigSecLevel" SG_ 901 TBOX_SatPreHeatDepartSet "null";
BA_ "sigConfig" SG_ 901 TBOX_SunPreHeatDepartSet "null";
BA_ "sigExplanation" SG_ 901 TBOX_SunPreHeatDepartSet "null";
BA_ "sigSecLevel" SG_ 901 TBOX_SunPreHeatDepartSet "null";
BA_ "sigConfig" SG_ 901 TBOX_PreCdnTarT "null";
BA_ "sigExplanation" SG_ 901 TBOX_PreCdnTarT "null";
BA_ "sigSecLevel" SG_ 901 TBOX_PreCdnTarT "null";
BA_ "sigConfig" SG_ 928 BMS_Cont_Error_StuckOpen_HV_Pos1 "null";
BA_ "sigExplanation" SG_ 928 BMS_Cont_Error_StuckOpen_HV_Pos1 "null";
BA_ "sigSecLevel" SG_ 928 BMS_Cont_Error_StuckOpen_HV_Pos1 "null";
BA_ "sigConfig" SG_ 928 BMS_Cont_Error_Welded_HV_Pos1 "null";
BA_ "sigExplanation" SG_ 928 BMS_Cont_Error_Welded_HV_Pos1 "null";
BA_ "sigSecLevel" SG_ 928 BMS_Cont_Error_Welded_HV_Pos1 "null";
BA_ "sigConfig" SG_ 928 BMS_Cont_Error_Exceed_HV_Pos1 "null";
BA_ "sigExplanation" SG_ 928 BMS_Cont_Error_Exceed_HV_Pos1 "null";
BA_ "sigSecLevel" SG_ 928 BMS_Cont_Error_Exceed_HV_Pos1 "null";
BA_ "sigConfig" SG_ 928 BMS_Cont_Error_DisCh1_HV_Pos1 "null";
BA_ "sigExplanation" SG_ 928 BMS_Cont_Error_DisCh1_HV_Pos1 "null";
BA_ "sigSecLevel" SG_ 928 BMS_Cont_Error_DisCh1_HV_Pos1 "null";
BA_ "sigConfig" SG_ 928 BMS_Cont_Error_DisCh2_HV_Pos1 "null";
BA_ "sigExplanation" SG_ 928 BMS_Cont_Error_DisCh2_HV_Pos1 "null";
BA_ "sigSecLevel" SG_ 928 BMS_Cont_Error_DisCh2_HV_Pos1 "null";
BA_ "sigConfig" SG_ 928 BMS_Cont_Error_DisCh3_HV_Pos1 "null";
BA_ "sigExplanation" SG_ 928 BMS_Cont_Error_DisCh3_HV_Pos1 "null";
BA_ "sigSecLevel" SG_ 928 BMS_Cont_Error_DisCh3_HV_Pos1 "null";
BA_ "sigConfig" SG_ 928 BMS_Cont_Error_DisCh4_HV_Pos1 "null";
BA_ "sigExplanation" SG_ 928 BMS_Cont_Error_DisCh4_HV_Pos1 "null";
BA_ "sigSecLevel" SG_ 928 BMS_Cont_Error_DisCh4_HV_Pos1 "null";
BA_ "sigConfig" SG_ 928 BMS_Cont_Error_Ch1_HV_Pos1 "null";
BA_ "sigExplanation" SG_ 928 BMS_Cont_Error_Ch1_HV_Pos1 "null";
BA_ "sigSecLevel" SG_ 928 BMS_Cont_Error_Ch1_HV_Pos1 "null";
BA_ "sigConfig" SG_ 928 BMS_Cont_Error_Ch2_HV_Pos1 "null";
BA_ "sigExplanation" SG_ 928 BMS_Cont_Error_Ch2_HV_Pos1 "null";
BA_ "sigSecLevel" SG_ 928 BMS_Cont_Error_Ch2_HV_Pos1 "null";
BA_ "sigConfig" SG_ 929 BMS_Cont_Error_StuckOpen_HV_Neg1 "null";
BA_ "sigExplanation" SG_ 929 BMS_Cont_Error_StuckOpen_HV_Neg1 "null";
BA_ "sigSecLevel" SG_ 929 BMS_Cont_Error_StuckOpen_HV_Neg1 "null";
BA_ "sigConfig" SG_ 929 BMS_Cont_Error_Welded_HV_Neg1 "null";
BA_ "sigExplanation" SG_ 929 BMS_Cont_Error_Welded_HV_Neg1 "null";
BA_ "sigSecLevel" SG_ 929 BMS_Cont_Error_Welded_HV_Neg1 "null";
BA_ "sigConfig" SG_ 929 BMS_Cont_Error_Exceed_HV_Neg1 "null";
BA_ "sigExplanation" SG_ 929 BMS_Cont_Error_Exceed_HV_Neg1 "null";
BA_ "sigSecLevel" SG_ 929 BMS_Cont_Error_Exceed_HV_Neg1 "null";
BA_ "sigConfig" SG_ 929 BMS_Cont_Error_DisCh1_HV_Neg1 "null";
BA_ "sigExplanation" SG_ 929 BMS_Cont_Error_DisCh1_HV_Neg1 "null";
BA_ "sigSecLevel" SG_ 929 BMS_Cont_Error_DisCh1_HV_Neg1 "null";
BA_ "sigConfig" SG_ 929 BMS_Cont_Error_DisCh2_HV_Neg1 "null";
BA_ "sigExplanation" SG_ 929 BMS_Cont_Error_DisCh2_HV_Neg1 "null";
BA_ "sigSecLevel" SG_ 929 BMS_Cont_Error_DisCh2_HV_Neg1 "null";
BA_ "sigConfig" SG_ 929 BMS_Cont_Error_DisCh3_HV_Neg1 "null";
BA_ "sigExplanation" SG_ 929 BMS_Cont_Error_DisCh3_HV_Neg1 "null";
BA_ "sigSecLevel" SG_ 929 BMS_Cont_Error_DisCh3_HV_Neg1 "null";
BA_ "sigConfig" SG_ 929 BMS_Cont_Error_DisCh4_HV_Neg1 "null";
BA_ "sigExplanation" SG_ 929 BMS_Cont_Error_DisCh4_HV_Neg1 "null";
BA_ "sigSecLevel" SG_ 929 BMS_Cont_Error_DisCh4_HV_Neg1 "null";
BA_ "sigConfig" SG_ 929 BMS_Cont_Error_Ch1_HV_Neg1 "null";
BA_ "sigExplanation" SG_ 929 BMS_Cont_Error_Ch1_HV_Neg1 "null";
BA_ "sigSecLevel" SG_ 929 BMS_Cont_Error_Ch1_HV_Neg1 "null";
BA_ "sigConfig" SG_ 929 BMS_Cont_Error_Ch2_HV_Neg1 "null";
BA_ "sigExplanation" SG_ 929 BMS_Cont_Error_Ch2_HV_Neg1 "null";
BA_ "sigSecLevel" SG_ 929 BMS_Cont_Error_Ch2_HV_Neg1 "null";
BA_ "sigConfig" SG_ 930 BMS_Cont_Error_StuckOpen_HV_Prec "null";
BA_ "sigExplanation" SG_ 930 BMS_Cont_Error_StuckOpen_HV_Prec "null";
BA_ "sigSecLevel" SG_ 930 BMS_Cont_Error_StuckOpen_HV_Prec "null";
BA_ "SystemSignalLongSymbol" SG_ 930 BMS_Cont_Error_StuckOpen_HV_Prec "BMS_Cont_Error_StuckOpen_HV_Prec1";
BA_ "sigConfig" SG_ 930 BMS_Cont_Error_Welded_HV_Prec1 "null";
BA_ "sigExplanation" SG_ 930 BMS_Cont_Error_Welded_HV_Prec1 "null";
BA_ "sigSecLevel" SG_ 930 BMS_Cont_Error_Welded_HV_Prec1 "null";
BA_ "sigConfig" SG_ 930 BMS_Cont_Error_Exceed_HV_Prec "null";
BA_ "sigExplanation" SG_ 930 BMS_Cont_Error_Exceed_HV_Prec "null";
BA_ "sigSecLevel" SG_ 930 BMS_Cont_Error_Exceed_HV_Prec "null";
BA_ "sigConfig" SG_ 930 BMS_Cont_Error_DisCh1_HV_Prec "null";
BA_ "sigExplanation" SG_ 930 BMS_Cont_Error_DisCh1_HV_Prec "null";
BA_ "sigSecLevel" SG_ 930 BMS_Cont_Error_DisCh1_HV_Prec "null";
BA_ "sigConfig" SG_ 930 BMS_Cont_Error_DisCh2_HV_Prec "null";
BA_ "sigExplanation" SG_ 930 BMS_Cont_Error_DisCh2_HV_Prec "null";
BA_ "sigSecLevel" SG_ 930 BMS_Cont_Error_DisCh2_HV_Prec "null";
BA_ "sigConfig" SG_ 930 BMS_Cont_Error_DisCh3_HV_Prec "null";
BA_ "sigExplanation" SG_ 930 BMS_Cont_Error_DisCh3_HV_Prec "null";
BA_ "sigSecLevel" SG_ 930 BMS_Cont_Error_DisCh3_HV_Prec "null";
BA_ "sigConfig" SG_ 930 BMS_Cont_Error_DisCh4_HV_Prec "null";
BA_ "sigExplanation" SG_ 930 BMS_Cont_Error_DisCh4_HV_Prec "null";
BA_ "sigSecLevel" SG_ 930 BMS_Cont_Error_DisCh4_HV_Prec "null";
BA_ "sigConfig" SG_ 930 BMS_Cont_Error_Ch1_HV_Prec1 "null";
BA_ "sigExplanation" SG_ 930 BMS_Cont_Error_Ch1_HV_Prec1 "null";
BA_ "sigSecLevel" SG_ 930 BMS_Cont_Error_Ch1_HV_Prec1 "null";
BA_ "sigConfig" SG_ 930 BMS_Cont_Error_Ch2_HV_Prec1 "null";
BA_ "sigExplanation" SG_ 930 BMS_Cont_Error_Ch2_HV_Prec1 "null";
BA_ "sigSecLevel" SG_ 930 BMS_Cont_Error_Ch2_HV_Prec1 "null";
BA_ "sigConfig" SG_ 933 BMS_Bat_Coolant_in "null";
BA_ "sigExplanation" SG_ 933 BMS_Bat_Coolant_in "null";
BA_ "sigSecLevel" SG_ 933 BMS_Bat_Coolant_in "null";
BA_ "sigConfig" SG_ 933 BMS_Bat_Coolant_out "null";
BA_ "sigExplanation" SG_ 933 BMS_Bat_Coolant_out "null";
BA_ "sigSecLevel" SG_ 933 BMS_Bat_Coolant_out "null";
BA_ "GenSigStartValue" SG_ 933 BMS_BattInlT_Target 48;
BA_ "sigConfig" SG_ 933 BMS_BattInlT_Target "null";
BA_ "sigExplanation" SG_ 933 BMS_BattInlT_Target "null";
BA_ "sigSecLevel" SG_ 933 BMS_BattInlT_Target "null";
BA_ "GenSigStartValue" SG_ 933 BMS_BattInlT_Min 48;
BA_ "sigConfig" SG_ 933 BMS_BattInlT_Min "null";
BA_ "sigExplanation" SG_ 933 BMS_BattInlT_Min "null";
BA_ "sigSecLevel" SG_ 933 BMS_BattInlT_Min "null";
BA_ "GenSigStartValue" SG_ 933 BMS_BattInlT_Max 48;
BA_ "sigConfig" SG_ 933 BMS_BattInlT_Max "null";
BA_ "sigExplanation" SG_ 933 BMS_BattInlT_Max "null";
BA_ "sigSecLevel" SG_ 933 BMS_BattInlT_Max "null";
BA_ "sigConfig" SG_ 934 BMS_Cont_Error_StuckOpen_HV_PV_N "null";
BA_ "sigExplanation" SG_ 934 BMS_Cont_Error_StuckOpen_HV_PV_N "null";
BA_ "sigSecLevel" SG_ 934 BMS_Cont_Error_StuckOpen_HV_PV_N "null";
BA_ "SystemSignalLongSymbol" SG_ 934 BMS_Cont_Error_StuckOpen_HV_PV_N "BMS_Cont_Error_StuckOpen_HV_PV_Neg1";
BA_ "sigConfig" SG_ 934 BMS_Cont_Error_Welded_HV_PV_Neg1 "null";
BA_ "sigExplanation" SG_ 934 BMS_Cont_Error_Welded_HV_PV_Neg1 "null";
BA_ "sigSecLevel" SG_ 934 BMS_Cont_Error_Welded_HV_PV_Neg1 "null";
BA_ "sigConfig" SG_ 934 BMS_Cont_Error_Exceed_HV_PV_Neg1 "null";
BA_ "sigExplanation" SG_ 934 BMS_Cont_Error_Exceed_HV_PV_Neg1 "null";
BA_ "sigSecLevel" SG_ 934 BMS_Cont_Error_Exceed_HV_PV_Neg1 "null";
BA_ "sigConfig" SG_ 934 BMS_Cont_Error_DisCh1_HV_PV_Neg1 "null";
BA_ "sigExplanation" SG_ 934 BMS_Cont_Error_DisCh1_HV_PV_Neg1 "null";
BA_ "sigSecLevel" SG_ 934 BMS_Cont_Error_DisCh1_HV_PV_Neg1 "null";
BA_ "sigConfig" SG_ 934 BMS_Cont_Error_DisCh2_HV_PV_Neg1 "null";
BA_ "sigExplanation" SG_ 934 BMS_Cont_Error_DisCh2_HV_PV_Neg1 "null";
BA_ "sigSecLevel" SG_ 934 BMS_Cont_Error_DisCh2_HV_PV_Neg1 "null";
BA_ "sigConfig" SG_ 934 BMS_Cont_Error_DisCh3_HV_PV_Neg1 "null";
BA_ "sigExplanation" SG_ 934 BMS_Cont_Error_DisCh3_HV_PV_Neg1 "null";
BA_ "sigSecLevel" SG_ 934 BMS_Cont_Error_DisCh3_HV_PV_Neg1 "null";
BA_ "sigConfig" SG_ 934 BMS_Cont_Error_DisCh4_HV_PV_Neg1 "null";
BA_ "sigExplanation" SG_ 934 BMS_Cont_Error_DisCh4_HV_PV_Neg1 "null";
BA_ "sigSecLevel" SG_ 934 BMS_Cont_Error_DisCh4_HV_PV_Neg1 "null";
BA_ "sigConfig" SG_ 934 BMS_Cont_Error_Ch1_HV_PV_Neg1 "null";
BA_ "sigExplanation" SG_ 934 BMS_Cont_Error_Ch1_HV_PV_Neg1 "null";
BA_ "sigSecLevel" SG_ 934 BMS_Cont_Error_Ch1_HV_PV_Neg1 "null";
BA_ "sigConfig" SG_ 934 BMS_Cont_Error_Ch2_HV_PV_Neg1 "null";
BA_ "sigExplanation" SG_ 934 BMS_Cont_Error_Ch2_HV_PV_Neg1 "null";
BA_ "sigSecLevel" SG_ 934 BMS_Cont_Error_Ch2_HV_PV_Neg1 "null";
BA_ "sigConfig" SG_ 935 BMS_Cont_Error_StuckOpen_HV_PV_P "null";
BA_ "sigExplanation" SG_ 935 BMS_Cont_Error_StuckOpen_HV_PV_P "null";
BA_ "sigSecLevel" SG_ 935 BMS_Cont_Error_StuckOpen_HV_PV_P "null";
BA_ "SystemSignalLongSymbol" SG_ 935 BMS_Cont_Error_StuckOpen_HV_PV_P "BMS_Cont_Error_StuckOpen_HV_PV_Pos1";
BA_ "sigConfig" SG_ 935 BMS_Cont_Error_Welded_HV_PV_Pos1 "null";
BA_ "sigExplanation" SG_ 935 BMS_Cont_Error_Welded_HV_PV_Pos1 "null";
BA_ "sigSecLevel" SG_ 935 BMS_Cont_Error_Welded_HV_PV_Pos1 "null";
BA_ "sigConfig" SG_ 935 BMS_Cont_Error_Exceed_HV_PV_Pos1 "null";
BA_ "sigExplanation" SG_ 935 BMS_Cont_Error_Exceed_HV_PV_Pos1 "null";
BA_ "sigSecLevel" SG_ 935 BMS_Cont_Error_Exceed_HV_PV_Pos1 "null";
BA_ "sigConfig" SG_ 935 BMS_Cont_Error_DisCh1_HV_PV_Pos1 "null";
BA_ "sigExplanation" SG_ 935 BMS_Cont_Error_DisCh1_HV_PV_Pos1 "null";
BA_ "sigSecLevel" SG_ 935 BMS_Cont_Error_DisCh1_HV_PV_Pos1 "null";
BA_ "sigConfig" SG_ 935 BMS_Cont_Error_DisCh2_HV_PV_Pos1 "null";
BA_ "sigExplanation" SG_ 935 BMS_Cont_Error_DisCh2_HV_PV_Pos1 "null";
BA_ "sigSecLevel" SG_ 935 BMS_Cont_Error_DisCh2_HV_PV_Pos1 "null";
BA_ "sigConfig" SG_ 935 BMS_Cont_Error_DisCh3_HV_PV_Pos1 "null";
BA_ "sigExplanation" SG_ 935 BMS_Cont_Error_DisCh3_HV_PV_Pos1 "null";
BA_ "sigSecLevel" SG_ 935 BMS_Cont_Error_DisCh3_HV_PV_Pos1 "null";
BA_ "sigConfig" SG_ 935 BMS_Cont_Error_DisCh4_HV_PV_Pos1 "null";
BA_ "sigExplanation" SG_ 935 BMS_Cont_Error_DisCh4_HV_PV_Pos1 "null";
BA_ "sigSecLevel" SG_ 935 BMS_Cont_Error_DisCh4_HV_PV_Pos1 "null";
BA_ "sigConfig" SG_ 935 BMS_Cont_Error_Ch1_HV_PV_Pos1 "null";
BA_ "sigExplanation" SG_ 935 BMS_Cont_Error_Ch1_HV_PV_Pos1 "null";
BA_ "sigSecLevel" SG_ 935 BMS_Cont_Error_Ch1_HV_PV_Pos1 "null";
BA_ "sigConfig" SG_ 935 BMS_Cont_Error_Ch2_HV_PV_Pos1 "null";
BA_ "sigExplanation" SG_ 935 BMS_Cont_Error_Ch2_HV_PV_Pos1 "null";
BA_ "sigSecLevel" SG_ 935 BMS_Cont_Error_Ch2_HV_PV_Pos1 "null";
BA_ "GenSigSendType" SG_ 944 GW_UDSprohb 2;
BA_ "GenSigSendType" SG_ 1025 VCU_SrcNodeID 7;
BA_ "sigConfig" SG_ 1025 VCU_SrcNodeID "null";
BA_ "sigExplanation" SG_ 1025 VCU_SrcNodeID "null";
BA_ "sigSecLevel" SG_ 1025 VCU_SrcNodeID "QM";
BA_ "GenSigSendType" SG_ 1025 VCU_CtrlBitVector_Bit0_RMR 7;
BA_ "sigConfig" SG_ 1025 VCU_CtrlBitVector_Bit0_RMR "null";
BA_ "sigExplanation" SG_ 1025 VCU_CtrlBitVector_Bit0_RMR "null";
BA_ "sigSecLevel" SG_ 1025 VCU_CtrlBitVector_Bit0_RMR "QM";
BA_ "GenSigSendType" SG_ 1025 VCU_CtrlBitVector_Bit1_Res 7;
BA_ "sigConfig" SG_ 1025 VCU_CtrlBitVector_Bit1_Res "null";
BA_ "sigExplanation" SG_ 1025 VCU_CtrlBitVector_Bit1_Res "null";
BA_ "sigSecLevel" SG_ 1025 VCU_CtrlBitVector_Bit1_Res "QM";
BA_ "GenSigSendType" SG_ 1025 VCU_CtrlBitVector_Bit2_Res 7;
BA_ "sigConfig" SG_ 1025 VCU_CtrlBitVector_Bit2_Res "null";
BA_ "sigExplanation" SG_ 1025 VCU_CtrlBitVector_Bit2_Res "null";
BA_ "sigSecLevel" SG_ 1025 VCU_CtrlBitVector_Bit2_Res "QM";
BA_ "GenSigSendType" SG_ 1025 VCU_CtrlBitVector_Bit3_NMCoord 7;
BA_ "sigConfig" SG_ 1025 VCU_CtrlBitVector_Bit3_NMCoord "null";
BA_ "sigExplanation" SG_ 1025 VCU_CtrlBitVector_Bit3_NMCoord "null";
BA_ "sigSecLevel" SG_ 1025 VCU_CtrlBitVector_Bit3_NMCoord "QM";
BA_ "GenSigSendType" SG_ 1025 VCU_CtrlBitVector_Bit4_ActWake 7;
BA_ "sigConfig" SG_ 1025 VCU_CtrlBitVector_Bit4_ActWake "null";
BA_ "sigExplanation" SG_ 1025 VCU_CtrlBitVector_Bit4_ActWake "null";
BA_ "sigSecLevel" SG_ 1025 VCU_CtrlBitVector_Bit4_ActWake "QM";
BA_ "GenSigSendType" SG_ 1025 VCU_CtrlBitVector_Bit5_Res 7;
BA_ "sigConfig" SG_ 1025 VCU_CtrlBitVector_Bit5_Res "null";
BA_ "sigExplanation" SG_ 1025 VCU_CtrlBitVector_Bit5_Res "null";
BA_ "sigSecLevel" SG_ 1025 VCU_CtrlBitVector_Bit5_Res "QM";
BA_ "GenSigSendType" SG_ 1025 VCU_CtrlBitVector_Bit6_PNI 7;
BA_ "sigConfig" SG_ 1025 VCU_CtrlBitVector_Bit6_PNI "null";
BA_ "sigExplanation" SG_ 1025 VCU_CtrlBitVector_Bit6_PNI "null";
BA_ "sigSecLevel" SG_ 1025 VCU_CtrlBitVector_Bit6_PNI "QM";
BA_ "GenSigSendType" SG_ 1025 VCU_CtrlBitVector_Bit7_Res 7;
BA_ "sigConfig" SG_ 1025 VCU_CtrlBitVector_Bit7_Res "null";
BA_ "sigExplanation" SG_ 1025 VCU_CtrlBitVector_Bit7_Res "null";
BA_ "sigSecLevel" SG_ 1025 VCU_CtrlBitVector_Bit7_Res "QM";
BA_ "GenSigSendType" SG_ 1025 VCU_UsrData0 7;
BA_ "GenSigStartValue" SG_ 1025 VCU_UsrData0 255;
BA_ "sigConfig" SG_ 1025 VCU_UsrData0 "null";
BA_ "sigExplanation" SG_ 1025 VCU_UsrData0 "null";
BA_ "sigSecLevel" SG_ 1025 VCU_UsrData0 "QM";
BA_ "GenSigSendType" SG_ 1025 VCU_UsrData1_Bit0_IGN_WAKEUP 7;
BA_ "sigConfig" SG_ 1025 VCU_UsrData1_Bit0_IGN_WAKEUP "null";
BA_ "sigExplanation" SG_ 1025 VCU_UsrData1_Bit0_IGN_WAKEUP "null";
BA_ "sigSecLevel" SG_ 1025 VCU_UsrData1_Bit0_IGN_WAKEUP "QM";
BA_ "GenSigSendType" SG_ 1025 VCU_UsrData1_Bit1_RESET_WAKEUP 7;
BA_ "sigConfig" SG_ 1025 VCU_UsrData1_Bit1_RESET_WAKEUP "null";
BA_ "sigExplanation" SG_ 1025 VCU_UsrData1_Bit1_RESET_WAKEUP "null";
BA_ "sigSecLevel" SG_ 1025 VCU_UsrData1_Bit1_RESET_WAKEUP "QM";
BA_ "GenSigSendType" SG_ 1025 VCU_UsrData1_Bit2_NETWORK_WAKEUP 7;
BA_ "sigConfig" SG_ 1025 VCU_UsrData1_Bit2_NETWORK_WAKEUP "null";
BA_ "sigExplanation" SG_ 1025 VCU_UsrData1_Bit2_NETWORK_WAKEUP "null";
BA_ "sigSecLevel" SG_ 1025 VCU_UsrData1_Bit2_NETWORK_WAKEUP "QM";
BA_ "GenSigSendType" SG_ 1025 VCU_UsrData1_Bit3_ECUSPEC_WAKEUP 7;
BA_ "sigConfig" SG_ 1025 VCU_UsrData1_Bit3_ECUSPEC_WAKEUP "null";
BA_ "sigExplanation" SG_ 1025 VCU_UsrData1_Bit3_ECUSPEC_WAKEUP "null";
BA_ "sigSecLevel" SG_ 1025 VCU_UsrData1_Bit3_ECUSPEC_WAKEUP "QM";
BA_ "GenSigSendType" SG_ 1025 VCU_UsrData1_Bit4_NETWORK_AWAKE 7;
BA_ "sigConfig" SG_ 1025 VCU_UsrData1_Bit4_NETWORK_AWAKE "null";
BA_ "sigExplanation" SG_ 1025 VCU_UsrData1_Bit4_NETWORK_AWAKE "null";
BA_ "sigSecLevel" SG_ 1025 VCU_UsrData1_Bit4_NETWORK_AWAKE "QM";
BA_ "GenSigSendType" SG_ 1025 VCU_UsrData1_Bit5_IGNITION_AWAKE 7;
BA_ "sigConfig" SG_ 1025 VCU_UsrData1_Bit5_IGNITION_AWAKE "null";
BA_ "sigExplanation" SG_ 1025 VCU_UsrData1_Bit5_IGNITION_AWAKE "null";
BA_ "sigSecLevel" SG_ 1025 VCU_UsrData1_Bit5_IGNITION_AWAKE "QM";
BA_ "GenSigSendType" SG_ 1025 VCU_UsrData1_Bit6_DIAGN_AWAKE 7;
BA_ "sigConfig" SG_ 1025 VCU_UsrData1_Bit6_DIAGN_AWAKE "null";
BA_ "sigExplanation" SG_ 1025 VCU_UsrData1_Bit6_DIAGN_AWAKE "null";
BA_ "sigSecLevel" SG_ 1025 VCU_UsrData1_Bit6_DIAGN_AWAKE "QM";
BA_ "GenSigSendType" SG_ 1025 VCU_UsrData1_Bit7_ECUSPEC_AWAKE 7;
BA_ "sigConfig" SG_ 1025 VCU_UsrData1_Bit7_ECUSPEC_AWAKE "null";
BA_ "sigExplanation" SG_ 1025 VCU_UsrData1_Bit7_ECUSPEC_AWAKE "null";
BA_ "sigSecLevel" SG_ 1025 VCU_UsrData1_Bit7_ECUSPEC_AWAKE "QM";
BA_ "GenSigSendType" SG_ 1025 VCU_UsrData2 7;
BA_ "GenSigStartValue" SG_ 1025 VCU_UsrData2 255;
BA_ "sigConfig" SG_ 1025 VCU_UsrData2 "null";
BA_ "sigExplanation" SG_ 1025 VCU_UsrData2 "null";
BA_ "sigSecLevel" SG_ 1025 VCU_UsrData2 "QM";
BA_ "GenSigSendType" SG_ 1025 VCU_UsrData3 7;
BA_ "GenSigStartValue" SG_ 1025 VCU_UsrData3 255;
BA_ "sigConfig" SG_ 1025 VCU_UsrData3 "null";
BA_ "sigExplanation" SG_ 1025 VCU_UsrData3 "null";
BA_ "sigSecLevel" SG_ 1025 VCU_UsrData3 "QM";
BA_ "GenSigSendType" SG_ 1025 VCU_UsrData4_PN_Info1 7;
BA_ "GenSigStartValue" SG_ 1025 VCU_UsrData4_PN_Info1 255;
BA_ "sigConfig" SG_ 1025 VCU_UsrData4_PN_Info1 "null";
BA_ "sigExplanation" SG_ 1025 VCU_UsrData4_PN_Info1 "null";
BA_ "sigSecLevel" SG_ 1025 VCU_UsrData4_PN_Info1 "QM";
BA_ "GenSigSendType" SG_ 1025 VCU_UsrData5_PN_Info2 7;
BA_ "GenSigStartValue" SG_ 1025 VCU_UsrData5_PN_Info2 255;
BA_ "sigConfig" SG_ 1025 VCU_UsrData5_PN_Info2 "null";
BA_ "sigExplanation" SG_ 1025 VCU_UsrData5_PN_Info2 "null";
BA_ "sigSecLevel" SG_ 1025 VCU_UsrData5_PN_Info2 "QM";
BA_ "GenSigSendType" SG_ 1043 ECC_SrcNodeID 7;
BA_ "sigConfig" SG_ 1043 ECC_SrcNodeID "null";
BA_ "sigExplanation" SG_ 1043 ECC_SrcNodeID "null";
BA_ "sigSecLevel" SG_ 1043 ECC_SrcNodeID "QM";
BA_ "GenSigSendType" SG_ 1043 ECC_CtrlBitVector_Bit0_RMR 7;
BA_ "sigConfig" SG_ 1043 ECC_CtrlBitVector_Bit0_RMR "null";
BA_ "sigExplanation" SG_ 1043 ECC_CtrlBitVector_Bit0_RMR "null";
BA_ "sigSecLevel" SG_ 1043 ECC_CtrlBitVector_Bit0_RMR "QM";
BA_ "GenSigSendType" SG_ 1043 ECC_CtrlBitVector_Bit1_Res 7;
BA_ "sigConfig" SG_ 1043 ECC_CtrlBitVector_Bit1_Res "null";
BA_ "sigExplanation" SG_ 1043 ECC_CtrlBitVector_Bit1_Res "null";
BA_ "sigSecLevel" SG_ 1043 ECC_CtrlBitVector_Bit1_Res "QM";
BA_ "GenSigSendType" SG_ 1043 ECC_CtrlBitVector_Bit2_Res 7;
BA_ "sigConfig" SG_ 1043 ECC_CtrlBitVector_Bit2_Res "null";
BA_ "sigExplanation" SG_ 1043 ECC_CtrlBitVector_Bit2_Res "null";
BA_ "sigSecLevel" SG_ 1043 ECC_CtrlBitVector_Bit2_Res "QM";
BA_ "GenSigSendType" SG_ 1043 ECC_CtrlBitVector_Bit3_NMCoord 7;
BA_ "sigConfig" SG_ 1043 ECC_CtrlBitVector_Bit3_NMCoord "null";
BA_ "sigExplanation" SG_ 1043 ECC_CtrlBitVector_Bit3_NMCoord "null";
BA_ "sigSecLevel" SG_ 1043 ECC_CtrlBitVector_Bit3_NMCoord "QM";
BA_ "GenSigSendType" SG_ 1043 ECC_CtrlBitVector_Bit4_ActWake 7;
BA_ "sigConfig" SG_ 1043 ECC_CtrlBitVector_Bit4_ActWake "null";
BA_ "sigExplanation" SG_ 1043 ECC_CtrlBitVector_Bit4_ActWake "null";
BA_ "sigSecLevel" SG_ 1043 ECC_CtrlBitVector_Bit4_ActWake "QM";
BA_ "GenSigSendType" SG_ 1043 ECC_CtrlBitVector_Bit5_Res 7;
BA_ "sigConfig" SG_ 1043 ECC_CtrlBitVector_Bit5_Res "null";
BA_ "sigExplanation" SG_ 1043 ECC_CtrlBitVector_Bit5_Res "null";
BA_ "sigSecLevel" SG_ 1043 ECC_CtrlBitVector_Bit5_Res "QM";
BA_ "GenSigSendType" SG_ 1043 ECC_CtrlBitVector_Bit6_PNI 7;
BA_ "sigConfig" SG_ 1043 ECC_CtrlBitVector_Bit6_PNI "null";
BA_ "sigExplanation" SG_ 1043 ECC_CtrlBitVector_Bit6_PNI "null";
BA_ "sigSecLevel" SG_ 1043 ECC_CtrlBitVector_Bit6_PNI "QM";
BA_ "GenSigSendType" SG_ 1043 ECC_CtrlBitVector_Bit7_Res 7;
BA_ "sigConfig" SG_ 1043 ECC_CtrlBitVector_Bit7_Res "null";
BA_ "sigExplanation" SG_ 1043 ECC_CtrlBitVector_Bit7_Res "null";
BA_ "sigSecLevel" SG_ 1043 ECC_CtrlBitVector_Bit7_Res "QM";
BA_ "GenSigSendType" SG_ 1043 ECC_UsrData0 7;
BA_ "GenSigStartValue" SG_ 1043 ECC_UsrData0 255;
BA_ "sigConfig" SG_ 1043 ECC_UsrData0 "null";
BA_ "sigExplanation" SG_ 1043 ECC_UsrData0 "null";
BA_ "sigSecLevel" SG_ 1043 ECC_UsrData0 "QM";
BA_ "GenSigSendType" SG_ 1043 ECC_UsrData1_Bit0_IGN_WAKEUP 7;
BA_ "sigConfig" SG_ 1043 ECC_UsrData1_Bit0_IGN_WAKEUP "null";
BA_ "sigExplanation" SG_ 1043 ECC_UsrData1_Bit0_IGN_WAKEUP "null";
BA_ "sigSecLevel" SG_ 1043 ECC_UsrData1_Bit0_IGN_WAKEUP "QM";
BA_ "GenSigSendType" SG_ 1043 ECC_UsrData1_Bit1_RESET_WAKEUP 7;
BA_ "sigConfig" SG_ 1043 ECC_UsrData1_Bit1_RESET_WAKEUP "null";
BA_ "sigExplanation" SG_ 1043 ECC_UsrData1_Bit1_RESET_WAKEUP "null";
BA_ "sigSecLevel" SG_ 1043 ECC_UsrData1_Bit1_RESET_WAKEUP "QM";
BA_ "GenSigSendType" SG_ 1043 ECC_UsrData1_Bit2_NETWORK_WAKEUP 7;
BA_ "sigConfig" SG_ 1043 ECC_UsrData1_Bit2_NETWORK_WAKEUP "null";
BA_ "sigExplanation" SG_ 1043 ECC_UsrData1_Bit2_NETWORK_WAKEUP "null";
BA_ "sigSecLevel" SG_ 1043 ECC_UsrData1_Bit2_NETWORK_WAKEUP "QM";
BA_ "GenSigSendType" SG_ 1043 ECC_UsrData1_Bit3_ECUSPEC_WAKEUP 7;
BA_ "sigConfig" SG_ 1043 ECC_UsrData1_Bit3_ECUSPEC_WAKEUP "null";
BA_ "sigExplanation" SG_ 1043 ECC_UsrData1_Bit3_ECUSPEC_WAKEUP "null";
BA_ "sigSecLevel" SG_ 1043 ECC_UsrData1_Bit3_ECUSPEC_WAKEUP "QM";
BA_ "GenSigSendType" SG_ 1043 ECC_UsrData1_Bit4_NETWORK_AWAKE 7;
BA_ "sigConfig" SG_ 1043 ECC_UsrData1_Bit4_NETWORK_AWAKE "null";
BA_ "sigExplanation" SG_ 1043 ECC_UsrData1_Bit4_NETWORK_AWAKE "null";
BA_ "sigSecLevel" SG_ 1043 ECC_UsrData1_Bit4_NETWORK_AWAKE "QM";
BA_ "GenSigSendType" SG_ 1043 ECC_UsrData1_Bit5_IGNITION_AWAKE 7;
BA_ "sigConfig" SG_ 1043 ECC_UsrData1_Bit5_IGNITION_AWAKE "null";
BA_ "sigExplanation" SG_ 1043 ECC_UsrData1_Bit5_IGNITION_AWAKE "null";
BA_ "sigSecLevel" SG_ 1043 ECC_UsrData1_Bit5_IGNITION_AWAKE "QM";
BA_ "GenSigSendType" SG_ 1043 ECC_UsrData1_Bit6_DIAGN_AWAKE 7;
BA_ "sigConfig" SG_ 1043 ECC_UsrData1_Bit6_DIAGN_AWAKE "null";
BA_ "sigExplanation" SG_ 1043 ECC_UsrData1_Bit6_DIAGN_AWAKE "null";
BA_ "sigSecLevel" SG_ 1043 ECC_UsrData1_Bit6_DIAGN_AWAKE "QM";
BA_ "GenSigSendType" SG_ 1043 ECC_UsrData1_Bit7_ECUSPEC_AWAKE 7;
BA_ "sigConfig" SG_ 1043 ECC_UsrData1_Bit7_ECUSPEC_AWAKE "null";
BA_ "sigExplanation" SG_ 1043 ECC_UsrData1_Bit7_ECUSPEC_AWAKE "null";
BA_ "sigSecLevel" SG_ 1043 ECC_UsrData1_Bit7_ECUSPEC_AWAKE "QM";
BA_ "GenSigSendType" SG_ 1043 ECC_UsrData2 7;
BA_ "GenSigStartValue" SG_ 1043 ECC_UsrData2 255;
BA_ "sigConfig" SG_ 1043 ECC_UsrData2 "null";
BA_ "sigExplanation" SG_ 1043 ECC_UsrData2 "null";
BA_ "sigSecLevel" SG_ 1043 ECC_UsrData2 "QM";
BA_ "GenSigSendType" SG_ 1043 ECC_UsrData3 7;
BA_ "GenSigStartValue" SG_ 1043 ECC_UsrData3 255;
BA_ "sigConfig" SG_ 1043 ECC_UsrData3 "null";
BA_ "sigExplanation" SG_ 1043 ECC_UsrData3 "null";
BA_ "sigSecLevel" SG_ 1043 ECC_UsrData3 "QM";
BA_ "GenSigSendType" SG_ 1043 ECC_UsrData4_PN_Info1 7;
BA_ "GenSigStartValue" SG_ 1043 ECC_UsrData4_PN_Info1 255;
BA_ "sigConfig" SG_ 1043 ECC_UsrData4_PN_Info1 "null";
BA_ "sigExplanation" SG_ 1043 ECC_UsrData4_PN_Info1 "null";
BA_ "sigSecLevel" SG_ 1043 ECC_UsrData4_PN_Info1 "QM";
BA_ "GenSigSendType" SG_ 1043 ECC_UsrData5_PN_Info2 7;
BA_ "GenSigStartValue" SG_ 1043 ECC_UsrData5_PN_Info2 255;
BA_ "sigConfig" SG_ 1043 ECC_UsrData5_PN_Info2 "null";
BA_ "sigExplanation" SG_ 1043 ECC_UsrData5_PN_Info2 "null";
BA_ "sigSecLevel" SG_ 1043 ECC_UsrData5_PN_Info2 "QM";
VAL_ 870 MCU_R_SecuStsChkFlt 0 "Normal" 1 "Abnormal" ;
VAL_ 870 MCU_R_HVActvDchaFlt 0 "Normal" 1 "Abnormal" ;
VAL_ 870 MCU_R_CtrlPanTChkCircFlt 0 "Normal" 1 "Abnormal" ;
VAL_ 870 MCU_R_ComLostFlt_VCU 0 "Normal" 1 "Abnormal" ;
VAL_ 870 MCU_R_E2EFlt 0 "Normal" 1 "Abnormal" ;
VAL_ 870 MCU_R_I2TFlt 0 "Normal" 1 "Abnormal" ;
VAL_ 870 MCU_R_OperModFlt 0 "Normal" 1 "Abnormal" ;
VAL_ 870 MCU_R_CooltOverTFlt 0 "Normal" 1 "Abnormal" ;
VAL_ 870 MCU_R_PhaCrtSampleCircFltU 0 "Normal" 1 "Abnormal" ;
VAL_ 870 MCU_R_PhaCrtSampleCircFltV 0 "Normal" 1 "Abnormal" ;
VAL_ 870 MCU_R_PhaCrtSampleCircFltW 0 "Normal" 1 "Abnormal" ;
VAL_ 870 MCU_R_ThreePhaCrtChkFlt 0 "Normal" 1 "Abnormal" ;
VAL_ 870 MCU_R_DCBusUnderVoltFlt 0 "Normal" 1 "Abnormal" ;
VAL_ 870 MCU_R_DCBusOverVoltFlt 0 "Normal" 1 "Abnormal" ;
VAL_ 870 MCU_R_PosnSnsrChkCircFlt 0 "Normal" 1 "Abnormal" ;
VAL_ 870 MCU_R_DCBusVoltSampleCircFlt 0 "Normal" 1 "Abnormal" ;
VAL_ 870 MCU_R_OverSpdFlt 0 "Normal" 1 "Abnormal" ;
VAL_ 870 MCU_R_IGBTOverTFltU 0 "Normal" 1 "Abnormal" ;
VAL_ 870 MCU_R_IGBTTChkCircFltU 0 "Normal" 1 "Abnormal" ;
VAL_ 870 MCU_R_IGBTTChkCircFltV 0 "Normal" 1 "Abnormal" ;
VAL_ 870 MCU_R_IGBTTChkCircFltW 0 "Normal" 1 "Abnormal" ;
VAL_ 870 MCU_R_OverTFlt 0 "Normal" 1 "Abnormal" ;
VAL_ 870 MCU_R_TChkCircFlt 0 "Normal" 1 "Abnormal" ;
VAL_ 870 MCU_R_CtrlPanOverTFlt 0 "Normal" 1 "Abnormal" ;
VAL_ 870 MCU_R_LVPwrSplyUnderVoltFlt 0 "Normal" 1 "Abnormal" ;
VAL_ 870 MCU_R_LVPwrSplyOverVoltFlt 0 "Normal" 1 "Abnormal" ;
VAL_ 870 MCU_R_FbTqStsChkFlt 0 "Normal" 1 "Abnormal" ;
VAL_ 870 MCU_R_PhaCrtSwOverCrtFltU 0 "Normal" 1 "Abnormal" ;
VAL_ 870 MCU_R_TqCmdOverLimFlt 0 "Normal" 1 "Abnormal" ;
VAL_ 870 MCU_R_PwrSplyModFlt 0 "Normal" 1 "Abnormal" ;
VAL_ 870 MCU_R_IGBTThreePhaTChkFlt 0 "Normal" 1 "Abnormal" ;
VAL_ 870 MCU_R_RotCalFlt 0 "Normal" 1 "Abnormal" ;
VAL_ 870 MCU_R_IntComFlt 0 "Normal" 1 "Abnormal" ;
VAL_ 870 MCU_R_IntTqChkFlt 0 "Normal" 1 "Abnormal" ;
VAL_ 870 MCU_R_IGBTDesatFltTop 0 "Normal" 1 "Abnormal" ;
VAL_ 870 MCU_R_IGBTDesatFltBot 0 "Normal" 1 "Abnormal" ;
VAL_ 870 MCU_R_PhaCrtSwOverCrtFltV 0 "Normal" 1 "Abnormal" ;
VAL_ 870 MCU_R_PhaCrtSwOverCrtFltW 0 "Normal" 1 "Abnormal" ;
VAL_ 870 MCU_R_IGBTOverTFltV 0 "Normal" 1 "Abnormal" ;
VAL_ 870 MCU_R_IGBTOverTFltW 0 "Normal" 1 "Abnormal" ;
VAL_ 880 BMS_PwrBattOverChrgAlrm 0 "No_fault" 1 "Fault" ;
VAL_ 880 BMS_PwrBattUderVoltFlt 0 "No_fault" 1 "Fault" ;
VAL_ 880 BMS_CellUnderVoltFailFlt 0 "No_fault" 1 "Fault" ;
VAL_ 880 BMS_CellUnderVoltFlt 0 "No_fault" 1 "Fault" ;
VAL_ 880 BMS_BattBalActv 0 "Not_balanced" 1 "Balanced_activation" ;
VAL_ 880 BMS_BattPack1OverVoltFlt 0 "No_fault" 1 "Fault" ;
VAL_ 880 BMS_BattPack1UnderVoltFlt 0 "No_fault" 1 "Fault" ;
VAL_ 880 BMS_DCChrgSoktOverTFlt 0 "Normal" 1 "Abnormal" ;
VAL_ 880 BMS_ComLostFlt_BOBC 0 "Normal" 1 "Abnormal" ;
VAL_ 880 BMS_ComLostFlt_CCU 0 "Normal" 1 "Abnormal" ;
VAL_ 880 BMS_ACChrgSoktOverTFlt 0 "Normal" 1 "Abnormal" ;
VAL_ 880 BMS_ACCrtFlt 0 "Normal" 1 "Abnormal" ;
VAL_ 880 BMS_InsulChkFltLvl2ProtFlg 0 "Normal" 1 "Abnormal" ;
VAL_ 880 BMS_PwrBattOverTAlrm 0 "Normal" 1 "Abnormal" ;
VAL_ 880 BMS_PwrBattHLVIntlkFlt 0 "Normal" 1 "Abnormal" ;
VAL_ 880 BMS_PwrBattExtShoCirc 0 "Normal" 1 "Abnormal" ;
VAL_ 880 BMS_PwrBattIntShoCirc 0 "Normal" 1 "Abnormal" ;
VAL_ 880 BMS_PwrBattTUnbal 0 "Normal" 1 "Abnormal" ;
VAL_ 880 BMS_PwrBattTRiseFast 0 "Normal" 1 "Abnormal" ;
VAL_ 880 BMS_PwrBattIntTotVoltChkFlt 0 "Normal" 1 "Abnormal" ;
VAL_ 880 BMS_PwrBattExtTotVoltChkFlt 0 "Normal" 1 "Abnormal" ;
VAL_ 880 BMS_PwrBattNegRlyAdh 0 "Normal" 1 "Abnormal" ;
VAL_ 880 BMS_PwrBattPrecRlyAdh 0 "Normal" 1 "Abnormal" ;
VAL_ 880 BMS_PwrBattPosRlyAdh 0 "Normal" 1 "Abnormal" ;
VAL_ 880 BMS_PwrBattNegRlyBreak 0 "Normal" 1 "Abnormal" ;
VAL_ 880 BMS_PwrBattPrecRlyBreak 0 "Normal" 1 "Abnormal" ;
VAL_ 880 BMS_PwrBattPosRlyBreak 0 "Normal" 1 "Abnormal" ;
VAL_ 880 BMS_PwrBattPrecRBreak 0 "Normal" 1 "Abnormal" ;
VAL_ 880 BMS_PwrBattMSDBreak 0 "Normal" 1 "Abnormal" ;
VAL_ 880 BMS_PwrBattExtTotVoltChkFltV2 0 "Normal" 1 "Abnormal" ;
VAL_ 880 BMS_BCUEEPROMReadWrFlt 0 "Normal" 1 "Abnormal" ;
VAL_ 880 BMS_PwrBattPosRlyDrvChFlt 0 "Normal" 1 "Abnormal" ;
VAL_ 880 BMS_PwrBattPrecRlyDrvChFlt 0 "Normal" 1 "Abnormal" ;
VAL_ 880 BMS_PwrBattInsulChkFlt 0 "Normal" 1 "Abnormal" ;
VAL_ 880 BMS_PwrBattNegRlyDrvChFlt 0 "Normal" 1 "Abnormal" ;
VAL_ 880 BMS_PwrBattCellVoltUnbal 0 "Normal" 1 "Abnormal" ;
VAL_ 880 BMS_EEPROMReadWrFlt 0 "Normal" 1 "Abnormal" ;
VAL_ 880 BMS_PwrBattSysIntComFlt 0 "Normal" 1 "HV_board_or_1_sub-board_lost" 2 "Two_or_more_sub-boards_lost" 3 "Reserved" ;
VAL_ 880 BMS_InsulRLo 0 "Normal" 1 "Abnormal" ;
VAL_ 880 BMS_CopRowLooseFlt 0 "Normal" 1 "Abnormal" ;
VAL_ 880 BMS_SubEEPROMReadWrFlt 0 "Normal" 1 "Abnormal" ;
VAL_ 880 BMS_SubCellVoltCollctnCircFlt 0 "Normal" 1 "Single-sub-board_voltage_acquisition_circuit_failure" 2 "Two-sub-board_voltage_acquisition_circuit_failure" 3 "Reserved" ;
VAL_ 880 BMS_SubModleVoltCollctnCircFlt 0 "Normal" 1 "Abnormal" ;
VAL_ 880 BMS_SubTCollctnCircFlt 0 "Normal" 1 "Single-channel_acquisition_circuit_failure" 2 "Multiple-adjacent-channel_acquisition_circuit_failure_(¡Ý2)" 3 "Reserved" ;
VAL_ 880 BMS_SubActvBalChFlt 0 "Normal" 1 "Abnormal" ;
VAL_ 880 BMS_SubPasBalChFlt 0 "Normal" 1 "Abnormal" ;
VAL_ 880 BMS_SubOperModRespFlt 0 "Normal" 1 "Abnormal" ;
VAL_ 880 BMS_BattCellVoltUnbalAlrm 0 "Normal" 1 "Early_alarm" ;
VAL_ 880 BMS_ComLostFlt_ECC 0 "Normal" 1 "Abnormal" ;
VAL_ 880 BMS_SubComLostFlt_VBUBMS 0 "Normal" 1 "Abnormal" ;
VAL_ 880 BMS_PrecFailFlt 0 "Normal" 1 "Abnormal" ;
VAL_ 880 BMS_PwrBattCellOverVolt 0 "Normal" 1 "Abnormal" ;
VAL_ 880 BMS_TotVoltOver 0 "Normal" 1 "Abnormal" ;
VAL_ 880 BMS_PwrBattIntTotVoltChkFltV1 0 "Normal" 1 "Abnormal" ;
VAL_ 880 BMS_TotCrtChkFlt 0 "Normal" 1 "Abnormal" ;
VAL_ 880 BMS_ComLostFlt_VCU 0 "Normal" 1 "Abnormal" ;
VAL_ 880 BMS_BattReDrvHLVIntlkFlt 0 "Normal" 1 "Abnormal" ;
VAL_ 880 BMS_ComOverTiFlt_ECC 0 "Normal" 1 "Abnormal" ;
VAL_ 880 BMS_LVPwrSplyFlt 0 "Normal" 1 "Abnormal" ;
VAL_ 880 BMS_ComOverTiFlt_BOBC 0 "Normal" 1 "Abnormal" ;
VAL_ 881 WTC_B_PCBT 255 "Invalid" ;
VAL_ 881 WTC_B_Crt 65535 "Invalid" ;
VAL_ 881 WTC_B_CrtSts 0 "Standby" 1 "Power_working" 2 "Fault" 3 "Gear_working" ;
VAL_ 881 WTC_B_HVIntlkFlt 0 "Normal" 1 "Abnormal" ;
VAL_ 881 WTC_B_ComLost_ECC 0 "Normal" 1 "Abnormal" ;
VAL_ 881 WTC_B_OverCrtFlt 0 "Normal" 1 "Abnormal" ;
VAL_ 881 WTC_B_HVUnderVoltFlt 0 "Normal" 1 "Abnormal" ;
VAL_ 881 WTC_B_HVOverVoltFlt 0 "Normal" 1 "Abnormal" ;
VAL_ 881 WTC_B_ChkBattOverVoltFlt 0 "Normal" 1 "Abnormal" ;
VAL_ 881 WTC_B_ChkBattUnderVoltFlt 0 "Normal" 1 "Abnormal" ;
VAL_ 881 WTC_B_InlTSnsrFlt 0 "Normal" 1 "Abnormal" ;
VAL_ 881 WTC_B_OutlTSnsrFlt 0 "Normal" 1 "Abnormal" ;
VAL_ 881 WTC_B_InlOverTFlt 0 "Normal" 1 "Abnormal" ;
VAL_ 881 WTC_B_OutlOverTFlt 0 "Normal" 1 "Abnormal" ;
VAL_ 881 WTC_B_PCBOverTFlt 0 "Normal" 1 "Abnormal" ;
VAL_ 881 WTC_B_PCBTSnsrFlt 0 "Normal" 1 "Abnormal" ;
VAL_ 881 WTC_B_PwrOutpFlt 0 "Normal" 1 "Abnormal" ;
VAL_ 882 BMS_OTARdy_Fb 0 "Initial" 1 "Ready" 2 "Not_Ready" 3 "Invalid" ;
VAL_ 882 BMS_CellMinT 255 "Invalid" ;
VAL_ 882 BMS_CellMaxT 255 "Invalid" ;
VAL_ 882 BMS_BattAvrgT 255 "Invalid" ;
VAL_ 882 BMS_PwrBattHeatgMngDmd 0 "BMS_initialisation" 1 "Heating_demand" 2 "Cooling_demand" 3 "cycling" ;
VAL_ 882 BMS_ECCSysAllwDwnPwrCmd 0 "Power_reduction_not_allowed" 1 "Power_reduction_allowed" ;
VAL_ 882 BMS_BattInlTDmd 255 "Invalid" ;
VAL_ 883 ECC_CrtSts 0 "Load_initialization" 1 "Low-voltage_state" 2 "Local_high_voltage_state" 3 "Local_charge_state" 4 "Remote_working_state" 5 "High_voltage_discharge_state" 6 "Delay_state" 7 "Reserved" 8 "Reserved" 9 "Reserved" 10 "Reserved" 11 "Reserved" 12 "Reserved" 13 "Reserved" 14 "Reserved" 15 "Reserved" ;
VAL_ 883 ECC_IninSts 0 "Incomplete_initialization" 1 "initialization_completed" ;
VAL_ 883 ECC_PwrSysHeatMngtSts 0 "No_action" 1 "Self_circulation_state" 2 "Forced_cooling" 3 "Reserved" ;
VAL_ 883 ECC_ACSts 0 "Off_state" 1 "ON_state" ;
VAL_ 883 ECC_AirClnSts 0 "Not_ON" 1 "On" ;
VAL_ 883 ECC_WindSpdSts 0 "Windless_gear" 1 "First_gear_of_wind_speed" 2 "Wind_speed_second_gear" 3 "third_gear_of_wind_speed" 4 "wind_speed_fourth_gear" 5 "Wind_speed_fifth_gear" 6 "Wind_speed_six" 7 "Wind_speed_seven_gear" 8 "Reserved" 9 "Reserved" 10 "Reserved" 11 "Reserved" 12 "Reserved" 13 "Reserved" 14 "Reserved" 15 "Reserved" ;
VAL_ 883 ECC_BackRowAirOutlModSts 0 "Rear_face_blowing" 1 "Face_blowing_foot_blowing_of_rear_row" 2 "Foot_blowing_of_rear_row" 3 "Back_row_cutoff" 4 "Reserved" 5 "Reserved" 6 "Reserved" 7 "Reserved" ;
VAL_ 883 ECC_DrvrTSetSts 0 "Inactive" 1 "Low" 2 "Low" 3 "Low" 4 "Low" 5 "Low" 6 "Low" 7 "Low" 8 "Low" 9 "Low" 10 "Low" 11 "Low" 12 "Low" 13 "Low" 14 "Low" 15 "Low" 16 "Low" 17 "Low" 18 "Low" 19 "Low" 20 "Low" 21 "Low" 22 "Low" 23 "Low" 24 "Low" 25 "Low" 26 "Low" 27 "Low" 28 "Low" 29 "Low" 30 "Low" 31 "Low" 32 "Low" 33 "Low" 34 "Low" 35 "Low" 36 "18¡æ" 37 "18.5¡æ" 38 "19¡æ" 39 "19.5¡æ" 40 "20¡æ" 41 "20.5¡æ" 42 "21¡æ" 43 "21.5¡æ" 44 "22¡æ" 45 "22.5¡æ" 46 "23¡æ" 47 "23.5¡æ" 48 "24¡æ" 49 "24.5¡æ" 50 "25¡æ" 51 "25.5¡æ" 52 "26¡æ" 53 "26.5¡æ" 54 "27¡æ" 55 "27.5¡æ" 56 "28¡æ" 57 "28.5¡æ" 58 "29¡æ" 59 "29.5¡æ" 60 "30¡æ" 61 "30.5¡æ" 62 "31¡æ" 63 "31.5¡æ" 64 "32¡æ" 65 "High" 66 "High" 67 "High" 68 "High" 69 "High" 70 "High" 71 "High" 72 "High" 73 "High" 74 "High" 75 "High" 76 "High" 77 "High" 78 "High" 79 "High" 80 "High" 81 "High" 82 "High" 83 "High" 84 "High" 85 "High" 86 "High" 87 "High" 88 "High" 89 "High" 90 "High" 91 "High" 92 "High" 93 "High" 94 "High" 95 "High" 96 "High" 97 "High" 98 "High" 99 "High" 100 "High" 101 "High" 102 "High" 103 "High" 104 "High" 105 "High" 106 "High" 107 "High" 108 "High" 109 "High" 110 "High" 111 "High" 112 "High" 113 "High" 114 "High" 115 "High" 116 "High" 117 "High" 118 "High" 119 "High" 120 "High" 121 "High" 122 "High" 123 "High" 124 "High" 125 "High" 126 "High" 127 "High" 128 "High" 129 "High" 130 "High" 131 "High" 132 "High" 133 "High" 134 "High" 135 "High" 136 "High" 137 "High" 138 "High" 139 "High" 140 "High" 141 "High" 142 "High" 143 "High" 144 "High" 145 "High" 146 "High" 147 "High" 148 "High" 149 "High" 150 "High" 151 "High" 152 "High" 153 "High" 154 "High" 155 "High" 156 "High" 157 "High" 158 "High" 159 "High" 160 "High" 161 "High" 162 "High" 163 "High" 164 "High" 165 "High" 166 "High" 167 "High" 168 "High" 169 "High" 170 "High" 171 "High" 172 "High" 173 "High" 174 "High" 175 "High" 176 "High" 177 "High" 178 "High" 179 "High" 180 "High" 181 "High" 182 "High" 183 "High" 184 "High" 185 "High" 186 "High" 187 "High" 188 "High" 189 "High" 190 "High" 191 "High" 192 "High" 193 "High" 194 "High" 195 "High" 196 "High" 197 "High" 198 "High" 199 "High" 200 "High" 201 "High" 202 "High" 203 "High" 204 "High" 205 "High" 206 "High" 207 "High" 208 "High" 209 "High" 210 "High" 211 "High" 212 "High" 213 "High" 214 "High" 215 "High" 216 "High" 217 "High" 218 "High" 219 "High" 220 "High" 221 "High" 222 "High" 223 "High" 224 "High" 225 "High" 226 "High" 227 "High" 228 "High" 229 "High" 230 "High" 231 "High" 232 "High" 233 "High" 234 "High" 235 "High" 236 "High" 237 "High" 238 "High" 239 "High" 240 "High" 241 "High" 242 "High" 243 "High" 244 "High" 245 "High" 246 "High" 247 "High" 248 "High" 249 "High" 250 "High" 251 "High" 252 "High" 253 "High" 254 "High" 255 "Invalid" ;
VAL_ 883 ECC_PassTSetSts 0 "Inactive" 1 "Low" 2 "Low" 3 "Low" 4 "Low" 5 "Low" 6 "Low" 7 "Low" 8 "Low" 9 "Low" 10 "Low" 11 "Low" 12 "Low" 13 "Low" 14 "Low" 15 "Low" 16 "Low" 17 "Low" 18 "Low" 19 "Low" 20 "Low" 21 "Low" 22 "Low" 23 "Low" 24 "Low" 25 "Low" 26 "Low" 27 "Low" 28 "Low" 29 "Low" 30 "Low" 31 "Low" 32 "Low" 33 "Low" 34 "Low" 35 "Low" 36 "18¡æ" 37 "18.5¡æ" 38 "19¡æ" 39 "19.5¡æ" 40 "20¡æ" 41 "20.5¡æ" 42 "21¡æ" 43 "21.5¡æ" 44 "22¡æ" 45 "22.5¡æ" 46 "23¡æ" 47 "23.5¡æ" 48 "24¡æ" 49 "24.5¡æ" 50 "25¡æ" 51 "25.5¡æ" 52 "26¡æ" 53 "26.5¡æ" 54 "27¡æ" 55 "27.5¡æ" 56 "28¡æ" 57 "28.5¡æ" 58 "29¡æ" 59 "29.5¡æ" 60 "30¡æ" 61 "30.5¡æ" 62 "31¡æ" 63 "31.5¡æ" 64 "32¡æ" 65 "High" 66 "High" 67 "High" 68 "High" 69 "High" 70 "High" 71 "High" 72 "High" 73 "High" 74 "High" 75 "High" 76 "High" 77 "High" 78 "High" 79 "High" 80 "High" 81 "High" 82 "High" 83 "High" 84 "High" 85 "High" 86 "High" 87 "High" 88 "High" 89 "High" 90 "High" 91 "High" 92 "High" 93 "High" 94 "High" 95 "High" 96 "High" 97 "High" 98 "High" 99 "High" 100 "High" 101 "High" 102 "High" 103 "High" 104 "High" 105 "High" 106 "High" 107 "High" 108 "High" 109 "High" 110 "High" 111 "High" 112 "High" 113 "High" 114 "High" 115 "High" 116 "High" 117 "High" 118 "High" 119 "High" 120 "High" 121 "High" 122 "High" 123 "High" 124 "High" 125 "High" 126 "High" 127 "High" 128 "High" 129 "High" 130 "High" 131 "High" 132 "High" 133 "High" 134 "High" 135 "High" 136 "High" 137 "High" 138 "High" 139 "High" 140 "High" 141 "High" 142 "High" 143 "High" 144 "High" 145 "High" 146 "High" 147 "High" 148 "High" 149 "High" 150 "High" 151 "High" 152 "High" 153 "High" 154 "High" 155 "High" 156 "High" 157 "High" 158 "High" 159 "High" 160 "High" 161 "High" 162 "High" 163 "High" 164 "High" 165 "High" 166 "High" 167 "High" 168 "High" 169 "High" 170 "High" 171 "High" 172 "High" 173 "High" 174 "High" 175 "High" 176 "High" 177 "High" 178 "High" 179 "High" 180 "High" 181 "High" 182 "High" 183 "High" 184 "High" 185 "High" 186 "High" 187 "High" 188 "High" 189 "High" 190 "High" 191 "High" 192 "High" 193 "High" 194 "High" 195 "High" 196 "High" 197 "High" 198 "High" 199 "High" 200 "High" 201 "High" 202 "High" 203 "High" 204 "High" 205 "High" 206 "High" 207 "High" 208 "High" 209 "High" 210 "High" 211 "High" 212 "High" 213 "High" 214 "High" 215 "High" 216 "High" 217 "High" 218 "High" 219 "High" 220 "High" 221 "High" 222 "High" 223 "High" 224 "High" 225 "High" 226 "High" 227 "High" 228 "High" 229 "High" 230 "High" 231 "High" 232 "High" 233 "High" 234 "High" 235 "High" 236 "High" 237 "High" 238 "High" 239 "High" 240 "High" 241 "High" 242 "High" 243 "High" 244 "High" 245 "High" 246 "High" 247 "High" 248 "High" 249 "High" 250 "High" 251 "High" 252 "High" 253 "High" 254 "High" 255 "Invalid" ;
VAL_ 883 ECC_HeatSts 0 "Off_state" 1 "ON_state" ;
VAL_ 883 ECC_AUTOSts 0 "Off" 1 "On" ;
VAL_ 883 ECC_SYNCSts 0 "Off" 1 "On" ;
VAL_ 883 ECC_InfoSysWrmColdDisp 0 "No_action" 1 "Natural_wind" 2 "Cold_air" 3 "Hot_air" ;
VAL_ 883 ECC_CircSts 0 "Inner_circulation_state" 1 "outer_circulation_state" ;
VAL_ 883 ECC_ParticleConcVld 0 "Initializing" 1 "Valid" 2 "Invalid" 3 "Reserved" ;
VAL_ 883 ECC_OutdT 255 "Invalid" ;
VAL_ 883 ECC_OutdTVld 0 "Initializing" 1 "Valid" 2 "Invalid" 3 "Reserved" ;
VAL_ 883 ECC_MaxFrntDefrst 0 "Not_opened" 1 "Open" ;
VAL_ 883 ECC_HeatMngtSysFlt 0 "Normal" 1 "Fault" ;
VAL_ 883 ECC_HeatMngtFctLim 0 "Functional" 1 "function_limit" ;
VAL_ 883 ECC_DrvrAirOutlMod 0 "Reserved" 1 "driver_face_blowing_mode" 2 "driver_face_blowing/foot_blowing_mode" 3 "Driver_foot_blowing_mode" 4 "driver_foot/window_mode" 5 "Window_blowing_mode" 6 "Reserved" 7 "Reserved" ;
VAL_ 883 ECC_PassAirOutlMod 0 "Reserved" 1 "front_passenger_face_blowing_mode" 2 "front_passenger_face_blowing/foot_blowing_mode" 3 "Front_passenger_foot_mode" 4 "Front_passenger_foot/window_mode" 5 "Reserved" 6 "Reserved" 7 "Reserved" ;
VAL_ 883 ECC_RemSts 0 "Standby" 1 "Working" 2 "Fault" 3 "Reserved" ;
VAL_ 883 ECC_OTAInhbRdy 0 "Initial" 1 "Inhibit" 2 "Not_Inhibit" 3 "Invalid" ;
VAL_ 884 WTC_H_PCBT 255 "Invalid" ;
VAL_ 884 WTC_H_Crt 65535 "Invalid" ;
VAL_ 884 WTC_H_CrtSts 0 "Standby" 1 "Power_working" 2 "Fault" 3 "Gear_working" ;
VAL_ 884 WTC_H_HVIntlkFlt 0 "Normal" 1 "Abnormal" ;
VAL_ 884 WTC_H_ComLost_ECC 0 "Normal" 1 "Abnormal" ;
VAL_ 884 WTC_H_OverCrtFlt 0 "Normal" 1 "Abnormal" ;
VAL_ 884 WTC_H_HVUnderVoltFlt 0 "Normal" 1 "Abnormal" ;
VAL_ 884 WTC_H_HVOverVoltFlt 0 "Normal" 1 "Abnormal" ;
VAL_ 884 WTC_H_ChkBattOverVoltFlt 0 "Normal" 1 "Abnormal" ;
VAL_ 884 WTC_H_ChkBattUnderVoltFlt 0 "Normal" 1 "Abnormal" ;
VAL_ 884 WTC_H_InlTSnsrFlt 0 "Normal" 1 "Abnormal" ;
VAL_ 884 WTC_H_OutlTSnsrFlt 0 "Normal" 1 "Abnormal" ;
VAL_ 884 WTC_H_InlOverTFlt 0 "Normal" 1 "Abnormal" ;
VAL_ 884 WTC_H_OutlOverTFlt 0 "Normal" 1 "Abnormal" ;
VAL_ 884 WTC_H_PCBOverTFlt 0 "Normal" 1 "Abnormal" ;
VAL_ 884 WTC_H_PCBTSnsrFlt 0 "Normal" 1 "Abnormal" ;
VAL_ 884 WTC_H_PwrOutpFlt 0 "Normal" 1 "Abnormal" ;
VAL_ 886 WTC_B_InlT 255 "Invalid" ;
VAL_ 886 WTC_B_OutlT 255 "Invalid" ;
VAL_ 886 WTC_B_CrtT 255 "Invalid" ;
VAL_ 886 WTC_B_IninSts 0 "initializing" 1 "initialized" ;
VAL_ 886 WTC_B_HVPwrSplySts 0 "No_power_supply" 1 "Power_supply" ;
VAL_ 886 WTC_B_ActGear 0 "Gear_0" 1 "Gear_1" 2 "Gear_2" 3 "Gear_3" 4 "Gear_4" 5 "Gear_5" 6 "Gear_6" 7 "Reserved" 8 "Reserved" 9 "Reserved" 10 "Reserved" 11 "Reserved" 12 "Reserved" 13 "Reserved" 14 "Reserved" 15 "Reserved" ;
VAL_ 886 WTC_B_Mod 0 "Gear_working_mode" 1 "Power_working_mode" ;
VAL_ 888 ECC_LeOutlUpDwnMotActvSts 0 "No_Action" 1 "Level_1_upwards_by_100%" 2 "Level_2_upwards_80%" 3 "Level_3_upwards_60%" 4 "Level_4_upwards_40%" 5 "Level_5_up_20%" 6 "Level_6_positive_direction" 7 "Level_7_adjustment_downward_20%" 8 "Level_8_adjustment_downward_40%" 9 "Level_9_adjustment_downward_60%" 10 "Level_10_Adjustment_Downward_by_80%" 11 "Level_11_Adjust_downward_100%" 12 "Reserved" 13 "Reserved" 14 "Reserved" 15 "Invalid" ;
VAL_ 888 ECC_LeOutlLeRiMotActvSts 0 "No_Action" 1 "Level_1_to_the_left_100%" 2 "Level_2_to_the_left_80%" 3 "Level_3_left_adjustment_60%" 4 "Level_4_adjustment_to_the_left_40%" 5 "Level_5_to_the_left_20%" 6 "Level_6_positive_direction" 7 "Level_7_adjusted_to_the_right_by_20%" 8 "Level_8_adjustment_to_the_right_40%" 9 "Level_9_adjustment_to_the_right_60%" 10 "Level_10_adjust_80%_to_the_right" 11 "Level_11_adjusting_100%_to_the_right" 12 "closed" 13 "Reserved" 14 "Reserved" 15 "Invalid" ;
VAL_ 888 ECC_LeOutlDamprMotActvSts 0 "No_Action" 1 "Level_1_Throttle_opening_0%" 2 "Level_2_throttle_opening_10%" 3 "Level_3_Throttle_Opening_20%" 4 "Level_4_Throttle_Opening_30%" 5 "Level_5_Throttle_Opening_40%" 6 "Level_6_throttle_opening_50%" 7 "Level_7_throttle_opening_60%" 8 "Level_8_Throttle_70%" 9 "Level_9_throttle_opening_80%" 10 "Level_10_throttle_openning_90%" 11 "Level_11_throttle_opening_100%" 12 "Reserved" 13 "Reserved" 14 "Reserved" 15 "Invalid" ;
VAL_ 888 ECC_MidLeOutlUpDwnMotActvSts 0 "No_Action" 1 "Level_1_upwards_by_100%" 2 "Level_2_upwards_80%" 3 "Level_3_upwards_60%" 4 "Level_4_upwards_40%" 5 "Level_5_up_20%" 6 "Level_6_positive_direction" 7 "Level_7_adjustment_downward_20%" 8 "Level_8_adjustment_downward_40%" 9 "Level_9_adjustment_downward_60%" 10 "Level_10_Adjustment_Downward_by_80%" 11 "Level_11_Adjust_downward_100%" 12 "Reserved" 13 "Reserved" 14 "Reserved" 15 "Invalid" ;
VAL_ 888 ECC_MidLeOutlLeRiMotActvSts 0 "No_Action" 1 "Level_1_to_the_left_100%" 2 "Level_2_to_the_left_80%" 3 "Level_3_left_adjustment_60%" 4 "Level_4_adjustment_to_the_left_40%" 5 "Level_5_to_the_left_20%" 6 "Level_6_positive_direction" 7 "Level_7_adjusted_to_the_right_by_20%" 8 "Level_8_adjustment_to_the_right_40%" 9 "Level_9_adjustment_to_the_right_60%" 10 "Level_10_adjust_80%_to_the_right" 11 "Level_11_adjusting_100%_to_the_right" 12 "closed" 13 "Reserved" 14 "Reserved" 15 "Invalid" ;
VAL_ 888 ECC_MidLeOutlDamprMotActvSts 0 "No_Action" 1 "Level_1_Throttle_opening_0%" 2 "Level_2_throttle_opening_10%" 3 "Level_3_Throttle_Opening_20%" 4 "Level_4_Throttle_Opening_30%" 5 "Level_5_Throttle_Opening_40%" 6 "Level_6_throttle_opening_50%" 7 "Level_7_throttle_opening_60%" 8 "Level_8_Throttle_70%" 9 "Level_9_throttle_opening_80%" 10 "Level_10_throttle_openning_90%" 11 "Level_11_throttle_opening_100%" 12 "Reserved" 13 "Reserved" 14 "Reserved" 15 "Invalid" ;
VAL_ 888 ECC_MidRiOutlUpDwnMotActvSts 0 "No_Action" 1 "Level_1_upwards_by_100%" 2 "Level_2_upwards_80%" 3 "Level_3_upwards_60%" 4 "Level_4_upwards_40%" 5 "Level_5_up_20%" 6 "Level_6_positive_direction" 7 "Level_7_adjustment_downward_20%" 8 "Level_8_adjustment_downward_40%" 9 "Level_9_adjustment_downward_60%" 10 "Level_10_Adjustment_Downward_by_80%" 11 "Level_11_Adjust_downward_100%" 12 "Reserved" 13 "Reserved" 14 "Reserved" 15 "Invalid" ;
VAL_ 888 ECC_MidRiOutlLeRiMotActvSts 0 "No_Action" 1 "Level_1_to_the_left_100%" 2 "Level_2_to_the_left_80%" 3 "Level_3_left_adjustment_60%" 4 "Level_4_adjustment_to_the_left_40%" 5 "Level_5_to_the_left_20%" 6 "Level_6_positive_direction" 7 "Level_7_adjusted_to_the_right_by_20%" 8 "Level_8_adjustment_to_the_right_40%" 9 "Level_9_adjustment_to_the_right_60%" 10 "Level_10_adjust_80%_to_the_right" 11 "Level_11_adjusting_100%_to_the_right" 12 "closed" 13 "Reserved" 14 "Reserved" 15 "Invalid" ;
VAL_ 888 ECC_MidRiOutlDamprMotActvSts 0 "No_Action" 1 "Level_1_Throttle_opening_0%" 2 "Level_2_throttle_opening_10%" 3 "Level_3_Throttle_Opening_20%" 4 "Level_4_Throttle_Opening_30%" 5 "Level_5_Throttle_Opening_40%" 6 "Level_6_throttle_opening_50%" 7 "Level_7_throttle_opening_60%" 8 "Level_8_Throttle_70%" 9 "Level_9_throttle_opening_80%" 10 "Level_10_throttle_openning_90%" 11 "Level_11_throttle_opening_100%" 12 "Reserved" 13 "Reserved" 14 "Reserved" 15 "Invalid" ;
VAL_ 888 ECC_RiOutlUpDwnMotActvSts 0 "No_Action" 1 "Level_1_upwards_by_100%" 2 "Level_2_upwards_80%" 3 "Level_3_upwards_60%" 4 "Level_4_upwards_40%" 5 "Level_5_up_20%" 6 "Level_6_positive_direction" 7 "Level_7_adjustment_downward_20%" 8 "Level_8_adjustment_downward_40%" 9 "Level_9_adjustment_downward_60%" 10 "Level_10_Adjustment_Downward_by_80%" 11 "Level_11_Adjust_downward_100%" 12 "Reserved" 13 "Reserved" 14 "Reserved" 15 "Invalid" ;
VAL_ 888 ECC_RiOutlLeRiMotActvSts 0 "No_Action" 1 "Level_1_to_the_left_100%" 2 "Level_2_to_the_left_80%" 3 "Level_3_left_adjustment_60%" 4 "Level_4_adjustment_to_the_left_40%" 5 "Level_5_to_the_left_20%" 6 "Level_6_positive_direction" 7 "Level_7_adjusted_to_the_right_by_20%" 8 "Level_8_adjustment_to_the_right_40%" 9 "Level_9_adjustment_to_the_right_60%" 10 "Level_10_adjust_80%_to_the_right" 11 "Level_11_adjusting_100%_to_the_right" 12 "closed" 13 "Reserved" 14 "Reserved" 15 "Invalid" ;
VAL_ 888 ECC_RiOutlDamprMotActvSts 0 "No_Action" 1 "Level_1_Throttle_opening_0%" 2 "Level_2_throttle_opening_10%" 3 "Level_3_Throttle_Opening_20%" 4 "Level_4_Throttle_Opening_30%" 5 "Level_5_Throttle_Opening_40%" 6 "Level_6_throttle_opening_50%" 7 "Level_7_throttle_opening_60%" 8 "Level_8_Throttle_70%" 9 "Level_9_throttle_opening_80%" 10 "Level_10_throttle_openning_90%" 11 "Level_11_throttle_opening_100%" 12 "Reserved" 13 "Reserved" 14 "Reserved" 15 "Invalid" ;
VAL_ 889 WTC_H_InpT 255 "Invalid" ;
VAL_ 889 WTC_H_OutpT 255 "Invalid" ;
VAL_ 889 WTC_H_CrtT 255 "Invalid" ;
VAL_ 889 WTC_H_IninSts 0 "initializing" 1 "initialized" ;
VAL_ 889 WTC_H_HVPwrSplySts 0 "No_power_supply" 1 "Power_supply" ;
VAL_ 889 WTC_H_ActGear 0 "Gear_0" 1 "Gear_1" 2 "Gear_2" 3 "Gear_3" 4 "Gear_4" 5 "Gear_5" 6 "Gear_6" 7 "Reserved" 8 "Reserved" 9 "Reserved" 10 "Reserved" 11 "Reserved" 12 "Reserved" 13 "Reserved" 14 "Reserved" 15 "Reserved" ;
VAL_ 889 WTC_H_Mod 0 "Gear_working_mode" 1 "Power_working_mode" ;
VAL_ 890 ICC_LeOutlUpDwnMotActvCmd 0 "No_Action" 1 "Level_1_upwards_by_100%" 2 "Level_2_upwards_80%" 3 "Level_3_upwards_60%" 4 "Level_4_upwards_40%" 5 "Level_5_up_20%" 6 "Level_6_positive_direction" 7 "Level_7_adjustment_downward_20%" 8 "Level_8_adjustment_downward_40%" 9 "Level_9_adjustment_downward_60%" 10 "Level_10_Adjustment_Downward_by_80%" 11 "Level_11_Adjust_downward_100%" 12 "Reserved" 13 "Reserved" 14 "Reserved" 15 "Invalid" ;
VAL_ 890 ICC_LeOutlLeRiMotActvCmd 0 "No_Action" 1 "Level_1_to_the_left_100%" 2 "Level_2_to_the_left_80%" 3 "Level_3_left_adjustment_60%" 4 "Level_4_adjustment_to_the_left_40%" 5 "Level_5_to_the_left_20%" 6 "Level_6_positive_direction" 7 "Level_7_adjusted_to_the_right_by_20%" 8 "Level_8_adjustment_to_the_right_40%" 9 "Level_9_adjustment_to_the_right_60%" 10 "Level_10_adjust_80%_to_the_right" 11 "Level_11_adjusting_100%_to_the_right" 12 "Closed" 13 "Reserved" 14 "Reserved" 15 "Invalid" ;
VAL_ 890 ICC_LeOutlDamprMotActvCmd 0 "No_Action" 1 "Level_1_Throttle_opening_0%" 2 "Level_2_throttle_opening_10%" 3 "Level_3_Throttle_Opening_20%" 4 "Level_4_Throttle_Opening_30%" 5 "Level_5_Throttle_Opening_40%" 6 "Level_6_throttle_opening_50%" 7 "Level_7_throttle_opening_60%" 8 "Level_8_Throttle_70%" 9 "Level_9_throttle_opening_80%" 10 "Level_10_throttle_openning_90%" 11 "Level_11_throttle_opening_100%" 12 "Reserved" 13 "Reserved" 14 "Reserved" 15 "Invalid" ;
VAL_ 890 ICC_MidLeOutlUpDwnMotActvCmd 0 "No_Action" 1 "Level_1_upwards_by_100%" 2 "Level_2_upwards_80%" 3 "Level_3_upwards_60%" 4 "Level_4_upwards_40%" 5 "Level_5_up_20%" 6 "Level_6_positive_direction" 7 "Level_7_adjustment_downward_20%" 8 "Level_8_adjustment_downward_40%" 9 "Level_9_adjustment_downward_60%" 10 "Level_10_Adjustment_Downward_by_80%" 11 "Level_11_Adjust_downward_100%" 12 "Reserved" 13 "Reserved" 14 "Reserved" 15 "Invalid" ;
VAL_ 890 ICC_MidLeOutlLeRiMotActvCmd 0 "No_Action" 1 "Level_1_to_the_left_100%" 2 "Level_2_to_the_left_80%" 3 "Level_3_left_adjustment_60%" 4 "Level_4_adjustment_to_the_left_40%" 5 "Level_5_to_the_left_20%" 6 "Level_6_positive_direction" 7 "Level_7_adjusted_to_the_right_by_20%" 8 "Level_8_adjustment_to_the_right_40%" 9 "Level_9_adjustment_to_the_right_60%" 10 "Level_10_adjust_80%_to_the_right" 11 "Level_11_adjusting_100%_to_the_right" 12 "Closed" 13 "Reserved" 14 "Reserved" 15 "Invalid" ;
VAL_ 890 ICC_MidLeOutlDamprMotActvCmd 0 "No_Action" 1 "Level_1_Throttle_opening_0%" 2 "Level_2_throttle_opening_10%" 3 "Level_3_Throttle_Opening_20%" 4 "Level_4_Throttle_Opening_30%" 5 "Level_5_Throttle_Opening_40%" 6 "Level_6_throttle_opening_50%" 7 "Level_7_throttle_opening_60%" 8 "Level_8_Throttle_70%" 9 "Level_9_throttle_opening_80%" 10 "Level_10_throttle_openning_90%" 11 "Level_11_throttle_opening_100%" 12 "Reserved" 13 "Reserved" 14 "Reserved" 15 "Invalid" ;
VAL_ 890 ICC_MidRiOutlUpDwnMotActvCmd 0 "No_Action" 1 "Level_1_upwards_by_100%" 2 "Level_2_upwards_80%" 3 "Level_3_upwards_60%" 4 "Level_4_upwards_40%" 5 "Level_5_up_20%" 6 "Level_6_positive_direction" 7 "Level_7_adjustment_downward_20%" 8 "Level_8_adjustment_downward_40%" 9 "Level_9_adjustment_downward_60%" 10 "Level_10_Adjustment_Downward_by_80%" 11 "Level_11_Adjust_downward_100%" 12 "Reserved" 13 "Reserved" 14 "Reserved" 15 "Invalid" ;
VAL_ 890 ICC_MidRiOutlLeRiMotActvCmd 0 "No_Action" 1 "Level_1_to_the_left_100%" 2 "Level_2_to_the_left_80%" 3 "Level_3_left_adjustment_60%" 4 "Level_4_adjustment_to_the_left_40%" 5 "Level_5_to_the_left_20%" 6 "Level_6_positive_direction" 7 "Level_7_adjusted_to_the_right_by_20%" 8 "Level_8_adjustment_to_the_right_40%" 9 "Level_9_adjustment_to_the_right_60%" 10 "Level_10_adjust_80%_to_the_right" 11 "Level_11_adjusting_100%_to_the_right" 12 "Closed" 13 "Reserved" 14 "Reserved" 15 "Invalid" ;
VAL_ 890 ICC_MidRiOutlDamprMotActvCmd 0 "No_Action" 1 "Level_1_Throttle_opening_0%" 2 "Level_2_throttle_opening_10%" 3 "Level_3_Throttle_Opening_20%" 4 "Level_4_Throttle_Opening_30%" 5 "Level_5_Throttle_Opening_40%" 6 "Level_6_throttle_opening_50%" 7 "Level_7_throttle_opening_60%" 8 "Level_8_Throttle_70%" 9 "Level_9_throttle_opening_80%" 10 "Level_10_throttle_openning_90%" 11 "Level_11_throttle_opening_100%" 12 "Reserved" 13 "Reserved" 14 "Reserved" 15 "Invalid" ;
VAL_ 890 ICC_RiOutlUpDwnMotActvCmd 0 "No_Action" 1 "Level_1_upwards_by_100%" 2 "Level_2_upwards_80%" 3 "Level_3_upwards_60%" 4 "Level_4_upwards_40%" 5 "Level_5_up_20%" 6 "Level_6_positive_direction" 7 "Level_7_adjustment_downward_20%" 8 "Level_8_adjustment_downward_40%" 9 "Level_9_adjustment_downward_60%" 10 "Level_10_Adjustment_Downward_by_80%" 11 "Level_11_Adjust_downward_100%" 12 "Reserved" 13 "Reserved" 14 "Reserved" 15 "Invalid" ;
VAL_ 890 ICC_RiOutlLeRiMotActvCmd 0 "No_Action" 1 "Level_1_to_the_left_100%" 2 "Level_2_to_the_left_80%" 3 "Level_3_left_adjustment_60%" 4 "Level_4_adjustment_to_the_left_40%" 5 "Level_5_to_the_left_20%" 6 "Level_6_positive_direction" 7 "Level_7_adjusted_to_the_right_by_20%" 8 "Level_8_adjustment_to_the_right_40%" 9 "Level_9_adjustment_to_the_right_60%" 10 "Level_10_adjust_80%_to_the_right" 11 "Level_11_adjusting_100%_to_the_right" 12 "Closed" 13 "Reserved" 14 "Reserved" 15 "Invalid" ;
VAL_ 890 ICC_RiOutlDamprMotActvCmd 0 "No_Action" 1 "Level_1_Throttle_opening_0%" 2 "Level_2_throttle_opening_10%" 3 "Level_3_Throttle_Opening_20%" 4 "Level_4_Throttle_Opening_30%" 5 "Level_5_Throttle_Opening_40%" 6 "Level_6_throttle_opening_50%" 7 "Level_7_throttle_opening_60%" 8 "Level_8_Throttle_70%" 9 "Level_9_throttle_opening_80%" 10 "Level_10_throttle_openning_90%" 11 "Level_11_throttle_opening_100%" 12 "Reserved" 13 "Reserved" 14 "Reserved" 15 "Invalid" ;
VAL_ 891 PKC_SysAlrmVld 0 "System_Warning_Invalid" 1 "System_Warning_Valid" ;
VAL_ 891 PKC_RemCtrlCmdFb 0 "Invalid" 1 "Successful" 2 "Failed" 3 "Processing" ;
VAL_ 891 PKC_RemLockCmd_Key 0 "Inactive" 1 "Lock" 2 "Reserved" 3 "Unlock" 4 "Tailgate_Release(Reserved)" 5 "Panic_(vehicle_finder)" 6 "Tailgate_active" 7 "Tailgate__hallt" 8 "Tailgate_window_UP" 9 "Tailgate_window_DOWN" 10 "California_Mode" 11 "Auto_Unlock" 12 "Auto_Lock" 13 "Reserved" 14 "Reserved" 15 "Reserved" ;
VAL_ 891 PKC_KeyStsMod 0 "Passvive" 1 "Active" ;
VAL_ 891 PKC_KeyID 0 "Initial" 1 "UID1" 2 "UID2" 3 "Reserved" 4 "Reserved" 5 "Reserved" 6 "Reserved" 7 "Reserved" ;
VAL_ 891 PKC_KeyInCarRmn 0 "No_Information" 1 "Key_In_Reminder" ;
VAL_ 891 PKC_RemLockCmd 0 "Inactive" 1 "Lock" 2 "Reserved" 3 "Unlock" 4 "Tailgate_Release(Reserved)" 5 "Panic_(vehicle_finder)" 6 "Tailgate_active" 7 "Tailgate_hallt" 8 "Tailgate_window_UP" 9 "Tailgate_window_DOWN" 10 "California_Mode" 11 "Auto_Unlock" 12 "Auto_Lock" 13 "Reserved" 14 "Reserved" 15 "Reserved" ;
VAL_ 891 PKC_BatterySts 0 "No_Information" 1 "UID_Low_Battery" 2 "Reserved" 3 "Invalid" ;
VAL_ 891 PKC_KeyOutdCarPromt 0 "No_Information" 1 "Key_Out_Reminder" ;
VAL_ 891 PKC_DoorOpenRmd 0 "Reserved" 1 "Active" 2 "Inactive" 3 "Invalid" ;
VAL_ 891 PKC_StrtFailTyp 0 "No_error" 1 "Reserved" 2 "VCU_Authentication_Failure" 3 "Time_Out_(Crank_Off_Time)" 4 "Auth_Pass" 5 "Reserved" 6 "Reserved" 7 "Reserved" 8 "Reserved" 9 "Reserved" 10 "Reserved" 11 "Reserved" 12 "Reserved" 13 "Reserved" 14 "Reserved" 15 "Reserved" ;
VAL_ 891 PKC_LockKeyInCarInd 0 "Reserved" 1 "Active" 2 "Inactive" 3 "Invalid" ;
VAL_ 891 PKC_KeySts 0 "Default_Value" 1 "UID_1_Is_Found" 2 "UID_2_Is_Found" 3 "UID_1,2_Is_Found" 4 "Reserved" 5 "Reserved" 6 "Reserved" 7 "Reserved" 8 "Reserved" 9 "Reserved" 10 "Reserved" 11 "Reserved" 12 "Reserved" 13 "Reserved" 14 "Reserved" 15 "Reserved" 16 "Reserved" 17 "Reserved" 18 "Reserved" 19 "Reserved" 20 "Reserved" 21 "Reserved" 22 "Reserved" 23 "Reserved" 24 "Reserved" 25 "Reserved" 26 "Reserved" 27 "Reserved" 28 "Reserved" 29 "Reserved" 30 "Reserved" 31 "Reserved" 32 "Reserved" 33 "Reserved" 34 "Reserved" 35 "Reserved" 36 "Reserved" 37 "Reserved" 38 "Reserved" 39 "Reserved" 40 "Reserved" 41 "Reserved" 42 "Reserved" 43 "Reserved" 44 "Reserved" 45 "Reserved" 46 "Reserved" 47 "Reserved" 48 "Reserved" 49 "Reserved" 50 "Reserved" 51 "Reserved" 52 "Reserved" 53 "Reserved" 54 "Reserved" 55 "Reserved" 56 "Reserved" 57 "Reserved" 58 "Reserved" 59 "Reserved" 60 "Reserved" 61 "Reserved" 62 "Reserved" 63 "Reserved" 64 "Reserved" 65 "Reserved" 66 "Reserved" 67 "Reserved" 68 "Reserved" 69 "Reserved" 70 "Reserved" 71 "Reserved" 72 "Reserved" 73 "Reserved" 74 "Reserved" 75 "Reserved" 76 "Reserved" 77 "Reserved" 78 "Reserved" 79 "Reserved" 80 "Reserved" 81 "Reserved" 82 "Reserved" 83 "Reserved" 84 "Reserved" 85 "Reserved" 86 "Reserved" 87 "Reserved" 88 "Reserved" 89 "Reserved" 90 "Reserved" 91 "Reserved" 92 "Reserved" 93 "Reserved" 94 "Reserved" 95 "Reserved" 96 "Reserved" 97 "Reserved" 98 "Reserved" 99 "Reserved" 100 "Reserved" 101 "Reserved" 102 "Reserved" 103 "Reserved" 104 "Reserved" 105 "Reserved" 106 "Reserved" 107 "Reserved" 108 "Reserved" 109 "Reserved" 110 "Reserved" 111 "Reserved" 112 "Reserved" 113 "Reserved" 114 "Reserved" 115 "Reserved" 116 "Reserved" 117 "Reserved" 118 "Reserved" 119 "Reserved" 120 "Reserved" 121 "Reserved" 122 "Reserved" 123 "Reserved" 124 "Reserved" 125 "Reserved" 126 "Reserved" 127 "Reserved" 128 "Reserved" 129 "Reserved" 130 "Reserved" 131 "Reserved" 132 "Reserved" 133 "Reserved" 134 "Reserved" 135 "Reserved" 136 "Reserved" 137 "Reserved" 138 "Reserved" 139 "Reserved" 140 "Reserved" 141 "Reserved" 142 "Reserved" 143 "Reserved" 144 "Reserved" 145 "Reserved" 146 "Reserved" 147 "Reserved" 148 "Reserved" 149 "Reserved" 150 "Reserved" 151 "Reserved" 152 "Reserved" 153 "Reserved" 154 "Reserved" 155 "Reserved" 156 "Reserved" 157 "Reserved" 158 "Reserved" 159 "Reserved" 160 "Reserved" 161 "Reserved" 162 "Reserved" 163 "Reserved" 164 "Reserved" 165 "Reserved" 166 "Reserved" 167 "Reserved" 168 "Reserved" 169 "Reserved" 170 "Reserved" 171 "Reserved" 172 "Reserved" 173 "Reserved" 174 "Reserved" 175 "Reserved" 176 "Reserved" 177 "Reserved" 178 "Reserved" 179 "Reserved" 180 "Reserved" 181 "Reserved" 182 "Reserved" 183 "Reserved" 184 "Reserved" 185 "Reserved" 186 "Reserved" 187 "Reserved" 188 "Reserved" 189 "Reserved" 190 "Reserved" 191 "Reserved" 192 "Reserved" 193 "Reserved" 194 "Reserved" 195 "Reserved" 196 "Reserved" 197 "Reserved" 198 "Reserved" 199 "Reserved" 200 "Reserved" 201 "Reserved" 202 "Reserved" 203 "Reserved" 204 "Reserved" 205 "Reserved" 206 "Reserved" 207 "Reserved" 208 "Reserved" 209 "Reserved" 210 "Reserved" 211 "Reserved" 212 "Reserved" 213 "Reserved" 214 "Reserved" 215 "Reserved" 216 "Reserved" 217 "Reserved" 218 "Reserved" 219 "Reserved" 220 "Reserved" 221 "Reserved" 222 "Reserved" 223 "Reserved" 224 "Reserved" 225 "Reserved" 226 "Reserved" 227 "Reserved" 228 "Reserved" 229 "Reserved" 230 "Reserved" 231 "Reserved" 232 "Reserved" 233 "Reserved" 234 "Reserved" 235 "Reserved" 236 "Reserved" 237 "Reserved" 238 "Reserved" 239 "Reserved" 240 "Reserved" 241 "Reserved" 242 "Reserved" 243 "Reserved" 244 "Reserved" 245 "Reserved" 246 "Reserved" 247 "Reserved" 248 "Reserved" 249 "Reserved" 250 "Reserved" 251 "Reserved" 252 "Reserved" 253 "Reserved" 254 "Reserved" 255 "Reserved" ;
VAL_ 897 RAC_OnOff 0 "No_Pressed" 1 "Pressed" 2 "Long_Press" 3 "Reserved" ;
VAL_ 897 RAC_ReOperPanSts 0 "off" 1 "on" ;
VAL_ 897 RAC_ReOperPanLockSts 0 "off" 1 "on" ;
VAL_ 897 RAC_BackRowAirOutlModReq 0 "Inactive" 1 "Rear_face_blowing" 2 "Face_blowing_foot_blowing_of_rear_row" 3 "Rear_row_foot_blowing" 4 "Rear_row_cutoff" 5 "Reserved" 6 "Reserved" 7 "Reserved" ;
VAL_ 897 RAC_VolInc 0 "No_Pressed" 1 "Pressed" 2 "Long_Press" 3 "Reserved" ;
VAL_ 897 RAC_VolDec 0 "No_Pressed" 1 "Pressed" 2 "Long_Press" 3 "Reserved" ;
VAL_ 897 RAC_VolCtrl 0 "Inactive" 1 "Unmute" 2 "Mute" 3 "Reserved" ;
VAL_ 897 RAC_TempCtrlnc 0 "No_Pressed" 1 "Pressed" 2 "Long_Press" 3 "Reserved" ;
VAL_ 897 RAC_TempCtrDec 0 "No_Pressed" 1 "Pressed" 2 "Long_Press" 3 "Reserved" ;
VAL_ 897 RAC_BlowCtrInc 0 "No_Pressed" 1 "Pressed" 2 "Long_Press" 3 "Reserved" ;
VAL_ 897 RAC_BlowCtrDec 0 "No_Pressed" 1 "Pressed" 2 "Long_Press" 3 "Reserved" ;
VAL_ 897 RAC_AirOutlLeftBtn 0 "No_Pressed" 1 "Pressed" 2 "Long_Press" 3 "Reserved" ;
VAL_ 897 RAC_AirOutlRightBtn 0 "No_Pressed" 1 "Pressed" 2 "Long_Press" 3 "Reserved" ;
VAL_ 897 RAC_SeatHRearLeftBtn 0 "No_Pressed" 1 "Pressed" 2 "Long_Press" 3 "Reserved" ;
VAL_ 897 RAC_SeatHRearRightBtn 0 "No_Pressed" 1 "Pressed" 2 "Long_Press" 3 "Reserved" ;
VAL_ 901 TBOX_PreHeatDepartTi1_Hr 31 "INVALID" ;
VAL_ 901 TBOX_PreHeatDepartTi1_Mins 63 "INVALID" ;
VAL_ 901 TBOX_PreHeatDepartSet 0 "init" 1 "Deactivated" 2 "Start_now" 3 "Start_with_timer" ;
VAL_ 901 TBOX_MonPreHeatDepartSet 0 "Not_repeated" 1 "Repeat" ;
VAL_ 901 TBOX_TuePreHeatDepartSet 0 "Not_repeated" 1 "Repeat" ;
VAL_ 901 TBOX_WedPreHeatDepartSet 0 "Not_repeated" 1 "Repeat" ;
VAL_ 901 TBOX_ThuPreHeatDepartSet 0 "Not_repeated" 1 "Repeat" ;
VAL_ 901 TBOX_FriPreHeatDepartSet 0 "Not_repeated" 1 "Repeat" ;
VAL_ 901 TBOX_SatPreHeatDepartSet 0 "Not_repeated" 1 "Repeat" ;
VAL_ 901 TBOX_SunPreHeatDepartSet 0 "Not_repeated" 1 "Repeat" ;
VAL_ 901 TBOX_PreCdnTarT 255 "Invalid" ;
VAL_ 901 TBOX_PreHeatDepartSetFb 0 "Invalid" 1 "Successful" 2 "Failed" 3 "Reserved" ;
VAL_ 901 TBOX_PreHeatDepartTi2_Hr 31 "INVALID" ;
VAL_ 901 TBOX_PreHeatDepartTi2_Mins 63 "INVALID" ;
VAL_ 928 BMS_Cont_Error_StuckOpen_HV_Pos1 0 "RelayOK" 1 "RelayOpen" ;
VAL_ 928 BMS_Cont_Error_Welded_HV_Pos1 0 "RelayOK" 1 "RelayWelded" ;
VAL_ 928 BMS_Cont_Error_Exceed_HV_Pos1 0 "CountersOK" 1 "CountersExceeded" ;
VAL_ 929 BMS_Cont_Error_StuckOpen_HV_Neg1 0 "RelayOK" 1 "RelayOpen" ;
VAL_ 929 BMS_Cont_Error_Welded_HV_Neg1 0 "RelayOK" 1 "RelayWelded" ;
VAL_ 929 BMS_Cont_Error_Exceed_HV_Neg1 0 "CountersOK" 1 "CountersExceeded" ;
VAL_ 930 BMS_Cont_Error_StuckOpen_HV_Prec 0 "RelayOK" 1 "RelayOpen" ;
VAL_ 930 BMS_Cont_Error_Welded_HV_Prec1 0 "RelayOK" 1 "RelayWelded" ;
VAL_ 930 BMS_Cont_Error_Exceed_HV_Prec 0 "CountersOK" 1 "CountersExceeded" ;
VAL_ 933 BMS_BattInlT_Target 255 "Invalid" ;
VAL_ 933 BMS_BattInlT_Min 255 "Invalid" ;
VAL_ 933 BMS_BattInlT_Max 255 "Invalid" ;
VAL_ 934 BMS_Cont_Error_StuckOpen_HV_PV_N 0 "RelayOK" 1 "RelayOpen" ;
VAL_ 934 BMS_Cont_Error_Welded_HV_PV_Neg1 0 "RelayOK" 1 "RelayWelded" ;
VAL_ 934 BMS_Cont_Error_Exceed_HV_PV_Neg1 0 "CountersOK" 1 "CountersExceeded" ;
VAL_ 935 BMS_Cont_Error_StuckOpen_HV_PV_P 0 "RelayOK" 1 "RelayOpen" ;
VAL_ 935 BMS_Cont_Error_Welded_HV_PV_Pos1 0 "RelayOK" 1 "RelayWelded" ;
VAL_ 935 BMS_Cont_Error_Exceed_HV_PV_Pos1 0 "CountersOK" 1 "CountersExceeded" ;
VAL_ 944 GW_OTARdy_Fb 0 "Initial" 1 "Ready" 2 "Not_Ready" 3 "Invalid" ;
VAL_ 944 GW_OTAInhbRdy 0 "Initial" 1 "Inhibit" 2 "Not_Inhibit" 3 "Invalid" ;
VAL_ 944 GW_UDSprohb 0 "On" 1 "Off" 2 "Invalid" ;
VAL_ 965 AMP_OTAInhbRdy 0 "Initial" 1 "Inhibit" 2 "Not_Inhibit" 3 "Invalid" ;
VAL_ 992 VCU_reqFullEDUCooltFlow 0 "Default" 1 "Active" 2 "Inactive" 3 "Invalid" ;
VAL_ 992 VCU_HVEMBoostModSt 0 "Default" 1 "Allowed" 2 "Denied" 3 "Invalid" ;
VAL_ 992 VCU_MaxBoostCntr 1023 "Invalid" ;
VAL_ 992 VCU_BoostEnStatCoded 8191 "Invalid" ;
VAL_ 1025 VCU_CtrlBitVector_Bit0_RMR 0 "Repeat_Message_State_not_requested" 1 "Repeat_Message_State_requested" ;
VAL_ 1025 VCU_CtrlBitVector_Bit3_NMCoord 0 "Start_of_synchronized_shutdown_is_not_requested_by_main_coordinator" 1 "Start_of_synchronized_shutdown_is_requested_by_main_coordinator" ;
VAL_ 1025 VCU_CtrlBitVector_Bit4_ActWake 0 "Node_has_not_woken_up_the_network_(passive_wakeup)" 1 "Node_has_woken_up_the_network_(active_Wakeup)" ;
VAL_ 1025 VCU_CtrlBitVector_Bit6_PNI 0 "NM_PDU_contains_no_Partial_Network_request_information" 1 "NM_PDU_contains_Partial_Network_request_information" ;
VAL_ 1025 VCU_UsrData0 0 "User_data_for_current_vehicle_without_partial_networking" 1 "User_data_for_current_vehicle_with_partial_networking" 255 "User_data_not_used" ;
VAL_ 1025 VCU_UsrData1_Bit0_IGN_WAKEUP 0 "inactive" 1 "active" ;
VAL_ 1025 VCU_UsrData1_Bit1_RESET_WAKEUP 0 "inactive" 1 "active" ;
VAL_ 1025 VCU_UsrData1_Bit2_NETWORK_WAKEUP 0 "inactive" 1 "active" ;
VAL_ 1025 VCU_UsrData1_Bit3_ECUSPEC_WAKEUP 0 "inactive" 1 "active" ;
VAL_ 1025 VCU_UsrData1_Bit4_NETWORK_AWAKE 0 "inactive" 1 "active" ;
VAL_ 1025 VCU_UsrData1_Bit5_IGNITION_AWAKE 0 "inactive" 1 "active" ;
VAL_ 1025 VCU_UsrData1_Bit6_DIAGN_AWAKE 0 "inactive" 1 "active" ;
VAL_ 1025 VCU_UsrData1_Bit7_ECUSPEC_AWAKE 0 "inactive" 1 "active" ;
VAL_ 1043 ECC_CtrlBitVector_Bit0_RMR 0 "Repeat_Message_State_not_requested" 1 "Repeat_Message_State_requested" ;
VAL_ 1043 ECC_CtrlBitVector_Bit3_NMCoord 0 "Start_of_synchronized_shutdown_is_not_requested_by_main_coordinator" 1 "Start_of_synchronized_shutdown_is_requested_by_main_coordinator" ;
VAL_ 1043 ECC_CtrlBitVector_Bit4_ActWake 0 "Node_has_not_woken_up_the_network_(passive_wakeup)" 1 "Node_has_woken_up_the_network_(active_Wakeup)" ;
VAL_ 1043 ECC_CtrlBitVector_Bit6_PNI 0 "NM_PDU_contains_no_Partial_Network_request_information" 1 "NM_PDU_contains_Partial_Network_request_information" ;
VAL_ 1043 ECC_UsrData0 0 "User_data_for_current_vehicle_without_partial_networking" 1 "User_data_for_current_vehicle_with_partial_networking" 255 "User_data_not_used" ;
VAL_ 1043 ECC_UsrData1_Bit0_IGN_WAKEUP 0 "inactive" 1 "active" ;
VAL_ 1043 ECC_UsrData1_Bit1_RESET_WAKEUP 0 "inactive" 1 "active" ;
VAL_ 1043 ECC_UsrData1_Bit2_NETWORK_WAKEUP 0 "inactive" 1 "active" ;
VAL_ 1043 ECC_UsrData1_Bit3_ECUSPEC_WAKEUP 0 "inactive" 1 "active" ;
VAL_ 1043 ECC_UsrData1_Bit4_NETWORK_AWAKE 0 "inactive" 1 "active" ;
VAL_ 1043 ECC_UsrData1_Bit5_IGNITION_AWAKE 0 "inactive" 1 "active" ;
VAL_ 1043 ECC_UsrData1_Bit6_DIAGN_AWAKE 0 "inactive" 1 "active" ;
VAL_ 1043 ECC_UsrData1_Bit7_ECUSPEC_AWAKE 0 "inactive" 1 "active" ;
